[part 1 of 2: package /ComponentTypes]
AUTOSAR XML (schema 00046)
package /ComponentTypes
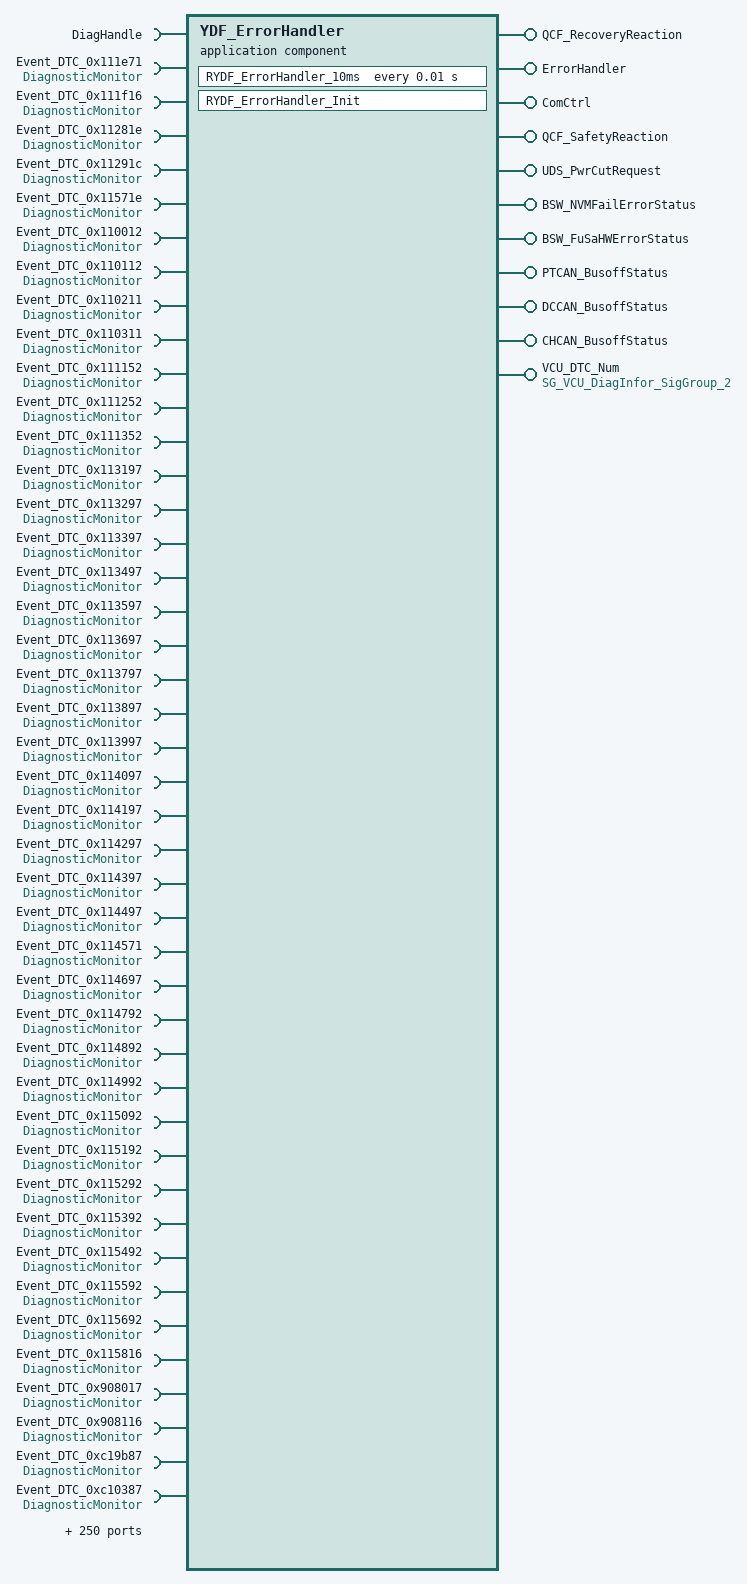
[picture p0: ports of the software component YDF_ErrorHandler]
  application sw component type YDF_ErrorHandler
    provide port QCF_RecoveryReaction: nonqueued-sender-com-spec{data-element=State, init-value=constant-reference=QCF_RECOVERY_REAC_DEFAULT}, provided-interface=QCF_RecoveryReaction
    provide port ErrorHandler: server-com-spec{operation=ReportError, queue-length=1}, provided-interface=ErrorHandler
    require port DiagHandle: required-com-specs=[SetEventSts, GetEventSts], required-interface=DiagHandle
    provide port ComCtrl: nonqueued-sender-com-spec=ComState, provided-interface=ComCtrl
    provide port QCF_SafetyReaction: nonqueued-sender-com-spec{data-element=State, init-value=constant-reference=QCF_SAFETY_REAC_DEFAULT}, provided-interface=QCF_SafetyReaction
    166 x require port:
      Event_DTC_0x111e71: required-interface=DiagnosticMonitor
        required-com-specs:
          GetEventExtendedDataRecordEx
          GetEventFreezeFrameDataEx
          GetFaultDetectionCounter
          GetDTCOfEvent
          GetEventTested
          GetEventFailed
          GetEventStatus
          GetEventUdsStatus
          ResetEventDebounceStatus
          ResetEventStatus
          SetEventStatus
      Event_DTC_0x111f16: required-interface=DiagnosticMonitor
        required-com-specs:
          GetEventExtendedDataRecordEx
          GetEventFreezeFrameDataEx
          GetFaultDetectionCounter
          GetDTCOfEvent
          GetEventTested
          GetEventFailed
          GetEventStatus
          GetEventUdsStatus
          ResetEventDebounceStatus
          ResetEventStatus
          SetEventStatus
      Event_DTC_0x11281e: required-interface=DiagnosticMonitor
        required-com-specs:
          GetEventExtendedDataRecordEx
          GetEventFreezeFrameDataEx
          GetFaultDetectionCounter
          GetDTCOfEvent
          GetEventTested
          GetEventFailed
          GetEventStatus
          GetEventUdsStatus
          ResetEventDebounceStatus
          ResetEventStatus
          SetEventStatus
      Event_DTC_0x11291c: required-interface=DiagnosticMonitor
        required-com-specs:
          GetEventExtendedDataRecordEx
          GetEventFreezeFrameDataEx
          GetFaultDetectionCounter
          GetDTCOfEvent
          GetEventTested
          GetEventFailed
          GetEventStatus
          GetEventUdsStatus
          ResetEventDebounceStatus
          ResetEventStatus
          SetEventStatus
      Event_DTC_0x11571e: required-interface=DiagnosticMonitor
        required-com-specs:
          GetEventExtendedDataRecordEx
          GetEventFreezeFrameDataEx
          GetFaultDetectionCounter
          GetDTCOfEvent
          GetEventTested
          GetEventFailed
          GetEventStatus
          GetEventUdsStatus
          ResetEventDebounceStatus
          ResetEventStatus
          SetEventStatus
      Event_DTC_0x110012: required-interface=DiagnosticMonitor
        required-com-specs:
          GetEventExtendedDataRecordEx
          GetEventFreezeFrameDataEx
          GetFaultDetectionCounter
          GetDTCOfEvent
          GetEventTested
          GetEventFailed
          GetEventStatus
          GetEventUdsStatus
          ResetEventDebounceStatus
          ResetEventStatus
          SetEventStatus
      Event_DTC_0x110112: required-interface=DiagnosticMonitor
        required-com-specs:
          GetEventExtendedDataRecordEx
          GetEventFreezeFrameDataEx
          GetFaultDetectionCounter
          GetDTCOfEvent
          GetEventTested
          GetEventFailed
          GetEventStatus
          GetEventUdsStatus
          ResetEventDebounceStatus
          ResetEventStatus
          SetEventStatus
      Event_DTC_0x110211: required-interface=DiagnosticMonitor
        required-com-specs:
          GetEventExtendedDataRecordEx
          GetEventFreezeFrameDataEx
          GetFaultDetectionCounter
          GetDTCOfEvent
          GetEventTested
          GetEventFailed
          GetEventStatus
          GetEventUdsStatus
          ResetEventDebounceStatus
          ResetEventStatus
          SetEventStatus
      Event_DTC_0x110311: required-interface=DiagnosticMonitor
        required-com-specs:
          GetEventExtendedDataRecordEx
          GetEventFreezeFrameDataEx
          GetFaultDetectionCounter
          GetDTCOfEvent
          GetEventTested
          GetEventFailed
          GetEventStatus
          GetEventUdsStatus
          ResetEventDebounceStatus
          ResetEventStatus
          SetEventStatus
      Event_DTC_0x111152: required-interface=DiagnosticMonitor
        required-com-specs:
          GetEventExtendedDataRecordEx
          GetEventFreezeFrameDataEx
          GetFaultDetectionCounter
          GetDTCOfEvent
          GetEventTested
          GetEventFailed
          GetEventStatus
          GetEventUdsStatus
          ResetEventDebounceStatus
          ResetEventStatus
          SetEventStatus
      Event_DTC_0x111252: required-interface=DiagnosticMonitor
        required-com-specs:
          GetEventExtendedDataRecordEx
          GetEventFreezeFrameDataEx
          GetFaultDetectionCounter
          GetDTCOfEvent
          GetEventTested
          GetEventFailed
          GetEventStatus
          GetEventUdsStatus
          ResetEventDebounceStatus
          ResetEventStatus
          SetEventStatus
      Event_DTC_0x111352: required-interface=DiagnosticMonitor
        required-com-specs:
          GetEventExtendedDataRecordEx
          GetEventFreezeFrameDataEx
          GetFaultDetectionCounter
          GetDTCOfEvent
          GetEventTested
          GetEventFailed
          GetEventStatus
          GetEventUdsStatus
          ResetEventDebounceStatus
          ResetEventStatus
          SetEventStatus
      Event_DTC_0x113197: required-interface=DiagnosticMonitor
        required-com-specs:
          GetEventExtendedDataRecordEx
          GetEventFreezeFrameDataEx
          GetFaultDetectionCounter
          GetDTCOfEvent
          GetEventTested
          GetEventFailed
          GetEventStatus
          GetEventUdsStatus
          ResetEventDebounceStatus
          ResetEventStatus
          SetEventStatus
      Event_DTC_0x113297: required-interface=DiagnosticMonitor
        required-com-specs:
          GetEventExtendedDataRecordEx
          GetEventFreezeFrameDataEx
          GetFaultDetectionCounter
          GetDTCOfEvent
          GetEventTested
          GetEventFailed
          GetEventStatus
          GetEventUdsStatus
          ResetEventDebounceStatus
          ResetEventStatus
          SetEventStatus
      Event_DTC_0x113397: required-interface=DiagnosticMonitor
        required-com-specs:
          GetEventExtendedDataRecordEx
          GetEventFreezeFrameDataEx
          GetFaultDetectionCounter
          GetDTCOfEvent
          GetEventTested
          GetEventFailed
          GetEventStatus
          GetEventUdsStatus
          ResetEventDebounceStatus
          ResetEventStatus
          SetEventStatus
      Event_DTC_0x113497: required-interface=DiagnosticMonitor
        required-com-specs:
          GetEventExtendedDataRecordEx
          GetEventFreezeFrameDataEx
          GetFaultDetectionCounter
          GetDTCOfEvent
          GetEventTested
          GetEventFailed
          GetEventStatus
          GetEventUdsStatus
          ResetEventDebounceStatus
          ResetEventStatus
          SetEventStatus
      Event_DTC_0x113597: required-interface=DiagnosticMonitor
        required-com-specs:
          GetEventExtendedDataRecordEx
          GetEventFreezeFrameDataEx
          GetFaultDetectionCounter
          GetDTCOfEvent
          GetEventTested
          GetEventFailed
          GetEventStatus
          GetEventUdsStatus
          ResetEventDebounceStatus
          ResetEventStatus
          SetEventStatus
      Event_DTC_0x113697: required-interface=DiagnosticMonitor
        required-com-specs:
          GetEventExtendedDataRecordEx
          GetEventFreezeFrameDataEx
          GetFaultDetectionCounter
          GetDTCOfEvent
          GetEventTested
          GetEventFailed
          GetEventStatus
          GetEventUdsStatus
          ResetEventDebounceStatus
          ResetEventStatus
          SetEventStatus
      Event_DTC_0x113797: required-interface=DiagnosticMonitor
        required-com-specs:
          GetEventExtendedDataRecordEx
          GetEventFreezeFrameDataEx
          GetFaultDetectionCounter
          GetDTCOfEvent
          GetEventTested
          GetEventFailed
          GetEventStatus
          GetEventUdsStatus
          ResetEventDebounceStatus
          ResetEventStatus
          SetEventStatus
      Event_DTC_0x113897: required-interface=DiagnosticMonitor
        required-com-specs:
          GetEventExtendedDataRecordEx
          GetEventFreezeFrameDataEx
          GetFaultDetectionCounter
          GetDTCOfEvent
          GetEventTested
          GetEventFailed
          GetEventStatus
          GetEventUdsStatus
          ResetEventDebounceStatus
          ResetEventStatus
          SetEventStatus
      Event_DTC_0x113997: required-interface=DiagnosticMonitor
        required-com-specs:
          GetEventExtendedDataRecordEx
          GetEventFreezeFrameDataEx
          GetFaultDetectionCounter
          GetDTCOfEvent
          GetEventTested
          GetEventFailed
          GetEventStatus
          GetEventUdsStatus
          ResetEventDebounceStatus
          ResetEventStatus
          SetEventStatus
      Event_DTC_0x114097: required-interface=DiagnosticMonitor
        required-com-specs:
          GetEventExtendedDataRecordEx
          GetEventFreezeFrameDataEx
          GetFaultDetectionCounter
          GetDTCOfEvent
          GetEventTested
          GetEventFailed
          GetEventStatus
          GetEventUdsStatus
          ResetEventDebounceStatus
          ResetEventStatus
          SetEventStatus
      Event_DTC_0x114197: required-interface=DiagnosticMonitor
        required-com-specs:
          GetEventExtendedDataRecordEx
          GetEventFreezeFrameDataEx
          GetFaultDetectionCounter
          GetDTCOfEvent
          GetEventTested
          GetEventFailed
          GetEventStatus
          GetEventUdsStatus
          ResetEventDebounceStatus
          ResetEventStatus
          SetEventStatus
      Event_DTC_0x114297: required-interface=DiagnosticMonitor
        required-com-specs:
          GetEventExtendedDataRecordEx
          GetEventFreezeFrameDataEx
          GetFaultDetectionCounter
          GetDTCOfEvent
          GetEventTested
          GetEventFailed
          GetEventStatus
          GetEventUdsStatus
          ResetEventDebounceStatus
          ResetEventStatus
          SetEventStatus
      Event_DTC_0x114397: required-interface=DiagnosticMonitor
        required-com-specs:
          GetEventExtendedDataRecordEx
          GetEventFreezeFrameDataEx
          GetFaultDetectionCounter
          GetDTCOfEvent
          GetEventTested
          GetEventFailed
          GetEventStatus
          GetEventUdsStatus
          ResetEventDebounceStatus
          ResetEventStatus
          SetEventStatus
      Event_DTC_0x114497: required-interface=DiagnosticMonitor
        required-com-specs:
          GetEventExtendedDataRecordEx
          GetEventFreezeFrameDataEx
          GetFaultDetectionCounter
          GetDTCOfEvent
          GetEventTested
          GetEventFailed
          GetEventStatus
          GetEventUdsStatus
          ResetEventDebounceStatus
          ResetEventStatus
          SetEventStatus
      Event_DTC_0x114571: required-interface=DiagnosticMonitor
        required-com-specs:
          GetEventExtendedDataRecordEx
          GetEventFreezeFrameDataEx
          GetFaultDetectionCounter
          GetDTCOfEvent
          GetEventTested
          GetEventFailed
          GetEventStatus
          GetEventUdsStatus
          ResetEventDebounceStatus
          ResetEventStatus
          SetEventStatus
      Event_DTC_0x114697: required-interface=DiagnosticMonitor
        required-com-specs:
          GetEventExtendedDataRecordEx
          GetEventFreezeFrameDataEx
          GetFaultDetectionCounter
          GetDTCOfEvent
          GetEventTested
          GetEventFailed
          GetEventStatus
          GetEventUdsStatus
          ResetEventDebounceStatus
          ResetEventStatus
          SetEventStatus
      Event_DTC_0x114792: required-interface=DiagnosticMonitor
        required-com-specs:
          GetEventExtendedDataRecordEx
          GetEventFreezeFrameDataEx
          GetFaultDetectionCounter
          GetDTCOfEvent
          GetEventTested
          GetEventFailed
          GetEventStatus
          GetEventUdsStatus
          ResetEventDebounceStatus
          ResetEventStatus
          SetEventStatus
      Event_DTC_0x114892: required-interface=DiagnosticMonitor
        required-com-specs:
          GetEventExtendedDataRecordEx
          GetEventFreezeFrameDataEx
          GetFaultDetectionCounter
          GetDTCOfEvent
          GetEventTested
          GetEventFailed
          GetEventStatus
          GetEventUdsStatus
          ResetEventDebounceStatus
          ResetEventStatus
          SetEventStatus
      Event_DTC_0x114992: required-interface=DiagnosticMonitor
        required-com-specs:
          GetEventExtendedDataRecordEx
          GetEventFreezeFrameDataEx
          GetFaultDetectionCounter
          GetDTCOfEvent
          GetEventTested
          GetEventFailed
          GetEventStatus
          GetEventUdsStatus
          ResetEventDebounceStatus
          ResetEventStatus
          SetEventStatus
      Event_DTC_0x115092: required-interface=DiagnosticMonitor
        required-com-specs:
          GetEventExtendedDataRecordEx
          GetEventFreezeFrameDataEx
          GetFaultDetectionCounter
          GetDTCOfEvent
          GetEventTested
          GetEventFailed
          GetEventStatus
          GetEventUdsStatus
          ResetEventDebounceStatus
          ResetEventStatus
          SetEventStatus
      Event_DTC_0x115192: required-interface=DiagnosticMonitor
        required-com-specs:
          GetEventExtendedDataRecordEx
          GetEventFreezeFrameDataEx
          GetFaultDetectionCounter
          GetDTCOfEvent
          GetEventTested
          GetEventFailed
          GetEventStatus
          GetEventUdsStatus
          ResetEventDebounceStatus
          ResetEventStatus
          SetEventStatus
      Event_DTC_0x115292: required-interface=DiagnosticMonitor
        required-com-specs:
          GetEventExtendedDataRecordEx
          GetEventFreezeFrameDataEx
          GetFaultDetectionCounter
          GetDTCOfEvent
          GetEventTested
          GetEventFailed
          GetEventStatus
          GetEventUdsStatus
          ResetEventDebounceStatus
          ResetEventStatus
          SetEventStatus
      Event_DTC_0x115392: required-interface=DiagnosticMonitor
        required-com-specs:
          GetEventExtendedDataRecordEx
          GetEventFreezeFrameDataEx
          GetFaultDetectionCounter
          GetDTCOfEvent
          GetEventTested
          GetEventFailed
          GetEventStatus
          GetEventUdsStatus
          ResetEventDebounceStatus
          ResetEventStatus
          SetEventStatus
      Event_DTC_0x115492: required-interface=DiagnosticMonitor
        required-com-specs:
          GetEventExtendedDataRecordEx
          GetEventFreezeFrameDataEx
          GetFaultDetectionCounter
          GetDTCOfEvent
          GetEventTested
          GetEventFailed
          GetEventStatus
          GetEventUdsStatus
          ResetEventDebounceStatus
          ResetEventStatus
          SetEventStatus
      Event_DTC_0x115592: required-interface=DiagnosticMonitor
        required-com-specs:
          GetEventExtendedDataRecordEx
          GetEventFreezeFrameDataEx
          GetFaultDetectionCounter
          GetDTCOfEvent
          GetEventTested
          GetEventFailed
          GetEventStatus
          GetEventUdsStatus
          ResetEventDebounceStatus
          ResetEventStatus
          SetEventStatus
      Event_DTC_0x115692: required-interface=DiagnosticMonitor
        required-com-specs:
          GetEventExtendedDataRecordEx
          GetEventFreezeFrameDataEx
          GetFaultDetectionCounter
          GetDTCOfEvent
          GetEventTested
          GetEventFailed
          GetEventStatus
          GetEventUdsStatus
          ResetEventDebounceStatus
          ResetEventStatus
          SetEventStatus
      Event_DTC_0x115816: required-interface=DiagnosticMonitor
        required-com-specs:
          GetEventExtendedDataRecordEx
          GetEventFreezeFrameDataEx
          GetFaultDetectionCounter
          GetDTCOfEvent
          GetEventTested
          GetEventFailed
          GetEventStatus
          GetEventUdsStatus
          ResetEventDebounceStatus
          ResetEventStatus
          SetEventStatus
      Event_DTC_0x908017: required-interface=DiagnosticMonitor
        required-com-specs:
          GetEventExtendedDataRecordEx
          GetEventFreezeFrameDataEx
          GetFaultDetectionCounter
          GetDTCOfEvent
          GetEventTested
          GetEventFailed
          GetEventStatus
          GetEventUdsStatus
          ResetEventDebounceStatus
          ResetEventStatus
          SetEventStatus
      Event_DTC_0x908116: required-interface=DiagnosticMonitor
        required-com-specs:
          GetEventExtendedDataRecordEx
          GetEventFreezeFrameDataEx
          GetFaultDetectionCounter
          GetDTCOfEvent
          GetEventTested
          GetEventFailed
          GetEventStatus
          GetEventUdsStatus
          ResetEventDebounceStatus
          ResetEventStatus
          SetEventStatus
      Event_DTC_0xc19b87: required-interface=DiagnosticMonitor
        required-com-specs:
          GetEventExtendedDataRecordEx
          GetEventFreezeFrameDataEx
          GetFaultDetectionCounter
          GetDTCOfEvent
          GetEventTested
          GetEventFailed
          GetEventStatus
          GetEventUdsStatus
          ResetEventDebounceStatus
          ResetEventStatus
          SetEventStatus
      Event_DTC_0xc10387: required-interface=DiagnosticMonitor
        required-com-specs:
          GetEventExtendedDataRecordEx
          GetEventFreezeFrameDataEx
          GetFaultDetectionCounter
          GetDTCOfEvent
          GetEventTested
          GetEventFailed
          GetEventStatus
          GetEventUdsStatus
          ResetEventDebounceStatus
          ResetEventStatus
          SetEventStatus
      Event_DTC_0xc11087: required-interface=DiagnosticMonitor
        required-com-specs:
          GetEventExtendedDataRecordEx
          GetEventFreezeFrameDataEx
          GetFaultDetectionCounter
          GetDTCOfEvent
          GetEventTested
          GetEventFailed
          GetEventStatus
          GetEventUdsStatus
          ResetEventDebounceStatus
          ResetEventStatus
          SetEventStatus
      Event_DTC_0xc11187: required-interface=DiagnosticMonitor
        required-com-specs:
          GetEventExtendedDataRecordEx
          GetEventFreezeFrameDataEx
          GetFaultDetectionCounter
          GetDTCOfEvent
          GetEventTested
          GetEventFailed
          GetEventStatus
          GetEventUdsStatus
          ResetEventDebounceStatus
          ResetEventStatus
          SetEventStatus
      Event_DTC_0xc12987: required-interface=DiagnosticMonitor
        required-com-specs:
          GetEventExtendedDataRecordEx
          GetEventFreezeFrameDataEx
          GetFaultDetectionCounter
          GetDTCOfEvent
          GetEventTested
          GetEventFailed
          GetEventStatus
          GetEventUdsStatus
          ResetEventDebounceStatus
          ResetEventStatus
          SetEventStatus
      Event_DTC_0xc14087: required-interface=DiagnosticMonitor
        required-com-specs:
          GetEventExtendedDataRecordEx
          GetEventFreezeFrameDataEx
          GetFaultDetectionCounter
          GetDTCOfEvent
          GetEventTested
          GetEventFailed
          GetEventStatus
          GetEventUdsStatus
          ResetEventDebounceStatus
          ResetEventStatus
          SetEventStatus
      Event_DTC_0xc14787: required-interface=DiagnosticMonitor
        required-com-specs:
          GetEventExtendedDataRecordEx
          GetEventFreezeFrameDataEx
          GetFaultDetectionCounter
          GetDTCOfEvent
          GetEventTested
          GetEventFailed
          GetEventStatus
          GetEventUdsStatus
          ResetEventDebounceStatus
          ResetEventStatus
          SetEventStatus
      Event_DTC_0xc16687: required-interface=DiagnosticMonitor
        required-com-specs:
          GetEventExtendedDataRecordEx
          GetEventFreezeFrameDataEx
          GetFaultDetectionCounter
          GetDTCOfEvent
          GetEventTested
          GetEventFailed
          GetEventStatus
          GetEventUdsStatus
          ResetEventDebounceStatus
          ResetEventStatus
          SetEventStatus
      Event_DTC_0xc19687: required-interface=DiagnosticMonitor
        required-com-specs:
          GetEventExtendedDataRecordEx
          GetEventFreezeFrameDataEx
          GetFaultDetectionCounter
          GetDTCOfEvent
          GetEventTested
          GetEventFailed
          GetEventStatus
          GetEventUdsStatus
          ResetEventDebounceStatus
          ResetEventStatus
          SetEventStatus
      Event_DTC_0xc19987: required-interface=DiagnosticMonitor
        required-com-specs:
          GetEventExtendedDataRecordEx
          GetEventFreezeFrameDataEx
          GetFaultDetectionCounter
          GetDTCOfEvent
          GetEventTested
          GetEventFailed
          GetEventStatus
          GetEventUdsStatus
          ResetEventDebounceStatus
          ResetEventStatus
          SetEventStatus
      Event_DTC_0xc29887: required-interface=DiagnosticMonitor
        required-com-specs:
          GetEventExtendedDataRecordEx
          GetEventFreezeFrameDataEx
          GetFaultDetectionCounter
          GetDTCOfEvent
          GetEventTested
          GetEventFailed
          GetEventStatus
          GetEventUdsStatus
          ResetEventDebounceStatus
          ResetEventStatus
          SetEventStatus
      Event_DTC_0xd10587: required-interface=DiagnosticMonitor
        required-com-specs:
          GetEventExtendedDataRecordEx
          GetEventFreezeFrameDataEx
          GetFaultDetectionCounter
          GetDTCOfEvent
          GetEventTested
          GetEventFailed
          GetEventStatus
          GetEventUdsStatus
          ResetEventDebounceStatus
          ResetEventStatus
          SetEventStatus
      Event_DTC_0xd13787: required-interface=DiagnosticMonitor
        required-com-specs:
          GetEventExtendedDataRecordEx
          GetEventFreezeFrameDataEx
          GetFaultDetectionCounter
          GetDTCOfEvent
          GetEventTested
          GetEventFailed
          GetEventStatus
          GetEventUdsStatus
          ResetEventDebounceStatus
          ResetEventStatus
          SetEventStatus
      EvtInfo_DTC_0xd13787: required-interface=DiagnosticInfo
        required-com-specs:
          GetMonitorStatus
          GetDebouncingOfEvent
          GetEventEnableCondition
          GetEventExtendedDataRecordEx
          GetEventFreezeFrameDataEx
          GetFaultDetectionCounter
          GetDTCOfEvent
          GetEventTested
          GetEventFailed
          GetEventStatus
          GetEventUdsStatus
      Event_DTC_0xd11b87: required-interface=DiagnosticMonitor
        required-com-specs:
          GetEventExtendedDataRecordEx
          GetEventFreezeFrameDataEx
          GetFaultDetectionCounter
          GetDTCOfEvent
          GetEventTested
          GetEventFailed
          GetEventStatus
          GetEventUdsStatus
          ResetEventDebounceStatus
          ResetEventStatus
          SetEventStatus
      EvtInfo_DTC_0xd11b87: required-interface=DiagnosticInfo
        required-com-specs:
          GetMonitorStatus
          GetDebouncingOfEvent
          GetEventEnableCondition
          GetEventExtendedDataRecordEx
          GetEventFreezeFrameDataEx
          GetFaultDetectionCounter
          GetDTCOfEvent
          GetEventTested
          GetEventFailed
          GetEventStatus
          GetEventUdsStatus
      EvtInfo_DTC_0xd30087: required-interface=DiagnosticInfo
        required-com-specs:
          GetMonitorStatus
          GetDebouncingOfEvent
          GetEventEnableCondition
          GetEventExtendedDataRecordEx
          GetEventFreezeFrameDataEx
          GetFaultDetectionCounter
          GetDTCOfEvent
          GetEventTested
          GetEventFailed
          GetEventStatus
          GetEventUdsStatus
      Event_DTC_0xd30087: required-interface=DiagnosticMonitor
        required-com-specs:
          GetEventExtendedDataRecordEx
          GetEventFreezeFrameDataEx
          GetFaultDetectionCounter
          GetDTCOfEvent
          GetEventTested
          GetEventFailed
          GetEventStatus
          GetEventUdsStatus
          ResetEventDebounceStatus
          ResetEventStatus
          SetEventStatus
      EvtInfo_DTC_0xc14687: required-interface=DiagnosticInfo
        required-com-specs:
          GetMonitorStatus
          GetDebouncingOfEvent
          GetEventEnableCondition
          GetEventExtendedDataRecordEx
          GetEventFreezeFrameDataEx
          GetFaultDetectionCounter
          GetDTCOfEvent
          GetEventTested
          GetEventFailed
          GetEventStatus
          GetEventUdsStatus
      Event_DTC_0xc14687: required-interface=DiagnosticMonitor
        required-com-specs:
          GetEventExtendedDataRecordEx
          GetEventFreezeFrameDataEx
          GetFaultDetectionCounter
          GetDTCOfEvent
          GetEventTested
          GetEventFailed
          GetEventStatus
          GetEventUdsStatus
          ResetEventDebounceStatus
          ResetEventStatus
          SetEventStatus
      EvtInfo_DTC_0xc10f87: required-interface=DiagnosticInfo
        required-com-specs:
          GetMonitorStatus
          GetDebouncingOfEvent
          GetEventEnableCondition
          GetEventExtendedDataRecordEx
          GetEventFreezeFrameDataEx
          GetFaultDetectionCounter
          GetDTCOfEvent
          GetEventTested
          GetEventFailed
          GetEventStatus
          GetEventUdsStatus
      Event_DTC_0xc10f87: required-interface=DiagnosticMonitor
        required-com-specs:
          GetEventExtendedDataRecordEx
          GetEventFreezeFrameDataEx
          GetFaultDetectionCounter
          GetDTCOfEvent
          GetEventTested
          GetEventFailed
          GetEventStatus
          GetEventUdsStatus
          ResetEventDebounceStatus
          ResetEventStatus
          SetEventStatus
      EvtInfo_DTC_0xc16b87: required-interface=DiagnosticInfo
        required-com-specs:
          GetMonitorStatus
          GetDebouncingOfEvent
          GetEventEnableCondition
          GetEventExtendedDataRecordEx
          GetEventFreezeFrameDataEx
          GetFaultDetectionCounter
          GetDTCOfEvent
          GetEventTested
          GetEventFailed
          GetEventStatus
          GetEventUdsStatus
      Event_DTC_0xc16b87: required-interface=DiagnosticMonitor
        required-com-specs:
          GetEventExtendedDataRecordEx
          GetEventFreezeFrameDataEx
          GetFaultDetectionCounter
          GetDTCOfEvent
          GetEventTested
          GetEventFailed
          GetEventStatus
          GetEventUdsStatus
          ResetEventDebounceStatus
          ResetEventStatus
          SetEventStatus
      EvtInfo_DTC_0x908255: required-interface=DiagnosticInfo
        required-com-specs:
          GetMonitorStatus
          GetDebouncingOfEvent
          GetEventEnableCondition
          GetEventExtendedDataRecordEx
          GetEventFreezeFrameDataEx
          GetFaultDetectionCounter
          GetDTCOfEvent
          GetEventTested
          GetEventFailed
          GetEventStatus
          GetEventUdsStatus
      Event_DTC_0x908255: required-interface=DiagnosticMonitor
        required-com-specs:
          GetEventExtendedDataRecordEx
          GetEventFreezeFrameDataEx
          GetFaultDetectionCounter
          GetDTCOfEvent
          GetEventTested
          GetEventFailed
          GetEventStatus
          GetEventUdsStatus
          ResetEventDebounceStatus
          ResetEventStatus
          SetEventStatus
      EvtInfo_DTC_0x908356: required-interface=DiagnosticInfo
        required-com-specs:
          GetMonitorStatus
          GetDebouncingOfEvent
          GetEventEnableCondition
          GetEventExtendedDataRecordEx
          GetEventFreezeFrameDataEx
          GetFaultDetectionCounter
          GetDTCOfEvent
          GetEventTested
          GetEventFailed
          GetEventStatus
          GetEventUdsStatus
      Event_DTC_0x908356: required-interface=DiagnosticMonitor
        required-com-specs:
          GetEventExtendedDataRecordEx
          GetEventFreezeFrameDataEx
          GetFaultDetectionCounter
          GetDTCOfEvent
          GetEventTested
          GetEventFailed
          GetEventStatus
          GetEventUdsStatus
          ResetEventDebounceStatus
          ResetEventStatus
          SetEventStatus
      EvtInfo_DTC_0x117097: required-interface=DiagnosticInfo
        required-com-specs:
          GetMonitorStatus
          GetDebouncingOfEvent
          GetEventEnableCondition
          GetEventExtendedDataRecordEx
          GetEventFreezeFrameDataEx
          GetFaultDetectionCounter
          GetDTCOfEvent
          GetEventTested
          GetEventFailed
          GetEventStatus
          GetEventUdsStatus
      Event_DTC_0x117097: required-interface=DiagnosticMonitor
        required-com-specs:
          GetEventExtendedDataRecordEx
          GetEventFreezeFrameDataEx
          GetFaultDetectionCounter
          GetDTCOfEvent
          GetEventTested
          GetEventFailed
          GetEventStatus
          GetEventUdsStatus
          ResetEventDebounceStatus
          ResetEventStatus
          SetEventStatus
      EvtInfo_DTC_0x116097: required-interface=DiagnosticInfo
        required-com-specs:
          GetMonitorStatus
          GetDebouncingOfEvent
          GetEventEnableCondition
          GetEventExtendedDataRecordEx
          GetEventFreezeFrameDataEx
          GetFaultDetectionCounter
          GetDTCOfEvent
          GetEventTested
          GetEventFailed
          GetEventStatus
          GetEventUdsStatus
      Event_DTC_0x116097: required-interface=DiagnosticMonitor
        required-com-specs:
          GetEventExtendedDataRecordEx
          GetEventFreezeFrameDataEx
          GetFaultDetectionCounter
          GetDTCOfEvent
          GetEventTested
          GetEventFailed
          GetEventStatus
          GetEventUdsStatus
          ResetEventDebounceStatus
          ResetEventStatus
          SetEventStatus
      EvtInfo_DTC_0x115c4b: required-interface=DiagnosticInfo
        required-com-specs:
          GetMonitorStatus
          GetDebouncingOfEvent
          GetEventEnableCondition
          GetEventExtendedDataRecordEx
          GetEventFreezeFrameDataEx
          GetFaultDetectionCounter
          GetDTCOfEvent
          GetEventTested
          GetEventFailed
          GetEventStatus
          GetEventUdsStatus
      Event_DTC_0x115c4b: required-interface=DiagnosticMonitor
        required-com-specs:
          GetEventExtendedDataRecordEx
          GetEventFreezeFrameDataEx
          GetFaultDetectionCounter
          GetDTCOfEvent
          GetEventTested
          GetEventFailed
          GetEventStatus
          GetEventUdsStatus
          ResetEventDebounceStatus
          ResetEventStatus
          SetEventStatus
      EvtInfo_DTC_0x115d4b: required-interface=DiagnosticInfo
        required-com-specs:
          GetMonitorStatus
          GetDebouncingOfEvent
          GetEventEnableCondition
          GetEventExtendedDataRecordEx
          GetEventFreezeFrameDataEx
          GetFaultDetectionCounter
          GetDTCOfEvent
          GetEventTested
          GetEventFailed
          GetEventStatus
          GetEventUdsStatus
      Event_DTC_0x115d4b: required-interface=DiagnosticMonitor
        required-com-specs:
          GetEventExtendedDataRecordEx
          GetEventFreezeFrameDataEx
          GetFaultDetectionCounter
          GetDTCOfEvent
          GetEventTested
          GetEventFailed
          GetEventStatus
          GetEventUdsStatus
          ResetEventDebounceStatus
          ResetEventStatus
          SetEventStatus
      EvtInfo_DTC_0x117197: required-interface=DiagnosticInfo
        required-com-specs:
          GetMonitorStatus
          GetDebouncingOfEvent
          GetEventEnableCondition
          GetEventExtendedDataRecordEx
          GetEventFreezeFrameDataEx
          GetFaultDetectionCounter
          GetDTCOfEvent
          GetEventTested
          GetEventFailed
          GetEventStatus
          GetEventUdsStatus
      Event_DTC_0x117197: required-interface=DiagnosticMonitor
        required-com-specs:
          GetEventExtendedDataRecordEx
          GetEventFreezeFrameDataEx
          GetFaultDetectionCounter
          GetDTCOfEvent
          GetEventTested
          GetEventFailed
          GetEventStatus
          GetEventUdsStatus
          ResetEventDebounceStatus
          ResetEventStatus
          SetEventStatus
      EvtInfo_DTC_0x115e1a: required-interface=DiagnosticInfo
        required-com-specs:
          GetMonitorStatus
          GetDebouncingOfEvent
          GetEventEnableCondition
          GetEventExtendedDataRecordEx
          GetEventFreezeFrameDataEx
          GetFaultDetectionCounter
          GetDTCOfEvent
          GetEventTested
          GetEventFailed
          GetEventStatus
          GetEventUdsStatus
      Event_DTC_0x115e1a: required-interface=DiagnosticMonitor
        required-com-specs:
          GetEventExtendedDataRecordEx
          GetEventFreezeFrameDataEx
          GetFaultDetectionCounter
          GetDTCOfEvent
          GetEventTested
          GetEventFailed
          GetEventStatus
          GetEventUdsStatus
          ResetEventDebounceStatus
          ResetEventStatus
          SetEventStatus
      EvtInfo_DTC_0x116197: required-interface=DiagnosticInfo
        required-com-specs:
          GetMonitorStatus
          GetDebouncingOfEvent
          GetEventEnableCondition
          GetEventExtendedDataRecordEx
          GetEventFreezeFrameDataEx
          GetFaultDetectionCounter
          GetDTCOfEvent
          GetEventTested
          GetEventFailed
          GetEventStatus
          GetEventUdsStatus
      Event_DTC_0x116197: required-interface=DiagnosticMonitor
        required-com-specs:
          GetEventExtendedDataRecordEx
          GetEventFreezeFrameDataEx
          GetFaultDetectionCounter
          GetDTCOfEvent
          GetEventTested
          GetEventFailed
          GetEventStatus
          GetEventUdsStatus
          ResetEventDebounceStatus
          ResetEventStatus
          SetEventStatus
      EvtInfo_DTC_0x115a92: required-interface=DiagnosticInfo
        required-com-specs:
          GetMonitorStatus
          GetDebouncingOfEvent
          GetEventEnableCondition
          GetEventExtendedDataRecordEx
          GetEventFreezeFrameDataEx
          GetFaultDetectionCounter
          GetDTCOfEvent
          GetEventTested
          GetEventFailed
          GetEventStatus
          GetEventUdsStatus
      Event_DTC_0x115a92: required-interface=DiagnosticMonitor
        required-com-specs:
          GetEventExtendedDataRecordEx
          GetEventFreezeFrameDataEx
          GetFaultDetectionCounter
          GetDTCOfEvent
          GetEventTested
          GetEventFailed
          GetEventStatus
          GetEventUdsStatus
          ResetEventDebounceStatus
          ResetEventStatus
          SetEventStatus
      EvtInfo_DTC_0x11611c: required-interface=DiagnosticInfo
        required-com-specs:
          GetMonitorStatus
          GetDebouncingOfEvent
          GetEventEnableCondition
          GetEventExtendedDataRecordEx
          GetEventFreezeFrameDataEx
          GetFaultDetectionCounter
          GetDTCOfEvent
          GetEventTested
          GetEventFailed
          GetEventStatus
          GetEventUdsStatus
      Event_DTC_0x11611c: required-interface=DiagnosticMonitor
        required-com-specs:
          GetEventExtendedDataRecordEx
          GetEventFreezeFrameDataEx
          GetFaultDetectionCounter
          GetDTCOfEvent
          GetEventTested
          GetEventFailed
          GetEventStatus
          GetEventUdsStatus
          ResetEventDebounceStatus
          ResetEventStatus
          SetEventStatus
      EvtInfo_DTC_0x11621c: required-interface=DiagnosticInfo
        required-com-specs:
          GetMonitorStatus
          GetDebouncingOfEvent
          GetEventEnableCondition
          GetEventExtendedDataRecordEx
          GetEventFreezeFrameDataEx
          GetFaultDetectionCounter
          GetDTCOfEvent
          GetEventTested
          GetEventFailed
          GetEventStatus
          GetEventUdsStatus
      Event_DTC_0x11621c: required-interface=DiagnosticMonitor
        required-com-specs:
          GetEventExtendedDataRecordEx
          GetEventFreezeFrameDataEx
          GetFaultDetectionCounter
          GetDTCOfEvent
          GetEventTested
          GetEventFailed
          GetEventStatus
          GetEventUdsStatus
          ResetEventDebounceStatus
          ResetEventStatus
          SetEventStatus
      EvtInfo_DTC_0x116494: required-interface=DiagnosticInfo
        required-com-specs:
          GetMonitorStatus
          GetDebouncingOfEvent
          GetEventEnableCondition
          GetEventExtendedDataRecordEx
          GetEventFreezeFrameDataEx
          GetFaultDetectionCounter
          GetDTCOfEvent
          GetEventTested
          GetEventFailed
          GetEventStatus
          GetEventUdsStatus
      Event_DTC_0x116494: required-interface=DiagnosticMonitor
        required-com-specs:
          GetEventExtendedDataRecordEx
          GetEventFreezeFrameDataEx
          GetFaultDetectionCounter
          GetDTCOfEvent
          GetEventTested
          GetEventFailed
          GetEventStatus
          GetEventUdsStatus
          ResetEventDebounceStatus
          ResetEventStatus
          SetEventStatus
      EvtInfo_DTC_0x116594: required-interface=DiagnosticInfo
        required-com-specs:
          GetMonitorStatus
          GetDebouncingOfEvent
          GetEventEnableCondition
          GetEventExtendedDataRecordEx
          GetEventFreezeFrameDataEx
          GetFaultDetectionCounter
          GetDTCOfEvent
          GetEventTested
          GetEventFailed
          GetEventStatus
          GetEventUdsStatus
      Event_DTC_0x116594: required-interface=DiagnosticMonitor
        required-com-specs:
          GetEventExtendedDataRecordEx
          GetEventFreezeFrameDataEx
          GetFaultDetectionCounter
          GetDTCOfEvent
          GetEventTested
          GetEventFailed
          GetEventStatus
          GetEventUdsStatus
          ResetEventDebounceStatus
          ResetEventStatus
          SetEventStatus
      EvtInfo_DTC_0x116397: required-interface=DiagnosticInfo
        required-com-specs:
          GetMonitorStatus
          GetDebouncingOfEvent
          GetEventEnableCondition
          GetEventExtendedDataRecordEx
          GetEventFreezeFrameDataEx
          GetFaultDetectionCounter
          GetDTCOfEvent
          GetEventTested
          GetEventFailed
          GetEventStatus
          GetEventUdsStatus
      Event_DTC_0x116397: required-interface=DiagnosticMonitor
        required-com-specs:
          GetEventExtendedDataRecordEx
          GetEventFreezeFrameDataEx
          GetFaultDetectionCounter
          GetDTCOfEvent
          GetEventTested
          GetEventFailed
          GetEventStatus
          GetEventUdsStatus
          ResetEventDebounceStatus
          ResetEventStatus
          SetEventStatus
      EvtInfo_DTC_0x116617: required-interface=DiagnosticInfo
        required-com-specs:
          GetMonitorStatus
          GetDebouncingOfEvent
          GetEventEnableCondition
          GetEventExtendedDataRecordEx
          GetEventFreezeFrameDataEx
          GetFaultDetectionCounter
          GetDTCOfEvent
          GetEventTested
          GetEventFailed
          GetEventStatus
          GetEventUdsStatus
      Event_DTC_0x116617: required-interface=DiagnosticMonitor
        required-com-specs:
          GetEventExtendedDataRecordEx
          GetEventFreezeFrameDataEx
          GetFaultDetectionCounter
          GetDTCOfEvent
          GetEventTested
          GetEventFailed
          GetEventStatus
          GetEventUdsStatus
          ResetEventDebounceStatus
          ResetEventStatus
          SetEventStatus
      EvtInfo_DTC_0x116716: required-interface=DiagnosticInfo
        required-com-specs:
          GetMonitorStatus
          GetDebouncingOfEvent
          GetEventEnableCondition
          GetEventExtendedDataRecordEx
          GetEventFreezeFrameDataEx
          GetFaultDetectionCounter
          GetDTCOfEvent
          GetEventTested
          GetEventFailed
          GetEventStatus
          GetEventUdsStatus
      Event_DTC_0x116716: required-interface=DiagnosticMonitor
        required-com-specs:
          GetEventExtendedDataRecordEx
          GetEventFreezeFrameDataEx
          GetFaultDetectionCounter
          GetDTCOfEvent
          GetEventTested
          GetEventFailed
          GetEventStatus
          GetEventUdsStatus
          ResetEventDebounceStatus
          ResetEventStatus
          SetEventStatus
      EvtInfo_DTC_0x116819: required-interface=DiagnosticInfo
        required-com-specs:
          GetMonitorStatus
          GetDebouncingOfEvent
          GetEventEnableCondition
          GetEventExtendedDataRecordEx
          GetEventFreezeFrameDataEx
          GetFaultDetectionCounter
          GetDTCOfEvent
          GetEventTested
          GetEventFailed
          GetEventStatus
          GetEventUdsStatus
      Event_DTC_0x116819: required-interface=DiagnosticMonitor
        required-com-specs:
          GetEventExtendedDataRecordEx
          GetEventFreezeFrameDataEx
          GetFaultDetectionCounter
          GetDTCOfEvent
          GetEventTested
          GetEventFailed
          GetEventStatus
          GetEventUdsStatus
          ResetEventDebounceStatus
          ResetEventStatus
          SetEventStatus
      EvtInfo_DTC_0x116996: required-interface=DiagnosticInfo
        required-com-specs:
          GetMonitorStatus
          GetDebouncingOfEvent
          GetEventEnableCondition
          GetEventExtendedDataRecordEx
          GetEventFreezeFrameDataEx
          GetFaultDetectionCounter
          GetDTCOfEvent
          GetEventTested
          GetEventFailed
          GetEventStatus
          GetEventUdsStatus
      Event_DTC_0x116996: required-interface=DiagnosticMonitor
        required-com-specs:
          GetEventExtendedDataRecordEx
          GetEventFreezeFrameDataEx
          GetFaultDetectionCounter
          GetDTCOfEvent
          GetEventTested
          GetEventFailed
          GetEventStatus
          GetEventUdsStatus
          ResetEventDebounceStatus
          ResetEventStatus
          SetEventStatus
      EvtInfo_DTC_0x116a96: required-interface=DiagnosticInfo
        required-com-specs:
          GetMonitorStatus
          GetDebouncingOfEvent
          GetEventEnableCondition
          GetEventExtendedDataRecordEx
          GetEventFreezeFrameDataEx
          GetFaultDetectionCounter
          GetDTCOfEvent
          GetEventTested
          GetEventFailed
          GetEventStatus
          GetEventUdsStatus
      Event_DTC_0x116a96: required-interface=DiagnosticMonitor
        required-com-specs:
          GetEventExtendedDataRecordEx
          GetEventFreezeFrameDataEx
          GetFaultDetectionCounter
          GetDTCOfEvent
          GetEventTested
          GetEventFailed
          GetEventStatus
          GetEventUdsStatus
          ResetEventDebounceStatus
          ResetEventStatus
          SetEventStatus
      EvtInfo_DTC_0x116c05: required-interface=DiagnosticInfo
        required-com-specs:
          GetMonitorStatus
          GetDebouncingOfEvent
          GetEventEnableCondition
          GetEventExtendedDataRecordEx
          GetEventFreezeFrameDataEx
          GetFaultDetectionCounter
          GetDTCOfEvent
          GetEventTested
          GetEventFailed
          GetEventStatus
          GetEventUdsStatus
      Event_DTC_0x116c05: required-interface=DiagnosticMonitor
        required-com-specs:
          GetEventExtendedDataRecordEx
          GetEventFreezeFrameDataEx
          GetFaultDetectionCounter
          GetDTCOfEvent
          GetEventTested
          GetEventFailed
          GetEventStatus
          GetEventUdsStatus
          ResetEventDebounceStatus
          ResetEventStatus
          SetEventStatus
      EvtInfo_DTC_0x116d05: required-interface=DiagnosticInfo
        required-com-specs:
          GetMonitorStatus
          GetDebouncingOfEvent
          GetEventEnableCondition
          GetEventExtendedDataRecordEx
          GetEventFreezeFrameDataEx
          GetFaultDetectionCounter
          GetDTCOfEvent
          GetEventTested
          GetEventFailed
          GetEventStatus
          GetEventUdsStatus
      Event_DTC_0x116d05: required-interface=DiagnosticMonitor
        required-com-specs:
          GetEventExtendedDataRecordEx
          GetEventFreezeFrameDataEx
          GetFaultDetectionCounter
          GetDTCOfEvent
          GetEventTested
          GetEventFailed
          GetEventStatus
          GetEventUdsStatus
          ResetEventDebounceStatus
          ResetEventStatus
          SetEventStatus
      EvtInfo_DTC_0x116e05: required-interface=DiagnosticInfo
        required-com-specs:
          GetMonitorStatus
          GetDebouncingOfEvent
          GetEventEnableCondition
          GetEventExtendedDataRecordEx
          GetEventFreezeFrameDataEx
          GetFaultDetectionCounter
          GetDTCOfEvent
          GetEventTested
          GetEventFailed
          GetEventStatus
          GetEventUdsStatus
      Event_DTC_0x116e05: required-interface=DiagnosticMonitor
        required-com-specs:
          GetEventExtendedDataRecordEx
          GetEventFreezeFrameDataEx
          GetFaultDetectionCounter
          GetDTCOfEvent
          GetEventTested
          GetEventFailed
          GetEventStatus
          GetEventUdsStatus
          ResetEventDebounceStatus
          ResetEventStatus
          SetEventStatus
      EvtInfo_DTC_0x116f05: required-interface=DiagnosticInfo
        required-com-specs:
          GetMonitorStatus
          GetDebouncingOfEvent
          GetEventEnableCondition
          GetEventExtendedDataRecordEx
          GetEventFreezeFrameDataEx
          GetFaultDetectionCounter
          GetDTCOfEvent
          GetEventTested
          GetEventFailed
          GetEventStatus
          GetEventUdsStatus
      Event_DTC_0x116f05: required-interface=DiagnosticMonitor
        required-com-specs:
          GetEventExtendedDataRecordEx
          GetEventFreezeFrameDataEx
          GetFaultDetectionCounter
          GetDTCOfEvent
          GetEventTested
          GetEventFailed
          GetEventStatus
          GetEventUdsStatus
          ResetEventDebounceStatus
          ResetEventStatus
          SetEventStatus
      EvtInfo_DTC_0xc12987: required-interface=DiagnosticInfo
        required-com-specs:
          GetMonitorStatus
          GetDebouncingOfEvent
          GetEventEnableCondition
          GetEventExtendedDataRecordEx
          GetEventFreezeFrameDataEx
          GetFaultDetectionCounter
          GetDTCOfEvent
          GetEventTested
          GetEventFailed
          GetEventStatus
          GetEventUdsStatus
      EvtInfo_DTC_0xd10587: required-interface=DiagnosticInfo
        required-com-specs:
          GetMonitorStatus
          GetDebouncingOfEvent
          GetEventEnableCondition
          GetEventExtendedDataRecordEx
          GetEventFreezeFrameDataEx
          GetFaultDetectionCounter
          GetDTCOfEvent
          GetEventTested
          GetEventFailed
          GetEventStatus
          GetEventUdsStatus
      EvtInfo_DTC_0xc16687: required-interface=DiagnosticInfo
        required-com-specs:
          GetMonitorStatus
          GetDebouncingOfEvent
          GetEventEnableCondition
          GetEventExtendedDataRecordEx
          GetEventFreezeFrameDataEx
          GetFaultDetectionCounter
          GetDTCOfEvent
          GetEventTested
          GetEventFailed
          GetEventStatus
          GetEventUdsStatus
      EvtInfo_DTC_0xc11087: required-interface=DiagnosticInfo
        required-com-specs:
          GetMonitorStatus
          GetDebouncingOfEvent
          GetEventEnableCondition
          GetEventExtendedDataRecordEx
          GetEventFreezeFrameDataEx
          GetFaultDetectionCounter
          GetDTCOfEvent
          GetEventTested
          GetEventFailed
          GetEventStatus
          GetEventUdsStatus
      EvtInfo_DTC_0xc11187: required-interface=DiagnosticInfo
        required-com-specs:
          GetMonitorStatus
          GetDebouncingOfEvent
          GetEventEnableCondition
          GetEventExtendedDataRecordEx
          GetEventFreezeFrameDataEx
          GetFaultDetectionCounter
          GetDTCOfEvent
          GetEventTested
          GetEventFailed
          GetEventStatus
          GetEventUdsStatus
      EvtInfo_DTC_0xc19b87: required-interface=DiagnosticInfo
        required-com-specs:
          GetMonitorStatus
          GetDebouncingOfEvent
          GetEventEnableCondition
          GetEventExtendedDataRecordEx
          GetEventFreezeFrameDataEx
          GetFaultDetectionCounter
          GetDTCOfEvent
          GetEventTested
          GetEventFailed
          GetEventStatus
          GetEventUdsStatus
      EvtInfo_DTC_0xc29887: required-interface=DiagnosticInfo
        required-com-specs:
          GetMonitorStatus
          GetDebouncingOfEvent
          GetEventEnableCondition
          GetEventExtendedDataRecordEx
          GetEventFreezeFrameDataEx
          GetFaultDetectionCounter
          GetDTCOfEvent
          GetEventTested
          GetEventFailed
          GetEventStatus
          GetEventUdsStatus
      EvtInfo_DTC_0xc19687: required-interface=DiagnosticInfo
        required-com-specs:
          GetMonitorStatus
          GetDebouncingOfEvent
          GetEventEnableCondition
          GetEventExtendedDataRecordEx
          GetEventFreezeFrameDataEx
          GetFaultDetectionCounter
          GetDTCOfEvent
          GetEventTested
          GetEventFailed
          GetEventStatus
          GetEventUdsStatus
      EvtInfo_DTC_0xc10387: required-interface=DiagnosticInfo
        required-com-specs:
          GetMonitorStatus
          GetDebouncingOfEvent
          GetEventEnableCondition
          GetEventExtendedDataRecordEx
          GetEventFreezeFrameDataEx
          GetFaultDetectionCounter
          GetDTCOfEvent
          GetEventTested
          GetEventFailed
          GetEventStatus
          GetEventUdsStatus
      EvtInfo_DTC_0xc19987: required-interface=DiagnosticInfo
        required-com-specs:
          GetMonitorStatus
          GetDebouncingOfEvent
          GetEventEnableCondition
          GetEventExtendedDataRecordEx
          GetEventFreezeFrameDataEx
          GetFaultDetectionCounter
          GetDTCOfEvent
          GetEventTested
          GetEventFailed
          GetEventStatus
          GetEventUdsStatus
      EvtInfo_DTC_0xc14087: required-interface=DiagnosticInfo
        required-com-specs:
          GetMonitorStatus
          GetDebouncingOfEvent
          GetEventEnableCondition
          GetEventExtendedDataRecordEx
          GetEventFreezeFrameDataEx
          GetFaultDetectionCounter
          GetDTCOfEvent
          GetEventTested
          GetEventFailed
          GetEventStatus
          GetEventUdsStatus
      EvtInfo_DTC_0xc14787: required-interface=DiagnosticInfo
        required-com-specs:
          GetMonitorStatus
          GetDebouncingOfEvent
          GetEventEnableCondition
          GetEventExtendedDataRecordEx
          GetEventFreezeFrameDataEx
          GetFaultDetectionCounter
          GetDTCOfEvent
          GetEventTested
          GetEventFailed
          GetEventStatus
          GetEventUdsStatus
      EvtInfo_DTC_0x110012: required-interface=DiagnosticInfo
        required-com-specs:
          GetMonitorStatus
          GetDebouncingOfEvent
          GetEventEnableCondition
          GetEventExtendedDataRecordEx
          GetEventFreezeFrameDataEx
          GetFaultDetectionCounter
          GetDTCOfEvent
          GetEventTested
          GetEventFailed
          GetEventStatus
          GetEventUdsStatus
      EvtInfo_DTC_0x110112: required-interface=DiagnosticInfo
        required-com-specs:
          GetMonitorStatus
          GetDebouncingOfEvent
          GetEventEnableCondition
          GetEventExtendedDataRecordEx
          GetEventFreezeFrameDataEx
          GetFaultDetectionCounter
          GetDTCOfEvent
          GetEventTested
          GetEventFailed
          GetEventStatus
          GetEventUdsStatus
      EvtInfo_DTC_0x110211: required-interface=DiagnosticInfo
        required-com-specs:
          GetMonitorStatus
          GetDebouncingOfEvent
          GetEventEnableCondition
          GetEventExtendedDataRecordEx
          GetEventFreezeFrameDataEx
          GetFaultDetectionCounter
          GetDTCOfEvent
          GetEventTested
          GetEventFailed
          GetEventStatus
          GetEventUdsStatus
      EvtInfo_DTC_0x110311: required-interface=DiagnosticInfo
        required-com-specs:
          GetMonitorStatus
          GetDebouncingOfEvent
          GetEventEnableCondition
          GetEventExtendedDataRecordEx
          GetEventFreezeFrameDataEx
          GetFaultDetectionCounter
          GetDTCOfEvent
          GetEventTested
          GetEventFailed
          GetEventStatus
          GetEventUdsStatus
      EvtInfo_DTC_0x908116: required-interface=DiagnosticInfo
        required-com-specs:
          GetMonitorStatus
          GetDebouncingOfEvent
          GetEventEnableCondition
          GetEventExtendedDataRecordEx
          GetEventFreezeFrameDataEx
          GetFaultDetectionCounter
          GetDTCOfEvent
          GetEventTested
          GetEventFailed
          GetEventStatus
          GetEventUdsStatus
      EvtInfo_DTC_0x908017: required-interface=DiagnosticInfo
        required-com-specs:
          GetMonitorStatus
          GetDebouncingOfEvent
          GetEventEnableCondition
          GetEventExtendedDataRecordEx
          GetEventFreezeFrameDataEx
          GetFaultDetectionCounter
          GetDTCOfEvent
          GetEventTested
          GetEventFailed
          GetEventStatus
          GetEventUdsStatus
      EvtInfo_DTC_0x111152: required-interface=DiagnosticInfo
        required-com-specs:
          GetMonitorStatus
          GetDebouncingOfEvent
          GetEventEnableCondition
          GetEventExtendedDataRecordEx
          GetEventFreezeFrameDataEx
          GetFaultDetectionCounter
          GetDTCOfEvent
          GetEventTested
          GetEventFailed
          GetEventStatus
          GetEventUdsStatus
      EvtInfo_DTC_0x111252: required-interface=DiagnosticInfo
        required-com-specs:
          GetMonitorStatus
          GetDebouncingOfEvent
          GetEventEnableCondition
          GetEventExtendedDataRecordEx
          GetEventFreezeFrameDataEx
          GetFaultDetectionCounter
          GetDTCOfEvent
          GetEventTested
          GetEventFailed
          GetEventStatus
          GetEventUdsStatus
      EvtInfo_DTC_0x111e71: required-interface=DiagnosticInfo
        required-com-specs:
          GetMonitorStatus
          GetDebouncingOfEvent
          GetEventEnableCondition
          GetEventExtendedDataRecordEx
          GetEventFreezeFrameDataEx
          GetFaultDetectionCounter
          GetDTCOfEvent
          GetEventTested
          GetEventFailed
          GetEventStatus
          GetEventUdsStatus
      EvtInfo_DTC_0x114571: required-interface=DiagnosticInfo
        required-com-specs:
          GetMonitorStatus
          GetDebouncingOfEvent
          GetEventEnableCondition
          GetEventExtendedDataRecordEx
          GetEventFreezeFrameDataEx
          GetFaultDetectionCounter
          GetDTCOfEvent
          GetEventTested
          GetEventFailed
          GetEventStatus
          GetEventUdsStatus
      EvtInfo_DTC_0x111f16: required-interface=DiagnosticInfo
        required-com-specs:
          GetMonitorStatus
          GetDebouncingOfEvent
          GetEventEnableCondition
          GetEventExtendedDataRecordEx
          GetEventFreezeFrameDataEx
          GetFaultDetectionCounter
          GetDTCOfEvent
          GetEventTested
          GetEventFailed
          GetEventStatus
          GetEventUdsStatus
      EvtInfo_DTC_0x115816: required-interface=DiagnosticInfo
        required-com-specs:
          GetMonitorStatus
          GetDebouncingOfEvent
          GetEventEnableCondition
          GetEventExtendedDataRecordEx
          GetEventFreezeFrameDataEx
          GetFaultDetectionCounter
          GetDTCOfEvent
          GetEventTested
          GetEventFailed
          GetEventStatus
          GetEventUdsStatus
      EvtInfo_DTC_0x113197: required-interface=DiagnosticInfo
        required-com-specs:
          GetMonitorStatus
          GetDebouncingOfEvent
          GetEventEnableCondition
          GetEventExtendedDataRecordEx
          GetEventFreezeFrameDataEx
          GetFaultDetectionCounter
          GetDTCOfEvent
          GetEventTested
          GetEventFailed
          GetEventStatus
          GetEventUdsStatus
      EvtInfo_DTC_0x113297: required-interface=DiagnosticInfo
        required-com-specs:
          GetMonitorStatus
          GetDebouncingOfEvent
          GetEventEnableCondition
          GetEventExtendedDataRecordEx
          GetEventFreezeFrameDataEx
          GetFaultDetectionCounter
          GetDTCOfEvent
          GetEventTested
          GetEventFailed
          GetEventStatus
          GetEventUdsStatus
      EvtInfo_DTC_0x113397: required-interface=DiagnosticInfo
        required-com-specs:
          GetMonitorStatus
          GetDebouncingOfEvent
          GetEventEnableCondition
          GetEventExtendedDataRecordEx
          GetEventFreezeFrameDataEx
          GetFaultDetectionCounter
          GetDTCOfEvent
          GetEventTested
          GetEventFailed
          GetEventStatus
          GetEventUdsStatus
      EvtInfo_DTC_0x113497: required-interface=DiagnosticInfo
        required-com-specs:
          GetMonitorStatus
          GetDebouncingOfEvent
          GetEventEnableCondition
          GetEventExtendedDataRecordEx
          GetEventFreezeFrameDataEx
          GetFaultDetectionCounter
          GetDTCOfEvent
          GetEventTested
          GetEventFailed
          GetEventStatus
          GetEventUdsStatus
      EvtInfo_DTC_0x113697: required-interface=DiagnosticInfo
        required-com-specs:
          GetMonitorStatus
          GetDebouncingOfEvent
          GetEventEnableCondition
          GetEventExtendedDataRecordEx
          GetEventFreezeFrameDataEx
          GetFaultDetectionCounter
          GetDTCOfEvent
          GetEventTested
          GetEventFailed
          GetEventStatus
          GetEventUdsStatus
      EvtInfo_DTC_0x113897: required-interface=DiagnosticInfo
        required-com-specs:
          GetMonitorStatus
          GetDebouncingOfEvent
          GetEventEnableCondition
          GetEventExtendedDataRecordEx
          GetEventFreezeFrameDataEx
          GetFaultDetectionCounter
          GetDTCOfEvent
          GetEventTested
          GetEventFailed
          GetEventStatus
          GetEventUdsStatus
      EvtInfo_DTC_0x113997: required-interface=DiagnosticInfo
        required-com-specs:
          GetMonitorStatus
          GetDebouncingOfEvent
          GetEventEnableCondition
          GetEventExtendedDataRecordEx
          GetEventFreezeFrameDataEx
          GetFaultDetectionCounter
          GetDTCOfEvent
          GetEventTested
          GetEventFailed
          GetEventStatus
          GetEventUdsStatus
      EvtInfo_DTC_0x114097: required-interface=DiagnosticInfo
        required-com-specs:
          GetMonitorStatus
          GetDebouncingOfEvent
          GetEventEnableCondition
          GetEventExtendedDataRecordEx
          GetEventFreezeFrameDataEx
          GetFaultDetectionCounter
          GetDTCOfEvent
          GetEventTested
          GetEventFailed
          GetEventStatus
          GetEventUdsStatus
      EvtInfo_DTC_0x114197: required-interface=DiagnosticInfo
        required-com-specs:
          GetMonitorStatus
          GetDebouncingOfEvent
          GetEventEnableCondition
          GetEventExtendedDataRecordEx
          GetEventFreezeFrameDataEx
          GetFaultDetectionCounter
          GetDTCOfEvent
          GetEventTested
          GetEventFailed
          GetEventStatus
          GetEventUdsStatus
      EvtInfo_DTC_0x114297: required-interface=DiagnosticInfo
        required-com-specs:
          GetMonitorStatus
          GetDebouncingOfEvent
          GetEventEnableCondition
          GetEventExtendedDataRecordEx
          GetEventFreezeFrameDataEx
          GetFaultDetectionCounter
          GetDTCOfEvent
          GetEventTested
          GetEventFailed
          GetEventStatus
          GetEventUdsStatus
      EvtInfo_DTC_0x114397: required-interface=DiagnosticInfo
        required-com-specs:
          GetMonitorStatus
          GetDebouncingOfEvent
          GetEventEnableCondition
          GetEventExtendedDataRecordEx
          GetEventFreezeFrameDataEx
          GetFaultDetectionCounter
          GetDTCOfEvent
          GetEventTested
          GetEventFailed
          GetEventStatus
          GetEventUdsStatus
      EvtInfo_DTC_0x114497: required-interface=DiagnosticInfo
        required-com-specs:
          GetMonitorStatus
          GetDebouncingOfEvent
          GetEventEnableCondition
          GetEventExtendedDataRecordEx
          GetEventFreezeFrameDataEx
          GetFaultDetectionCounter
          GetDTCOfEvent
          GetEventTested
          GetEventFailed
          GetEventStatus
          GetEventUdsStatus
      EvtInfo_DTC_0x11281e: required-interface=DiagnosticInfo
        required-com-specs:
          GetMonitorStatus
          GetDebouncingOfEvent
          GetEventEnableCondition
          GetEventExtendedDataRecordEx
          GetEventFreezeFrameDataEx
          GetFaultDetectionCounter
          GetDTCOfEvent
          GetEventTested
          GetEventFailed
          GetEventStatus
          GetEventUdsStatus
      EvtInfo_DTC_0x113797: required-interface=DiagnosticInfo
        required-com-specs:
          GetMonitorStatus
          GetDebouncingOfEvent
          GetEventEnableCondition
          GetEventExtendedDataRecordEx
          GetEventFreezeFrameDataEx
          GetFaultDetectionCounter
          GetDTCOfEvent
          GetEventTested
          GetEventFailed
          GetEventStatus
          GetEventUdsStatus
      EvtInfo_DTC_0x11291c: required-interface=DiagnosticInfo
        required-com-specs:
          GetMonitorStatus
          GetDebouncingOfEvent
          GetEventEnableCondition
          GetEventExtendedDataRecordEx
          GetEventFreezeFrameDataEx
          GetFaultDetectionCounter
          GetDTCOfEvent
          GetEventTested
          GetEventFailed
          GetEventStatus
          GetEventUdsStatus
      EvtInfo_DTC_0x114697: required-interface=DiagnosticInfo
        required-com-specs:
          GetMonitorStatus
          GetDebouncingOfEvent
          GetEventEnableCondition
          GetEventExtendedDataRecordEx
          GetEventFreezeFrameDataEx
          GetFaultDetectionCounter
          GetDTCOfEvent
          GetEventTested
          GetEventFailed
          GetEventStatus
          GetEventUdsStatus
      EvtInfo_DTC_0x114792: required-interface=DiagnosticInfo
        required-com-specs:
          GetMonitorStatus
          GetDebouncingOfEvent
          GetEventEnableCondition
          GetEventExtendedDataRecordEx
          GetEventFreezeFrameDataEx
          GetFaultDetectionCounter
          GetDTCOfEvent
          GetEventTested
          GetEventFailed
          GetEventStatus
          GetEventUdsStatus
      EvtInfo_DTC_0x114892: required-interface=DiagnosticInfo
        required-com-specs:
          GetMonitorStatus
          GetDebouncingOfEvent
          GetEventEnableCondition
          GetEventExtendedDataRecordEx
          GetEventFreezeFrameDataEx
          GetFaultDetectionCounter
          GetDTCOfEvent
          GetEventTested
          GetEventFailed
          GetEventStatus
          GetEventUdsStatus
      EvtInfo_DTC_0x114992: required-interface=DiagnosticInfo
        required-com-specs:
          GetMonitorStatus
          GetDebouncingOfEvent
          GetEventEnableCondition
          GetEventExtendedDataRecordEx
          GetEventFreezeFrameDataEx
          GetFaultDetectionCounter
          GetDTCOfEvent
          GetEventTested
          GetEventFailed
          GetEventStatus
          GetEventUdsStatus
      EvtInfo_DTC_0x115092: required-interface=DiagnosticInfo
        required-com-specs:
          GetMonitorStatus
          GetDebouncingOfEvent
          GetEventEnableCondition
          GetEventExtendedDataRecordEx
          GetEventFreezeFrameDataEx
          GetFaultDetectionCounter
          GetDTCOfEvent
          GetEventTested
          GetEventFailed
          GetEventStatus
          GetEventUdsStatus
      EvtInfo_DTC_0x115192: required-interface=DiagnosticInfo
        required-com-specs:
          GetMonitorStatus
          GetDebouncingOfEvent
          GetEventEnableCondition
          GetEventExtendedDataRecordEx
          GetEventFreezeFrameDataEx
          GetFaultDetectionCounter
          GetDTCOfEvent
          GetEventTested
          GetEventFailed
          GetEventStatus
          GetEventUdsStatus
      EvtInfo_DTC_0x115292: required-interface=DiagnosticInfo
        required-com-specs:
          GetMonitorStatus
          GetDebouncingOfEvent
          GetEventEnableCondition
          GetEventExtendedDataRecordEx
          GetEventFreezeFrameDataEx
          GetFaultDetectionCounter
          GetDTCOfEvent
          GetEventTested
          GetEventFailed
          GetEventStatus
          GetEventUdsStatus
      EvtInfo_DTC_0x115392: required-interface=DiagnosticInfo
        required-com-specs:
          GetMonitorStatus
          GetDebouncingOfEvent
          GetEventEnableCondition
          GetEventExtendedDataRecordEx
          GetEventFreezeFrameDataEx
          GetFaultDetectionCounter
          GetDTCOfEvent
          GetEventTested
          GetEventFailed
          GetEventStatus
          GetEventUdsStatus
      EvtInfo_DTC_0x115492: required-interface=DiagnosticInfo
        required-com-specs:
          GetMonitorStatus
          GetDebouncingOfEvent
          GetEventEnableCondition
          GetEventExtendedDataRecordEx
          GetEventFreezeFrameDataEx
          GetFaultDetectionCounter
          GetDTCOfEvent
          GetEventTested
          GetEventFailed
          GetEventStatus
          GetEventUdsStatus
      EvtInfo_DTC_0x115592: required-interface=DiagnosticInfo
        required-com-specs:
          GetMonitorStatus
          GetDebouncingOfEvent
          GetEventEnableCondition
          GetEventExtendedDataRecordEx
          GetEventFreezeFrameDataEx
          GetFaultDetectionCounter
          GetDTCOfEvent
          GetEventTested
          GetEventFailed
          GetEventStatus
          GetEventUdsStatus
      EvtInfo_DTC_0x115692: required-interface=DiagnosticInfo
        required-com-specs:
          GetMonitorStatus
          GetDebouncingOfEvent
          GetEventEnableCondition
          GetEventExtendedDataRecordEx
          GetEventFreezeFrameDataEx
          GetFaultDetectionCounter
          GetDTCOfEvent
          GetEventTested
          GetEventFailed
          GetEventStatus
          GetEventUdsStatus
      EvtInfo_DTC_0x113597: required-interface=DiagnosticInfo
        required-com-specs:
          GetMonitorStatus
          GetDebouncingOfEvent
          GetEventEnableCondition
          GetEventExtendedDataRecordEx
          GetEventFreezeFrameDataEx
          GetFaultDetectionCounter
          GetDTCOfEvent
          GetEventTested
          GetEventFailed
          GetEventStatus
          GetEventUdsStatus
      EvtInfo_DTC_0x111352: required-interface=DiagnosticInfo
        required-com-specs:
          GetMonitorStatus
          GetDebouncingOfEvent
          GetEventEnableCondition
          GetEventExtendedDataRecordEx
          GetEventFreezeFrameDataEx
          GetFaultDetectionCounter
          GetDTCOfEvent
          GetEventTested
          GetEventFailed
          GetEventStatus
          GetEventUdsStatus
      EvtInfo_DTC_0x11571e: required-interface=DiagnosticInfo
        required-com-specs:
          GetMonitorStatus
          GetDebouncingOfEvent
          GetEventEnableCondition
          GetEventExtendedDataRecordEx
          GetEventFreezeFrameDataEx
          GetFaultDetectionCounter
          GetDTCOfEvent
          GetEventTested
          GetEventFailed
          GetEventStatus
          GetEventUdsStatus
    6 x provide port:
      UDS_PwrCutRequest: nonqueued-sender-com-spec{data-element=PwrCutRequest, init-value=0}, provided-interface=UDS_PwrCutRequest
      BSW_NVMFailErrorStatus: nonqueued-sender-com-spec{data-element=NVMFailErrorStatus, init-value=0}, provided-interface=BSW_NVMFailErrorStatus
      BSW_FuSaHWErrorStatus: nonqueued-sender-com-spec{data-element=HWErrorStatus, init-value=0}, provided-interface=BSW_FuSaHWErrorStatus
      PTCAN_BusoffStatus: nonqueued-sender-com-spec{data-element=BusoffStatus, init-value=0}, provided-interface=PTCAN_BusoffStatus
      DCCAN_BusoffStatus: nonqueued-sender-com-spec{data-element=BusoffStatus, init-value=0}, provided-interface=DCCAN_BusoffStatus
      CHCAN_BusoffStatus: nonqueued-sender-com-spec{data-element=BusoffStatus, init-value=0}, provided-interface=CHCAN_BusoffStatus
    74 x require port:
      Event_DTC_0x117511: required-interface=DiagnosticMonitor
        required-com-specs:
          GetEventExtendedDataRecordEx
          GetEventFreezeFrameDataEx
          GetFaultDetectionCounter
          GetDTCOfEvent
          GetEventTested
          GetEventFailed
          GetEventStatus
          GetEventUdsStatus
          ResetEventDebounceStatus
          ResetEventStatus
          SetEventStatus
      Event_DTC_0xc29a87: required-interface=DiagnosticMonitor
        required-com-specs:
          GetEventExtendedDataRecordEx
          GetEventFreezeFrameDataEx
          GetFaultDetectionCounter
          GetDTCOfEvent
          GetEventTested
          GetEventFailed
          GetEventStatus
          GetEventUdsStatus
          ResetEventDebounceStatus
          ResetEventStatus
          SetEventStatus
      EvtInfo_DTC_0x117511: required-interface=DiagnosticInfo
        required-com-specs:
          GetMonitorStatus
          GetDebouncingOfEvent
          GetEventEnableCondition
          GetEventExtendedDataRecordEx
          GetEventFreezeFrameDataEx
          GetFaultDetectionCounter
          GetDTCOfEvent
          GetEventTested
          GetEventFailed
          GetEventStatus
          GetEventUdsStatus
      EvtInfo_DTC_0xc29a87: required-interface=DiagnosticInfo
        required-com-specs:
          GetMonitorStatus
          GetDebouncingOfEvent
          GetEventEnableCondition
          GetEventExtendedDataRecordEx
          GetEventFreezeFrameDataEx
          GetFaultDetectionCounter
          GetDTCOfEvent
          GetEventTested
          GetEventFailed
          GetEventStatus
          GetEventUdsStatus
      EvtInfo_DTC_0xc07388: required-interface=DiagnosticInfo
        required-com-specs:
          GetMonitorStatus
          GetDebouncingOfEvent
          GetEventEnableCondition
          GetEventExtendedDataRecordEx
          GetEventFreezeFrameDataEx
          GetFaultDetectionCounter
          GetDTCOfEvent
          GetEventTested
          GetEventFailed
          GetEventStatus
          GetEventUdsStatus
      EvtInfo_DTC_0xc07488: required-interface=DiagnosticInfo
        required-com-specs:
          GetMonitorStatus
          GetDebouncingOfEvent
          GetEventEnableCondition
          GetEventExtendedDataRecordEx
          GetEventFreezeFrameDataEx
          GetFaultDetectionCounter
          GetDTCOfEvent
          GetEventTested
          GetEventFailed
          GetEventStatus
          GetEventUdsStatus
      RTE_R_ChassisMgmt_AccrPedlURaw1HiDTC_Bus: nonqueued-receiver-com-spec{data-element=tec_ChassisMgmt_AccrPedlURaw1HiDTC_Bus, filter=data-filter-type=ALWAYS, init-value=fields=[ChassisMgmt_MonStatAccrPedlURaw1Hi:0, ChassisMgmt_MonResAccrPedlURaw1Hi:0, ChassisMgmt_ErrStatAccrPedlURaw1Hi:0, ChassisMgmt_ErrResAccrPedlURaw1Hi:0]}, required-interface=IF_ChassisMgmt_AccrPedlURaw1HiDTC_Bus
      RTE_R_ChassisMgmt_AccrPedlURaw2HiDTC_Bus: nonqueued-receiver-com-spec{data-element=tec_ChassisMgmt_AccrPedlURaw2HiDTC_Bus, filter=data-filter-type=ALWAYS, init-value=fields=[ChassisMgmt_MonStatAccrPedlURaw2Hi:0, ChassisMgmt_MonResAccrPedlURaw2Hi:0, ChassisMgmt_ErrStatAccrPedlURaw2Hi:0, ChassisMgmt_ErrResAccrPedlURaw2Hi:0]}, required-interface=IF_ChassisMgmt_AccrPedlURaw2HiDTC_Bus
      RTE_R_ChassisMgmt_AccrPedlURaw1LoDTC_Bus: nonqueued-receiver-com-spec{data-element=tec_ChassisMgmt_AccrPedlURaw1LoDTC_Bus, filter=data-filter-type=ALWAYS, init-value=fields=[ChassisMgmt_MonStatAccrPedlURaw1Lo:0, ChassisMgmt_MonResAccrPedlURaw1Lo:0, ChassisMgmt_ErrStatAccrPedlURaw1Lo:0, ChassisMgmt_ErrResAccrPedlURaw1Lo:0]}, required-interface=IF_ChassisMgmt_AccrPedlURaw1LoDTC_Bus
      RTE_R_ChassisMgmt_AccrPedlURawDifDTC_Bus: nonqueued-receiver-com-spec{data-element=tec_ChassisMgmt_AccrPedlURawDifDTC_Bus, filter=data-filter-type=ALWAYS, init-value=fields=[ChassisMgmt_MonStatAccrPedlURawDif:0, ChassisMgmt_MonResAccrPedlURawDif:0, ChassisMgmt_ErrStatAccrPedlURawDif:0, ChassisMgmt_ErrResAccrPedlURawDif:0]}, required-interface=IF_ChassisMgmt_AccrPedlURawDifDTC_Bus
      RTE_R_ChassisMgmt_AccrPedlURaw2LoDTC_Bus: nonqueued-receiver-com-spec{data-element=tec_ChassisMgmt_AccrPedlURaw2LoDTC_Bus, filter=data-filter-type=ALWAYS, init-value=fields=[ChassisMgmt_MonStatAccrPedlURaw2Lo:0, ChassisMgmt_MonResAccrPedlURaw2Lo:0, ChassisMgmt_ErrStatAccrPedlURaw2Lo:0, ChassisMgmt_ErrResAccrPedlURaw2Lo:0]}, required-interface=IF_ChassisMgmt_AccrPedlURaw2LoDTC_Bus
      RTE_R_ChassisMgmt_IBSRbsDesTqOverFltDTCInfo_Bus: nonqueued-receiver-com-spec{data-element=tec_ChassisMgmt_IBSRbsDesTqOverFltDTCInfo_Bus, filter=data-filter-type=ALWAYS, init-value=fields=[ChassisMgmt_MonStatIBSRbsDesTqOverFltDTCInfo:0, ChassisMgmt_MonResIBSRbsDesTqOverFltDTCInfo:0, ChassisMgmt_ErrStatIBSRbsDesTqOverFltDTCInfo:0, ChassisMgmt_ErrResIBSRbsDesTqOverFltDTCInfo:0]}, required-interface=IF_ChassisMgmt_IBSRbsDesTqOverFltDTCInfo_Bus
      RTE_R_ChassisMgmt_IBSApsCtrlDesTqOverFltDTCInfo_Bus: nonqueued-receiver-com-spec{data-element=tec_ChassisMgmt_IBSApsCtrlDesTqOverFltDTCInfo_Bus, filter=data-filter-type=ALWAYS, init-value=fields=[ChassisMgmt_MonStatIBSApsCtrlDesTqOverFltDTCInfo:0, ChassisMgmt_MonResIBSApsCtrlDesTqOverFltDTCInfo:0, ChassisMgmt_ErrStatIBSApsCtrlDesTqOverFltDTCInfo:0, ChassisMgmt_ErrResIBSApsCtrlDesTqOverFltDTCInfo:0]}, required-interface=IF_ChassisMgmt_IBSApsCtrlDesTqOverFltDTCInfo_Bus
      RTE_R_ChrMgmt_AcPreheatUDcCtrlErrDTC_Bus: nonqueued-receiver-com-spec{data-element=tec_ChrMgmt_AcPreheatUDcCtrlErrDTC_Bus, filter=data-filter-type=ALWAYS, init-value=fields=[ChrMgmt_MonStatAcPreheatUDcCtrlErrDTC:0, ChrMgmt_MonResAcPreheatUDcCtrlErrDTC:0, ChrMgmt_ErrStatAcPreheatUDcCtrlErrDTC:0, ChrMgmt_ErrResAcPreheatUDcCtrlErrDTC:0]}, required-interface=IF_ChrMgmt_AcPreheatUDcCtrlErrDTC_Bus
      RTE_R_ChassisMgmt_IBSVlcCtrlDesTqOverFltDTCInfo_Bus: nonqueued-receiver-com-spec{data-element=tec_ChassisMgmt_IBSVlcCtrlDesTqOverFltDTCInfo_Bus, filter=data-filter-type=ALWAYS, init-value=fields=[ChassisMgmt_MonStatIBSVlcCtrlDesTqOverFltDTCInfo:0, ChassisMgmt_MonResIBSVlcCtrlDesTqOverFltDTCInfo:0, ChassisMgmt_ErrStatIBSVlcCtrlDesTqOverFltDTCInfo:0, ChassisMgmt_ErrResIBSVlcCtrlDesTqOverFltDTCInfo:0]}, required-interface=IF_ChassisMgmt_IBSVlcCtrlDesTqOverFltDTCInfo_Bus
      RTE_R_ChrMgmt_DcPreheatUDcCtrlErrDTC_Bus: nonqueued-receiver-com-spec{data-element=tec_ChrMgmt_DcPreheatUDcCtrlErrDTC_Bus, filter=data-filter-type=ALWAYS, init-value=fields=[ChrMgmt_MonStatDcPreheatUDcCtrlErrDTC:0, ChrMgmt_MonResDcPreheatUDcCtrlErrDTC:0, ChrMgmt_ErrStatDcPreheatUDcCtrlErrDTC:0, ChrMgmt_ErrResDcPreheatUDcCtrlErrDTC:0]}, required-interface=IF_ChrMgmt_DcPreheatUDcCtrlErrDTC_Bus
      RTE_R_ChrMgmt_CC2UDcDTC_Bus: nonqueued-receiver-com-spec{data-element=tec_ChrMgmt_CC2UDcErrDTC_Bus, filter=data-filter-type=ALWAYS, init-value=fields=[ChrMgmt_MonStatCC2UDcErrDTC:0, ChrMgmt_MonResCC2UDcErrDTC:0, ChrMgmt_ErrStatCC2UDcErrDTC:0, ChrMgmt_ErrResCC2UDcErrDTC:0]}, required-interface=IF_ChrMgmt_CC2UDcDTC_Bus
      RTE_R_ChrMgmt_PreheatIRChkErrDTC_Bus: nonqueued-receiver-com-spec{data-element=tec_ChrMgmt_PreheatIRChkErrDTC_Bus, filter=data-filter-type=ALWAYS, init-value=fields=[ChrMgmt_MonStatPreheatIRChkErrDTC:0, ChrMgmt_MonResPreheatIRChkErrDTC:0, ChrMgmt_ErrStatPreheatIRChkErrDTC:0, ChrMgmt_ErrResPreheatIRChkErrDTC:0]}, required-interface=IF_ChrMgmt_PreheatIRChkErrDTC_Bus
      RTE_R_ChrMgmt_ChrgStsJmpDTC_Bus: nonqueued-receiver-com-spec{data-element=tec_ChrMgmt_ChrgStsJmpErrDTC_Bus, filter=data-filter-type=ALWAYS, init-value=fields=[ChrMgmt_MonStatChrgStsJmpErrDTC:0, ChrMgmt_MonResChrgStsJmpErrDTC:0, ChrMgmt_ErrStatChrgStsJmpErrDTC:0, ChrMgmt_ErrResChrgStsJmpErrDTC:0]}, required-interface=IF_ChrMgmt_ChrgStsJmpDTC_Bus
      RTE_R_DCChrMgmt_BEMRxCRMPrepdTmtDTC_Bus: nonqueued-receiver-com-spec{data-element=tec_DCChrMgmt_BEMRxCRMPrepdTmtDTC_Bus, filter=data-filter-type=ALWAYS, init-value=fields=[DCChrMgmt_MonStatBEMRxCRMPrepdTmtDTC:0, DCChrMgmt_MonResBEMRxCRMPrepdTmtDTC:0, DCChrMgmt_ErrStatBEMRxCRMPrepdTmtDTC:0, DCChrMgmt_ErrResBEMRxCRMPrepdTmtDTC:0]}, required-interface=IF_DCChrMgmt_BEMRxCRMPrepdTmtDTC_Bus
      RTE_R_DCChrMgmt_BEMRxCMLTmtDTC_Bus: nonqueued-receiver-com-spec{data-element=tec_DCChrMgmt_BEMRxCMLTmtDTC_Bus, filter=data-filter-type=ALWAYS, init-value=fields=[DCChrMgmt_MonStatBEMRxCMLTmtDTC:0, DCChrMgmt_MonResBEMRxCMLTmtDTC:0, DCChrMgmt_ErrStatBEMRxCMLTmtDTC:0, DCChrMgmt_ErrResBEMRxCMLTmtDTC:0]}, required-interface=IF_DCChrMgmt_BEMRxCMLTmtDTC_Bus
      RTE_R_DCChrMgmt_BEMRxCCSTmtDTC_Bus: nonqueued-receiver-com-spec{data-element=tec_DCChrMgmt_BEMRxCCSTmtDTC_Bus, filter=data-filter-type=ALWAYS, init-value=fields=[DCChrMgmt_MonStatBEMRxCCSTmtDTC:0, DCChrMgmt_MonResBEMRxCCSTmtDTC:0, DCChrMgmt_ErrStatBEMRxCCSTmtDTC:0, DCChrMgmt_ErrResBEMRxCCSTmtDTC:0]}, required-interface=IF_DCChrMgmt_BEMRxCCSTmtDTC_Bus
      RTE_R_DCChrMgmt_BEMRxCROTmtDTC_Bus: nonqueued-receiver-com-spec{data-element=tec_DCChrMgmt_BEMRxCROTmtDTC_Bus, filter=data-filter-type=ALWAYS, init-value=fields=[DCChrMgmt_MonStatBEMRxCROTmtDTC:0, DCChrMgmt_MonResBEMRxCROTmtDTC:0, DCChrMgmt_ErrStatBEMRxCROTmtDTC:0, DCChrMgmt_ErrResBEMRxCROTmtDTC:0]}, required-interface=IF_DCChrMgmt_BEMRxCROTmtDTC_Bus
      RTE_R_DCChrMgmt_BEMRxCRMTmtDTC_Bus: nonqueued-receiver-com-spec{data-element=tec_DCChrMgmt_BEMRxCRMTmtDTC_Bus, filter=data-filter-type=ALWAYS, init-value=fields=[DCChrMgmt_MonStatBEMRxCRMTmtDTC:0, DCChrMgmt_MonResBEMRxCRMTmtDTC:0, DCChrMgmt_ErrStatBEMRxCRMTmtDTC:0, DCChrMgmt_ErrResBEMRxCRMTmtDTC:0]}, required-interface=IF_DCChrMgmt_BEMRxCRMTmtDTC_Bus
      RTE_R_DCChrMgmt_DcPortTempErrLvl1DTC_Bus: nonqueued-receiver-com-spec{data-element=tec_DCChrMgmt_DcPortTempErrLvl1DTC_Bus, filter=data-filter-type=ALWAYS, init-value=fields=[DCChrMgmt_MonStatDcPortTempErrLvl1DTC:0, DCChrMgmt_MonResDcPortTempErrLvl1DTC:0, DCChrMgmt_ErrStatDcPortTempErrLvl1DTC:0, DCChrMgmt_ErrResDcPortTempErrLvl1DTC:0]}, required-interface=IF_DCChrMgmt_DcPortTempErrLvl1DTC_Bus
      RTE_R_DCChrMgmt_BEMRxCROPrepdTmtDTC_Bus: nonqueued-receiver-com-spec{data-element=tec_DCChrMgmt_BEMRxCROPrepdTmtDTC_Bus, filter=data-filter-type=ALWAYS, init-value=fields=[DCChrMgmt_MonStatBEMRxCROPrepdTmtDTC:0, DCChrMgmt_MonResBEMRxCROPrepdTmtDTC:0, DCChrMgmt_ErrStatBEMRxCROPrepdTmtDTC:0, DCChrMgmt_ErrResBEMRxCROPrepdTmtDTC:0]}, required-interface=IF_DCChrMgmt_BEMRxCROPrepdTmtDTC_Bus
      RTE_R_DCChrMgmt_DcPortTempErrLvl2DTC_Bus: nonqueued-receiver-com-spec{data-element=tec_DCChrMgmt_DcPortTempErrLvl2DTC_Bus, filter=data-filter-type=ALWAYS, init-value=fields=[DCChrMgmt_MonStatDcPortTempErrLvl2DTC:0, DCChrMgmt_MonResDcPortTempErrLvl2DTC:0, DCChrMgmt_ErrStatDcPortTempErrLvl2DTC:0, DCChrMgmt_ErrResDcPortTempErrLvl2DTC:0]}, required-interface=IF_DCChrMgmt_DcPortTempErrLvl2DTC_Bus
      RTE_R_DCChrMgmt_IRMeasDiErrDTC_Bus: nonqueued-receiver-com-spec{data-element=tec_DCChrMgmt_IRMeasDiErrDTC_Bus, filter=data-filter-type=ALWAYS, init-value=fields=[DCChrMgmt_MonStatIRMeasDiErrDTC:0, DCChrMgmt_MonResIRMeasDiErrDTC:0, DCChrMgmt_ErrStatIRMeasDiErrDTC:0, DCChrMgmt_ErrResIRMeasDiErrDTC:0]}, required-interface=IF_DCChrMgmt_IRMeasDiErrDTC_Bus
      RTE_R_DCChrMgmt_DcPortTempSnsrErrDTC_Bus: nonqueued-receiver-com-spec{data-element=tec_DCChrMgmt_DcPortTempSnsrErrDTC_Bus, filter=data-filter-type=ALWAYS, init-value=fields=[DCChrMgmt_MonStatDcPortTempSnsrErrDTC:0, DCChrMgmt_MonResDcPortTempSnsrErrDTC:0, DCChrMgmt_ErrStatDcPortTempSnsrErrDTC:0, DCChrMgmt_ErrResDcPortTempSnsrErrDTC:0]}, required-interface=IF_DCChrMgmt_DcPortTempSnsrErrDTC_Bus
      RTE_R_FctSftyMon_CrpCtrlTqOverFltDTCInfo_Bus: nonqueued-receiver-com-spec{data-element=tec_FctSftyMon_CrpCtrlTqOverFltDTCInfo_Bus, filter=data-filter-type=ALWAYS, init-value=fields=[FctSftyMon_MonStatCrpCtrlTqOverFltInfo:0, FctSftyMon_MonResCrpCtrlTqOverFltInfo:0, FctSftyMon_ErrStatCrpCtrlTqOverFltInfo:0, FctSftyMon_ErrResCrpCtrlTqOverFltInfo:0]}, required-interface=IF_FctSftyMon_CrpCtrlTqOverFltDTCInfo_Bus
      RTE_R_DCChrMgmt_IRMeasEnaErrDTC_Bus: nonqueued-receiver-com-spec{data-element=tec_DCChrMgmt_IRMeasEnaErrDTC_Bus, filter=data-filter-type=ALWAYS, init-value=fields=[DCChrMgmt_MonStatIRMeasEnaErrDTC:0, DCChrMgmt_MonResIRMeasEnaErrDTC:0, DCChrMgmt_ErrStatIRMeasEnaErrDTC:0, DCChrMgmt_ErrResIRMeasEnaErrDTC:0]}, required-interface=IF_DCChrMgmt_IRMeasEnaErrDTC_Bus
      RTE_R_FctSftyMon_DesVehDecelSpdOverFltDTCInfo_Bus: nonqueued-receiver-com-spec{data-element=tec_FctSftyMon_DesVehDecelSpdOverFltDTCInfo_Bus, filter=data-filter-type=ALWAYS, init-value=fields=[FctSftyMon_MonStatDesVehDecelSpdOverFltInfo:0, FctSftyMon_MonResDesVehDecelSpdOverFltInfo:0, FctSftyMon_ErrStatDesVehDecelSpdOverFltInfo:0, FctSftyMon_ErrResDesVehDecelSpdOverFltInfo:0]}, required-interface=IF_FctSftyMon_DesVehDecelSpdOverFltDTCInfo_Bus
      RTE_R_ErrMgmt_VCUHVILDTC_Bus: nonqueued-receiver-com-spec{data-element=tec_ErrMgmt_VCUHVILDTC_Bus, filter=data-filter-type=ALWAYS, init-value=fields=[ErrMgmt_MonStatVCUHVIL:0, ErrMgmt_MonResVCUHVIL:0, ErrMgmt_ErrStatVCUHVIL:0, ErrMgmt_ErrResVCUHVIL:0]}, required-interface=IF_ErrMgmt_VCUHVILDTC_Bus
      RTE_R_FctSftyMon_AccrPedlTqOverFltDTCInfo_Bus: nonqueued-receiver-com-spec{data-element=tec_FctSftyMon_AccrPedlTqOverFltDTCInfo_Bus, filter=data-filter-type=ALWAYS, init-value=fields=[FctSftyMon_MonStatAccrPedlTqOverFltInfo:0, FctSftyMon_MonResAccrPedlTqOverFltInfo:0, FctSftyMon_ErrStatAccrPedlTqOverFltInfo:0, FctSftyMon_ErrResAccrPedlTqOverFltInfo:0]}, required-interface=IF_FctSftyMon_AccrPedlTqOverFltDTCInfo_Bus
      RTE_R_DCChrMgmt_BEMRxCSTTmtDTC_Bus: nonqueued-receiver-com-spec{data-element=tec_DCChrMgmt_BEMRxCSTTmtDTC_Bus, filter=data-filter-type=ALWAYS, init-value=fields=[DCChrMgmt_MonStatBEMRxCSTTmtDTC:0, DCChrMgmt_MonResBEMRxCSTTmtDTC:0, DCChrMgmt_ErrStatBEMRxCSTTmtDTC:0, DCChrMgmt_ErrResBEMRxCSTTmtDTC:0]}, required-interface=IF_DCChrMgmt_BEMRxCSTTmtDTC_Bus
      RTE_R_HvMgmt_BMSRlyOpenDTC_Bus: nonqueued-receiver-com-spec{data-element=tec_HvMgmt_BMSRlyOpenDTC_Bus, filter=data-filter-type=ALWAYS, init-value=fields=[HvMgmt_MonStatBMSRlyOpenDTC:0, HvMgmt_MonResBMSRlyOpenDTC:0, HvMgmt_ErrStatBMSRlyOpenDTC:0, HvMgmt_ErrResBMSRlyOpenDTC:0]}, required-interface=IF_HvMgmt_BMSRlyOpenDTC_Bus
      RTE_R_HvMgmt_BMSRlyClsDTC_Bus: nonqueued-receiver-com-spec{data-element=tec_HvMgmt_BMSRlyClsDTC_Bus, filter=data-filter-type=ALWAYS, init-value=fields=[HvMgmt_MonStatBMSRlyClsDTC:0, HvMgmt_MonResBMSRlyClsDTC:0, HvMgmt_ErrStatBMSRlyClsDTC:0, HvMgmt_ErrResBMSRlyClsDTC:0]}, required-interface=IF_HvMgmt_BMSRlyClsDTC_Bus
      RTE_R_DCChrMgmt_BEMRxCSDTmtDTC_Bus: nonqueued-receiver-com-spec{data-element=tec_DCChrMgmt_BEMRxCSDTmtDTC_Bus, filter=data-filter-type=ALWAYS, init-value=fields=[DCChrMgmt_MonStatBEMRxCSDTmtDTC:0, DCChrMgmt_MonResBEMRxCSDTmtDTC:0, DCChrMgmt_ErrStatBEMRxCSDTmtDTC:0, DCChrMgmt_ErrResBEMRxCSDTmtDTC:0]}, required-interface=IF_DCChrMgmt_BEMRxCSDTmtDTC_Bus
      RTE_R_ComM_ComDTCFailr: required-interface=IF_ComM_ComDTCFailr
        required-com-specs:
          data-element=tec_ComM_OBCComDTCFailr_Flg, filter=data-filter-type=ALWAYS, init-value=0
          data-element=tec_ComM_EPTIBSComDTCFailr_Flg, filter=data-filter-type=ALWAYS, init-value=0
          data-element=tec_ComM_EVCOMComDTCFailr_Flg, filter=data-filter-type=ALWAYS, init-value=0
          data-element=tec_ComM_APTCComDTCFailr_Flg, filter=data-filter-type=ALWAYS, init-value=0
          data-element=tec_ComM_CGWComDTCFailr_Flg, filter=data-filter-type=ALWAYS, init-value=0
          data-element=tec_ComM_SGWComDTCFailr_Flg, filter=data-filter-type=ALWAYS, init-value=0
          data-element=tec_ComM_BCMComDTCFailr_Flg, filter=data-filter-type=ALWAYS, init-value=0
          data-element=tec_ComM_PRNDComDTCFailr_Flg, filter=data-filter-type=ALWAYS, init-value=0
          data-element=tec_ComM_DCDCComDTCFailr_Flg, filter=data-filter-type=ALWAYS, init-value=0
          data-element=tec_ComM_IVIComDTCFailr_Flg, filter=data-filter-type=ALWAYS, init-value=0
          data-element=tec_ComM_BMSComDTCFailr_Flg, filter=data-filter-type=ALWAYS, init-value=0
          data-element=tec_ComM_MCUComDTCFailr_Flg, filter=data-filter-type=ALWAYS, init-value=0
          data-element=tec_ComM_TCUComDTCFailr_Flg, filter=data-filter-type=ALWAYS, init-value=0
          data-element=tec_ComM_ADCUComDTCFailr_Flg, filter=data-filter-type=ALWAYS, init-value=0
          data-element=tec_ComM_ACUComDTCFailr_Flg, filter=data-filter-type=ALWAYS, init-value=0
          data-element=tec_ComM_CHIBSComDTCFailr_Flg, filter=data-filter-type=ALWAYS, init-value=0
          data-element=tec_ComM_SGWCHComDTCFailr_Flg, init-value=0
          data-element=tec_ComM_DCMRRComDTCFailr_Flg, init-value=0
          data-element=tec_ComM_DCMRLComDTCFailr_Flg, init-value=0
          data-element=tec_ComM_DCMFRComDTCFailr_Flg, init-value=0
          data-element=tec_ComM_DCMFLComDTCFailr_Flg, init-value=0
      RTE_R_HvMgmt_PreheatPosRlyOpenDTC_Bus: nonqueued-receiver-com-spec{data-element=tec_HvMgmt_PreheatPosRlyOpenDTC_Bus, filter=data-filter-type=ALWAYS, init-value=fields=[HvMgmt_MonStatPreheatPosRlyOpenDTC:0, HvMgmt_MonResPreheatPosRlyOpenDTC:0, HvMgmt_ErrStatPreheatPosRlyOpenDTC:0, HvMgmt_ErrResPreheatPosRlyOpenDTC:0]}, required-interface=IF_HvMgmt_PreheatPosRlyOpenDTC_Bus
      RTE_R_HvMgmt_PreheatPosRlyClsDTC_Bus: nonqueued-receiver-com-spec{data-element=tec_HvMgmt_PreheatPosRlyClsDTC_Bus, filter=data-filter-type=ALWAYS, init-value=fields=[HvMgmt_MonStatPreheatPosRlyClsDTC:0, HvMgmt_MonResPreheatPosRlyClsDTC:0, HvMgmt_ErrStatPreheatPosRlyClsDTC:0, HvMgmt_ErrResPreheatPosRlyClsDTC:0]}, required-interface=IF_HvMgmt_PreheatPosRlyClsDTC_Bus
      RTE_R_LvMgmt_BSBattIDcHiDTC_Bus: nonqueued-receiver-com-spec{data-element=tec_LvMgmt_BSBattIDcHiDTC_Bus, filter=data-filter-type=ALWAYS, init-value=fields=[LvMgmt_MonStatBSBattIDcHiDTC:0, LvMgmt_MonResBSBattIDcHiDTC:0, LvMgmt_ErrStatBSBattIDcHiDTC:0, LvMgmt_ErrResBSBattIDcHiDTC:0]}, required-interface=IF_LvMgmt_BSBattIDcHiDTC_Bus
      RTE_R_HvMgmt_TCUEnaFltDTC_Bus: nonqueued-receiver-com-spec{data-element=tec_HvMgmt_TCUEnaFltDTC_Bus, filter=data-filter-type=ALWAYS, init-value=fields=[HvMgmt_MonStatTCUEnaFltDTC:0, HvMgmt_MonResTCUEnaFltDTC:0, HvMgmt_ErrStatTCUEnaFltDTC:0, HvMgmt_ErrResTCUEnaFltDTC:0]}, required-interface=IF_HvMgmt_TCUEnaFltDTC_Bus
      RTE_R_LvMgmt_ECUsDiagDTC_Bus: nonqueued-receiver-com-spec{data-element=tec_LvMgmt_ECUsDiagDTC_Bus, filter=data-filter-type=ALWAYS, init-value=fields=[LvMgmt_MonStatECUsDiagDTC:0, LvMgmt_MonResECUsDiagDTC:0, LvMgmt_ErrStatECUsDiagDTC:0, LvMgmt_ErrResECUsDiagDTC:0]}, required-interface=IF_LvMgmt_ECUsDiagDTC_Bus
      RTE_R_LvMgmt_BSBattUDcLoDTC_Bus: nonqueued-receiver-com-spec{data-element=tec_LvMgmt_BSBattUDcLoDTC_Bus, filter=data-filter-type=ALWAYS, init-value=fields=[LvMgmt_MonStatBSBattUDcLoDTC:0, LvMgmt_MonResBSBattUDcLoDTC:0, LvMgmt_ErrStatBSBattUDcLoDTC:0, LvMgmt_ErrResBSBattUDcLoDTC:0]}, required-interface=IF_LvMgmt_BSBattUDcLoDTC_Bus
      RTE_R_HvMgmt_TCUStopFltDTC_Bus: nonqueued-receiver-com-spec{data-element=tec_HvMgmt_TCUStopFltDTC_Bus, filter=data-filter-type=ALWAYS, init-value=fields=[HvMgmt_MonStatTCUStopFltDTC:0, HvMgmt_MonResTCUStopFltDTC:0, HvMgmt_ErrStatTCUStopFltDTC:0, HvMgmt_ErrResTCUStopFltDTC:0]}, required-interface=IF_HvMgmt_TCUStopFltDTC_Bus
      RTE_R_LvMgmt_BSBattUDcHiDTC_Bus: nonqueued-receiver-com-spec{data-element=tec_LvMgmt_BSBattUDcHiDTC_Bus, filter=data-filter-type=ALWAYS, init-value=fields=[LvMgmt_MonStatBSBattUDcHiDTC:0, LvMgmt_MonResBSBattUDcHiDTC:0, LvMgmt_ErrStatBSBattUDcHiDTC:0, LvMgmt_ErrResBSBattUDcHiDTC:0]}, required-interface=IF_LvMgmt_BSBattUDcHiDTC_Bus
      RTE_R_LvMgmt_LvSysOvrUdcDTC_Bus: nonqueued-receiver-com-spec{data-element=tec_LvMgmt_LvSysOvrUdcDTC_Bus, filter=data-filter-type=ALWAYS, init-value=fields=[LvMgmt_MonStatLvSysOvrUDcDTC:0, LvMgmt_MonResLvSysOvrUDcDTC:0, LvMgmt_ErrStatLvSysOvrUDcDTC:0, LvMgmt_ErrResLvSysOvrUDcDTC:0]}, required-interface=IF_LvMgmt_LvSysOvrUdcDTC_Bus
      RTE_R_LvMgmt_KL15eOnDTC_Bus: nonqueued-receiver-com-spec{data-element=tec_LvMgmt_KL15eOnDTC_Bus, filter=data-filter-type=ALWAYS, init-value=fields=[LvMgmt_MonStatKL15eOnDTC:0, LvMgmt_MonResKL15eOnDTC:0, LvMgmt_ErrStatKL15eOnDTC:0, LvMgmt_ErrResKL15eOnDTC:0]}, required-interface=IF_LvMgmt_KL15eOnDTC_Bus
      RTE_R_LvMgmt_KL15eOffDTC_Bus: nonqueued-receiver-com-spec{data-element=tec_LvMgmt_KL15eOffDTC_Bus, filter=data-filter-type=ALWAYS, init-value=fields=[LvMgmt_MonStatKL15eOffDTC:0, LvMgmt_MonResKL15eOffDTC:0, LvMgmt_ErrStatKL15eOffDTC:0, LvMgmt_ErrResKL15eOffDTC:0]}, required-interface=IF_LvMgmt_KL15eOffDTC_Bus
      RTE_R_OBCMgmt_ElectcLockClsErrDTC_Bus: nonqueued-receiver-com-spec{data-element=tec_OBCMgmt_ElectcLockClsErrDTC_Bus, filter=data-filter-type=ALWAYS, init-value=fields=[OBCMgmt_MonStatElectcLockClsErrDTC:0, OBCMgmt_MonResElectcLockClsErrDTC:0, OBCMgmt_ErrStatElectcLockClsErrDTC:0, OBCMgmt_ErrResElectcLockClsErrDTC:0]}, required-interface=IF_OBCMgmt_ElectcLockClsErrDTC_Bus
      RTE_R_OBCMgmt_CPStsJmpErrDTC_Bus: nonqueued-receiver-com-spec{data-element=tec_OBCMgmt_CPStsJmpErrDTC_Bus, filter=data-filter-type=ALWAYS, init-value=fields=[OBCMgmt_MonStatCPStsJmpErrDTC:0, OBCMgmt_MonResCPStsJmpErrDTC:0, OBCMgmt_ErrStatCPStsJmpErrDTC:0, OBCMgmt_ErrResCPStsJmpErrDTC:0]}, required-interface=IF_OBCMgmt_CPStsJmpErrDTC_Bus
      RTE_R_LvMgmt_LvSysLoUdcDTC_Bus: nonqueued-receiver-com-spec{data-element=tec_LvMgmt_LvSysLoUdcDTC_Bus, filter=data-filter-type=ALWAYS, init-value=fields=[LvMgmt_MonStatLvSysLoUDcDTC:0, LvMgmt_MonResLvSysLoUDcDTC:0, LvMgmt_ErrStatLvSysLoUDcDTC:0, LvMgmt_ErrResLvSysLoUDcDTC:0]}, required-interface=IF_LvMgmt_LvSysLoUdcDTC_Bus
      RTE_R_OBCMgmt_OBCDiErrDTC_Bus: nonqueued-receiver-com-spec{data-element=tec_OBCMgmt_OBCDiErrDTC_Bus, filter=data-filter-type=ALWAYS, init-value=fields=[OBCMgmt_MonStatOBCDiErrDTC:0, OBCMgmt_MonResOBCDiErrDTC:0, OBCMgmt_ErrStatOBCDiErrDTC:0, OBCMgmt_ErrResOBCDiErrDTC:0]}, required-interface=IF_OBCMgmt_OBCDiErrDTC_Bus
      RTE_R_OBCMgmt_OBCChrgStsErrDTC_Bus: nonqueued-receiver-com-spec{data-element=tec_OBCMgmt_OBCChrgStsErrDTC_Bus, filter=data-filter-type=ALWAYS, init-value=fields=[OBCMgmt_MonStatOBCChrgStsErrDTC:0, OBCMgmt_MonResOBCChrgStsErrDTC:0, OBCMgmt_ErrStatOBCChrgStsErrDTC:0, OBCMgmt_ErrResOBCChrgStsErrDTC:0]}, required-interface=IF_OBCMgmt_OBCChrgStsErrDTC_Bus
      RTE_R_OBCMgmt_ElectcLockOpenErrDTC_Bus: nonqueued-receiver-com-spec{data-element=tec_OBCMgmt_ElectcLockOpenErrDTC_Bus, filter=data-filter-type=ALWAYS, init-value=fields=[OBCMgmt_MonStatElectcLockOpenErrDTC:0, OBCMgmt_MonResElectcLockOpenErrDTC:0, OBCMgmt_ErrStatElectcLockOpenErrDTC:0, OBCMgmt_ErrResElectcLockOpenErrDTC:0]}, required-interface=IF_OBCMgmt_ElectcLockOpenErrDTC_Bus
      RTE_R_OBCMgmt_OBCInpUDcLoErrDTC_Bus: nonqueued-receiver-com-spec{data-element=tec_OBCMgmt_OBCInpUDcLoErrDTC_Bus, filter=data-filter-type=ALWAYS, init-value=fields=[OBCMgmt_MonStatOBCInpUDcLoErrDTC:0, OBCMgmt_MonResOBCInpUDcLoErrDTC:0, OBCMgmt_ErrStatOBCInpUDcLoErrDTC:0, OBCMgmt_ErrResOBCInpUDcLoErrDTC:0]}, required-interface=IF_OBCMgmt_OBCInpUDcLoErrDTC_Bus
      RTE_R_OBCMgmt_OBCDchaStsErrDTC_Bus: nonqueued-receiver-com-spec{data-element=tec_OBCMgmt_OBCDchaStsErrDTC_Bus, filter=data-filter-type=ALWAYS, init-value=fields=[OBCMgmt_MonStatOBCDchaStsErrDTC:0, OBCMgmt_MonResOBCDchaStsErrDTC:0, OBCMgmt_ErrStatOBCDchaStsErrDTC:0, OBCMgmt_ErrResOBCDchaStsErrDTC:0]}, required-interface=IF_OBCMgmt_OBCDchaStsErrDTC_Bus
      RTE_R_OBCMgmt_S2SwtOpenErrDTC_Bus: nonqueued-receiver-com-spec{data-element=tec_OBCMgmt_S2SwtOpenErrDTC_Bus, filter=data-filter-type=ALWAYS, init-value=fields=[OBCMgmt_MonStatS2SwtOpenErrDTC:0, OBCMgmt_MonResS2SwtOpenErrDTC:0, OBCMgmt_ErrStatS2SwtOpenErrDTC:0, OBCMgmt_ErrResS2SwtOpenErrDTC:0]}, required-interface=IF_OBCMgmt_S2SwtOpenErrDTC_Bus
      RTE_R_OBCMgmt_S2SwtClsErrDTC_Bus: nonqueued-receiver-com-spec{data-element=tec_OBCMgmt_S2SwtClsErrDTC_Bus, filter=data-filter-type=ALWAYS, init-value=fields=[OBCMgmt_MonStatS2SwtClsErrDTC:0, OBCMgmt_MonResS2SwtClsErrDTC:0, OBCMgmt_ErrStatS2SwtClsErrDTC:0, OBCMgmt_ErrResS2SwtClsErrDTC:0]}, required-interface=IF_OBCMgmt_S2SwtClsErrDTC_Bus
      RTE_R_OBCMgmt_OBCPreheatStsErrDTC_Bus: nonqueued-receiver-com-spec{data-element=tec_OBCMgmt_OBCPreheatStsErrDTC_Bus, filter=data-filter-type=ALWAYS, init-value=fields=[OBCMgmt_MonStatOBCPreheatStsErrDTC:0, OBCMgmt_MonResOBCPreheatStsErrDTC:0, OBCMgmt_ErrStatOBCPreheatStsErrDTC:0, OBCMgmt_ErrResOBCPreheatStsErrDTC:0]}, required-interface=IF_OBCMgmt_OBCPreheatStsErrDTC_Bus
      RTE_R_HvMgmt_DCDCEnaFltDTC_Bus: nonqueued-receiver-com-spec{data-element=tec_HvMgmt_DCDCEnaFltDTC_Bus, filter=data-filter-type=ALWAYS, init-value=fields=[HvMgmt_MonStatDCDCEnaFltDTC:0, HvMgmt_MonResDCDCEnaFltDTC:0, HvMgmt_ErrStatDCDCEnaFltDTC:0, HvMgmt_ErrResDCDCEnaFltDTC:0]}, required-interface=IF_HvMgmt_DCDCEnaFltDTC_Bus
      RTE_R_HvMgmt_DCFCRlyClsDTC_Bus: nonqueued-receiver-com-spec{data-element=tec_HvMgmt_DCFCRlyClsDTC_Bus, filter=data-filter-type=ALWAYS, init-value=fields=[HvMgmt_MonStatDCFCRlyClsDTC:0, HvMgmt_MonResDCFCRlyClsDTC:0, HvMgmt_ErrStatDCFCRlyClsDTC:0, HvMgmt_ErrResDCFCRlyClsDTC:0]}, required-interface=IF_HvMgmt_DCFCRlyClsDTC_Bus
      RTE_R_HvMgmt_MCUEnaFltDTC_Bus: nonqueued-receiver-com-spec{data-element=tec_HvMgmt_MCUEnaFltDTC_Bus, filter=data-filter-type=ALWAYS, init-value=fields=[HvMgmt_MonStatMCUEnaFltDTC:0, HvMgmt_MonResMCUEnaFltDTC:0, HvMgmt_ErrStatMCUEnaFltDTC:0, HvMgmt_ErrResMCUEnaFltDTC:0]}, required-interface=IF_HvMgmt_MCUEnaFltDTC_Bus
      RTE_R_HvMgmt_DCDCStopFltDTC_Bus: nonqueued-receiver-com-spec{data-element=tec_HvMgmt_DCDCStopFltDTC_Bus, filter=data-filter-type=ALWAYS, init-value=fields=[HvMgmt_MonStatDCDCStopFltDTC:0, HvMgmt_MonResDCDCStopFltDTC:0, HvMgmt_ErrStatDCDCStopFltDTC:0, HvMgmt_ErrResDCDCStopFltDTC:0]}, required-interface=IF_HvMgmt_DCDCStopFltDTC_Bus
      RTE_R_HvMgmt_MCURdyFltDTC_Bus: nonqueued-receiver-com-spec{data-element=tec_HvMgmt_MCURdyFltDTC_Bus, filter=data-filter-type=ALWAYS, init-value=fields=[HvMgmt_MonStatMCURdyFltDTC:0, HvMgmt_MonResMCURdyFltDTC:0, HvMgmt_ErrStatMCURdyFltDTC:0, HvMgmt_ErrResMCURdyFltDTC:0]}, required-interface=IF_HvMgmt_MCURdyFltDTC_Bus
      RTE_R_HvMgmt_MCUClsFltDTC_Bus: nonqueued-receiver-com-spec{data-element=tec_HvMgmt_MCUClsFltDTC_Bus, filter=data-filter-type=ALWAYS, init-value=fields=[HvMgmt_MonStatMCUClsFltDTC:0, HvMgmt_MonResMCUClsFltDTC:0, HvMgmt_ErrStatMCUClsFltDTC:0, HvMgmt_ErrResMCUClsFltDTC:0]}, required-interface=IF_HvMgmt_MCUClsFltDTC_Bus
      RTE_R_FctSftyMon_ActGearCfmFail_Bus: nonqueued-receiver-com-spec{data-element=tec_FctSftyMon_ActGearCfmFail_Bus, filter=data-filter-type=ALWAYS, init-value=fields=[FctSftyMon_MonStatActGearCfmFail:0, FctSftyMon_MonResActGearCfmFail:0, FctSftyMon_ErrStatActGearCfmFail:0, FctSftyMon_ErrResActGearCfmFail:0]}, required-interface=IF_FctSftyMon_ActGearCfmFail_Bus
      RTE_R_ComM_LinMsgErrInfo_Bus: nonqueued-receiver-com-spec{data-element=tec_ComM_LinMsgErrInfo_Bus, filter=data-filter-type=ALWAYS, init-value=fields=[ComM_MonStatLinMsgTimeoutDTCInfo:0, ComM_MonResLinMsgTimeoutDTCInfo:0, ComM_ErrStatLinMsgTimeoutDTCInfo:0, ComM_ErrRestatLinMsgTimeoutDTCInfo:0]}, required-interface=IF_ComM_LinMsgErrInfo_Bus
      RTE_R_ComM_CANBusOffInfo_Bus: required-interface=IF_ComM_CANBusOffInfo_Bus
        required-com-specs:
          data-element=tec_ComM_EPTCANBusOffInfo_Bus, filter=data-filter-type=ALWAYS, init-value=fields=[ComM_MonStatEPTCANBusOffInfo:0, ComM_MonResEPTCANBusOffInfo:0, ComM_ErrStatEPTCANBusOffInfo:0, ComM_ErrResEPTCANBusOffInfo:0]
          data-element=tec_ComM_CHCANBusOffInfo_Bus, filter=data-filter-type=ALWAYS, init-value=fields=[ComM_MonStatCHCANBusOffInfo:0, ComM_MonResCHCANBusOffInfo:0, ComM_ErrStatCHCANBusOffInfo:0, ComM_ErrResCHCANBusOffInfo:0]
          data-element=tec_ComM_EPTCANBusOffDTCInfo_Bus, filter=data-filter-type=ALWAYS, init-value=fields=[ComM_MonStatEPTCANBusOffDTCInfo:0, ComM_MonResEPTCANBusOffDTCInfo:0, ComM_ErrStatEPTCANBusOffDTCInfo:0, ComM_ErrResEPTCANBusOffDTCInfo:0]
          data-element=tec_ComM_CHCANBusOffDTCInfo_Bus, filter=data-filter-type=ALWAYS, init-value=fields=[ComM_MonStatCHCANBusOffDTCInfo:0, ComM_MonResCHCANBusOffDTCInfo:0, ComM_ErrStatCHCANBusOffDTCInfo:0, ComM_ErrResCHCANBusOffDTCInfo:0]
          data-element=tec_ComM_DCCANBusOffDTCInfo_Bus, init-value=fields=[ComM_MonStatDCCANDTCBusOffInfo:0, ComM_MonResDCCANDTCBusOffInfo:0, ComM_ErrStatDCCANDTCBusOffInfo:0, ComM_ErrResDCCANDTCBusOffInfo:0]
          data-element=tec_ComM_DCCANBusOffInfo_Bus, init-value=fields=[ComM_MonStatDCCANBusOffInfo:0, ComM_MonResDCCANBusOffInfo:0, ComM_ErrStatDCCANBusOffInfo:0, ComM_ErrResDCCANBusOffInfo:0]
      RTE_R_ChassisMgmt_AccrPedlSplyVolt2LoDTCInfo: nonqueued-receiver-com-spec{data-element=tec_ChassisMgmt_AccrPedlSplyVolt2LoDTCInfo, filter=data-filter-type=ALWAYS, init-value=fields=[ChassisMgmt_MonStatAccrPedlSplyVolt2LoInfo:0, ChassisMgmt_MonResAccrPedlSplyVolt2LoInfo:0, ChassisMgmt_ErrStatAccrPedlSplyVolt2LoInfo:0, ChassisMgmt_ErrResAccrPedlSplyVolt2LoInfo:0]}, required-interface=IF_ChassisMgmt_AccrPedlSplyVolt2LoDTCInfo
      RTE_R_ChassisMgmt_AccrPedlSplyVolt2HiDTCInfo: nonqueued-receiver-com-spec{data-element=tec_ChassisMgmt_AccrPedlSplyVolt2HiDTCInfo, filter=data-filter-type=ALWAYS, init-value=fields=[ChassisMgmt_MonStatAccrPedlSplyVolt2HiInfo:0, ChassisMgmt_MonResAccrPedlSplyVolt2HiInfo:0, ChassisMgmt_ErrStatAccrPedlSplyVolt2HiInfo:0, ChassisMgmt_ErrResAccrPedlSplyVolt2HiInfo:0]}, required-interface=IF_ChassisMgmt_AccrPedlSplyVolt2HiDTCInfo
      RTE_R_ChassisMgmt_AccrPedlSplyVolt1LoDTCInfo: nonqueued-receiver-com-spec{data-element=tec_ChassisMgmt_AccrPedlSplyVolt1LoDTCInfo, filter=data-filter-type=ALWAYS, init-value=fields=[ChassisMgmt_MonStatAccrPedlSplyVolt1LoInfo:0, ChassisMgmt_MonResAccrPedlSplyVolt1LoInfo:0, ChassisMgmt_ErrStatAccrPedlSplyVolt1LoInfo:0, ChassisMgmt_ErrResAccrPedlSplyVolt1LoInfo:0]}, required-interface=IF_ChassisMgmt_AccrPedlSplyVolt1LoDTCInfo
      RTE_R_ChassisMgmt_AccrPedlSplyVolt1HiDTCInfo: nonqueued-receiver-com-spec{data-element=tec_ChassisMgmt_AccrPedlSplyVolt1HiDTCInfo, filter=data-filter-type=ALWAYS, init-value=fields=[ChassisMgmt_MonStatAccrPedlSplyVolt1HiInfo:0, ChassisMgmt_MonResAccrPedlSplyVolt1HiInfo:0, ChassisMgmt_ErrStatAccrPedlSplyVolt1HiInfo:0, ChassisMgmt_ErrResAccrPedlSplyVolt1HiInfo:0]}, required-interface=IF_ChassisMgmt_AccrPedlSplyVolt1HiDTCInfo
    provide port VCU_DTC_Num: nonqueued-sender-com-spec{data-element=SG_VCU_DiagInfor_SigGroup, init-value=fields=VCU_DTC_Number:0}, provided-interface=SG_VCU_DiagInfor_SigGroup_2
    53 x require port:
      Event_DTC_0x117205: required-interface=DiagnosticMonitor
        required-com-specs:
          GetEventExtendedDataRecordEx
          GetEventFreezeFrameDataEx
          GetFaultDetectionCounter
          GetDTCOfEvent
          GetEventTested
          GetEventFailed
          GetEventStatus
          GetEventUdsStatus
          ResetEventDebounceStatus
          ResetEventStatus
          SetEventStatus
      Event_DTC_0x117305: required-interface=DiagnosticMonitor
        required-com-specs:
          GetEventExtendedDataRecordEx
          GetEventFreezeFrameDataEx
          GetFaultDetectionCounter
          GetDTCOfEvent
          GetEventTested
          GetEventFailed
          GetEventStatus
          GetEventUdsStatus
          ResetEventDebounceStatus
          ResetEventStatus
          SetEventStatus
      Event_DTC_0x117405: required-interface=DiagnosticMonitor
        required-com-specs:
          GetEventExtendedDataRecordEx
          GetEventFreezeFrameDataEx
          GetFaultDetectionCounter
          GetDTCOfEvent
          GetEventTested
          GetEventFailed
          GetEventStatus
          GetEventUdsStatus
          ResetEventDebounceStatus
          ResetEventStatus
          SetEventStatus
      Event_DTC_0xc20087: required-interface=DiagnosticMonitor
        required-com-specs:
          GetEventExtendedDataRecordEx
          GetEventFreezeFrameDataEx
          GetFaultDetectionCounter
          GetDTCOfEvent
          GetEventTested
          GetEventFailed
          GetEventStatus
          GetEventUdsStatus
          ResetEventDebounceStatus
          ResetEventStatus
          SetEventStatus
      Event_DTC_0xc20187: required-interface=DiagnosticMonitor
        required-com-specs:
          GetEventExtendedDataRecordEx
          GetEventFreezeFrameDataEx
          GetFaultDetectionCounter
          GetDTCOfEvent
          GetEventTested
          GetEventFailed
          GetEventStatus
          GetEventUdsStatus
          ResetEventDebounceStatus
          ResetEventStatus
          SetEventStatus
      Event_DTC_0xc20287: required-interface=DiagnosticMonitor
        required-com-specs:
          GetEventExtendedDataRecordEx
          GetEventFreezeFrameDataEx
          GetFaultDetectionCounter
          GetDTCOfEvent
          GetEventTested
          GetEventFailed
          GetEventStatus
          GetEventUdsStatus
          ResetEventDebounceStatus
          ResetEventStatus
          SetEventStatus
      Event_DTC_0xd12688: required-interface=DiagnosticMonitor
        required-com-specs:
          GetEventExtendedDataRecordEx
          GetEventFreezeFrameDataEx
          GetFaultDetectionCounter
          GetDTCOfEvent
          GetEventTested
          GetEventFailed
          GetEventStatus
          GetEventUdsStatus
          ResetEventDebounceStatus
          ResetEventStatus
          SetEventStatus
      Event_DTC_0xc14887: required-interface=DiagnosticMonitor
        required-com-specs:
          GetEventExtendedDataRecordEx
          GetEventFreezeFrameDataEx
          GetFaultDetectionCounter
          GetDTCOfEvent
          GetEventTested
          GetEventFailed
          GetEventStatus
          GetEventUdsStatus
          ResetEventDebounceStatus
          ResetEventStatus
          SetEventStatus
      Event_DTC_0xc29a00: required-interface=DiagnosticMonitor
        required-com-specs:
          GetEventExtendedDataRecordEx
          GetEventFreezeFrameDataEx
          GetFaultDetectionCounter
          GetDTCOfEvent
          GetEventTested
          GetEventFailed
          GetEventStatus
          GetEventUdsStatus
          ResetEventDebounceStatus
          ResetEventStatus
          SetEventStatus
      Event_DTC_0xc20787: required-interface=DiagnosticMonitor
        required-com-specs:
          GetEventExtendedDataRecordEx
          GetEventFreezeFrameDataEx
          GetFaultDetectionCounter
          GetDTCOfEvent
          GetEventTested
          GetEventFailed
          GetEventStatus
          GetEventUdsStatus
          ResetEventDebounceStatus
          ResetEventStatus
          SetEventStatus
      Event_DTC_0xc20700: required-interface=DiagnosticMonitor
        required-com-specs:
          GetEventExtendedDataRecordEx
          GetEventFreezeFrameDataEx
          GetFaultDetectionCounter
          GetDTCOfEvent
          GetEventTested
          GetEventFailed
          GetEventStatus
          GetEventUdsStatus
          ResetEventDebounceStatus
          ResetEventStatus
          SetEventStatus
      Event_DTC_0x117617: required-interface=DiagnosticMonitor
        required-com-specs:
          GetEventExtendedDataRecordEx
          GetEventFreezeFrameDataEx
          GetFaultDetectionCounter
          GetDTCOfEvent
          GetEventTested
          GetEventFailed
          GetEventStatus
          GetEventUdsStatus
          ResetEventDebounceStatus
          ResetEventStatus
          SetEventStatus
      Event_DTC_0x117716: required-interface=DiagnosticMonitor
        required-com-specs:
          GetEventExtendedDataRecordEx
          GetEventFreezeFrameDataEx
          GetFaultDetectionCounter
          GetDTCOfEvent
          GetEventTested
          GetEventFailed
          GetEventStatus
          GetEventUdsStatus
          ResetEventDebounceStatus
          ResetEventStatus
          SetEventStatus
      Event_DTC_0x117819: required-interface=DiagnosticMonitor
        required-com-specs:
          GetEventExtendedDataRecordEx
          GetEventFreezeFrameDataEx
          GetFaultDetectionCounter
          GetDTCOfEvent
          GetEventTested
          GetEventFailed
          GetEventStatus
          GetEventUdsStatus
          ResetEventDebounceStatus
          ResetEventStatus
          SetEventStatus
      Event_DTC_0x11794b: required-interface=DiagnosticMonitor
        required-com-specs:
          GetEventExtendedDataRecordEx
          GetEventFreezeFrameDataEx
          GetFaultDetectionCounter
          GetDTCOfEvent
          GetEventTested
          GetEventFailed
          GetEventStatus
          GetEventUdsStatus
          ResetEventDebounceStatus
          ResetEventStatus
          SetEventStatus
      Event_DTC_0x117a4c: required-interface=DiagnosticMonitor
        required-com-specs:
          GetEventExtendedDataRecordEx
          GetEventFreezeFrameDataEx
          GetFaultDetectionCounter
          GetDTCOfEvent
          GetEventTested
          GetEventFailed
          GetEventStatus
          GetEventUdsStatus
          ResetEventDebounceStatus
          ResetEventStatus
          SetEventStatus
      Event_DTC_0x117b94: required-interface=DiagnosticMonitor
        required-com-specs:
          GetEventExtendedDataRecordEx
          GetEventFreezeFrameDataEx
          GetFaultDetectionCounter
          GetDTCOfEvent
          GetEventTested
          GetEventFailed
          GetEventStatus
          GetEventUdsStatus
          ResetEventDebounceStatus
          ResetEventStatus
          SetEventStatus
      Event_DTC_0x117c08: required-interface=DiagnosticMonitor
        required-com-specs:
          GetEventExtendedDataRecordEx
          GetEventFreezeFrameDataEx
          GetFaultDetectionCounter
          GetDTCOfEvent
          GetEventTested
          GetEventFailed
          GetEventStatus
          GetEventUdsStatus
          ResetEventDebounceStatus
          ResetEventStatus
          SetEventStatus
      Event_DTC_0x117d08: required-interface=DiagnosticMonitor
        required-com-specs:
          GetEventExtendedDataRecordEx
          GetEventFreezeFrameDataEx
          GetFaultDetectionCounter
          GetDTCOfEvent
          GetEventTested
          GetEventFailed
          GetEventStatus
          GetEventUdsStatus
          ResetEventDebounceStatus
          ResetEventStatus
          SetEventStatus
      Event_DTC_0x117e52: required-interface=DiagnosticMonitor
        required-com-specs:
          GetEventExtendedDataRecordEx
          GetEventFreezeFrameDataEx
          GetFaultDetectionCounter
          GetDTCOfEvent
          GetEventTested
          GetEventFailed
          GetEventStatus
          GetEventUdsStatus
          ResetEventDebounceStatus
          ResetEventStatus
          SetEventStatus
      Event_DTC_0x117f08: required-interface=DiagnosticMonitor
        required-com-specs:
          GetEventExtendedDataRecordEx
          GetEventFreezeFrameDataEx
          GetFaultDetectionCounter
          GetDTCOfEvent
          GetEventTested
          GetEventFailed
          GetEventStatus
          GetEventUdsStatus
          ResetEventDebounceStatus
          ResetEventStatus
          SetEventStatus
      EvtInfo_DTC_0x117205: required-interface=DiagnosticInfo
        required-com-specs:
          GetMonitorStatus
          GetDebouncingOfEvent
          GetEventEnableCondition
          GetEventExtendedDataRecordEx
          GetEventFreezeFrameDataEx
          GetFaultDetectionCounter
          GetDTCOfEvent
          GetEventTested
          GetEventFailed
          GetEventStatus
          GetEventUdsStatus
      EvtInfo_DTC_0x117305: required-interface=DiagnosticInfo
        required-com-specs:
          GetMonitorStatus
          GetDebouncingOfEvent
          GetEventEnableCondition
          GetEventExtendedDataRecordEx
          GetEventFreezeFrameDataEx
          GetFaultDetectionCounter
          GetDTCOfEvent
          GetEventTested
          GetEventFailed
          GetEventStatus
          GetEventUdsStatus
      EvtInfo_DTC_0x117405: required-interface=DiagnosticInfo
        required-com-specs:
          GetMonitorStatus
          GetDebouncingOfEvent
          GetEventEnableCondition
          GetEventExtendedDataRecordEx
          GetEventFreezeFrameDataEx
          GetFaultDetectionCounter
          GetDTCOfEvent
          GetEventTested
          GetEventFailed
          GetEventStatus
          GetEventUdsStatus
      EvtInfo_DTC_0xc20087: required-interface=DiagnosticInfo
        required-com-specs:
          GetMonitorStatus
          GetDebouncingOfEvent
          GetEventEnableCondition
          GetEventExtendedDataRecordEx
          GetEventFreezeFrameDataEx
          GetFaultDetectionCounter
          GetDTCOfEvent
          GetEventTested
          GetEventFailed
          GetEventStatus
          GetEventUdsStatus
      EvtInfo_DTC_0xc20187: required-interface=DiagnosticInfo
        required-com-specs:
          GetMonitorStatus
          GetDebouncingOfEvent
          GetEventEnableCondition
          GetEventExtendedDataRecordEx
          GetEventFreezeFrameDataEx
          GetFaultDetectionCounter
          GetDTCOfEvent
          GetEventTested
          GetEventFailed
          GetEventStatus
          GetEventUdsStatus
      EvtInfo_DTC_0xc20287: required-interface=DiagnosticInfo
        required-com-specs:
          GetMonitorStatus
          GetDebouncingOfEvent
          GetEventEnableCondition
          GetEventExtendedDataRecordEx
          GetEventFreezeFrameDataEx
          GetFaultDetectionCounter
          GetDTCOfEvent
          GetEventTested
          GetEventFailed
          GetEventStatus
          GetEventUdsStatus
      EvtInfo_DTC_0xd12688: required-interface=DiagnosticInfo
        required-com-specs:
          GetMonitorStatus
          GetDebouncingOfEvent
          GetEventEnableCondition
          GetEventExtendedDataRecordEx
          GetEventFreezeFrameDataEx
          GetFaultDetectionCounter
          GetDTCOfEvent
          GetEventTested
          GetEventFailed
          GetEventStatus
          GetEventUdsStatus
      EvtInfo_DTC_0xc14887: required-interface=DiagnosticInfo
        required-com-specs:
          GetMonitorStatus
          GetDebouncingOfEvent
          GetEventEnableCondition
          GetEventExtendedDataRecordEx
          GetEventFreezeFrameDataEx
          GetFaultDetectionCounter
          GetDTCOfEvent
          GetEventTested
          GetEventFailed
          GetEventStatus
          GetEventUdsStatus
      EvtInfo_DTC_0xc29a00: required-interface=DiagnosticInfo
        required-com-specs:
          GetMonitorStatus
          GetDebouncingOfEvent
          GetEventEnableCondition
          GetEventExtendedDataRecordEx
          GetEventFreezeFrameDataEx
          GetFaultDetectionCounter
          GetDTCOfEvent
          GetEventTested
          GetEventFailed
          GetEventStatus
          GetEventUdsStatus
      EvtInfo_DTC_0xc20787: required-interface=DiagnosticInfo
        required-com-specs:
          GetMonitorStatus
          GetDebouncingOfEvent
          GetEventEnableCondition
          GetEventExtendedDataRecordEx
          GetEventFreezeFrameDataEx
          GetFaultDetectionCounter
          GetDTCOfEvent
          GetEventTested
          GetEventFailed
          GetEventStatus
          GetEventUdsStatus
      EvtInfo_DTC_0xc20700: required-interface=DiagnosticInfo
        required-com-specs:
          GetMonitorStatus
          GetDebouncingOfEvent
          GetEventEnableCondition
          GetEventExtendedDataRecordEx
          GetEventFreezeFrameDataEx
          GetFaultDetectionCounter
          GetDTCOfEvent
          GetEventTested
          GetEventFailed
          GetEventStatus
          GetEventUdsStatus
      EvtInfo_DTC_0x117617: required-interface=DiagnosticInfo
        required-com-specs:
          GetMonitorStatus
          GetDebouncingOfEvent
          GetEventEnableCondition
          GetEventExtendedDataRecordEx
          GetEventFreezeFrameDataEx
          GetFaultDetectionCounter
          GetDTCOfEvent
          GetEventTested
          GetEventFailed
          GetEventStatus
          GetEventUdsStatus
      EvtInfo_DTC_0x117716: required-interface=DiagnosticInfo
        required-com-specs:
          GetMonitorStatus
          GetDebouncingOfEvent
          GetEventEnableCondition
          GetEventExtendedDataRecordEx
          GetEventFreezeFrameDataEx
          GetFaultDetectionCounter
          GetDTCOfEvent
          GetEventTested
          GetEventFailed
          GetEventStatus
          GetEventUdsStatus
      EvtInfo_DTC_0x117819: required-interface=DiagnosticInfo
        required-com-specs:
          GetMonitorStatus
          GetDebouncingOfEvent
          GetEventEnableCondition
          GetEventExtendedDataRecordEx
          GetEventFreezeFrameDataEx
          GetFaultDetectionCounter
          GetDTCOfEvent
          GetEventTested
          GetEventFailed
          GetEventStatus
          GetEventUdsStatus
      EvtInfo_DTC_0x11794b: required-interface=DiagnosticInfo
        required-com-specs:
          GetMonitorStatus
          GetDebouncingOfEvent
          GetEventEnableCondition
          GetEventExtendedDataRecordEx
          GetEventFreezeFrameDataEx
          GetFaultDetectionCounter
          GetDTCOfEvent
          GetEventTested
          GetEventFailed
          GetEventStatus
          GetEventUdsStatus
      EvtInfo_DTC_0x117a4c: required-interface=DiagnosticInfo
        required-com-specs:
          GetMonitorStatus
          GetDebouncingOfEvent
          GetEventEnableCondition
          GetEventExtendedDataRecordEx
          GetEventFreezeFrameDataEx
          GetFaultDetectionCounter
          GetDTCOfEvent
          GetEventTested
          GetEventFailed
          GetEventStatus
          GetEventUdsStatus
      EvtInfo_DTC_0x117b94: required-interface=DiagnosticInfo
        required-com-specs:
          GetMonitorStatus
          GetDebouncingOfEvent
          GetEventEnableCondition
          GetEventExtendedDataRecordEx
          GetEventFreezeFrameDataEx
          GetFaultDetectionCounter
          GetDTCOfEvent
          GetEventTested
          GetEventFailed
          GetEventStatus
          GetEventUdsStatus
      EvtInfo_DTC_0x117c08: required-interface=DiagnosticInfo
        required-com-specs:
          GetMonitorStatus
          GetDebouncingOfEvent
          GetEventEnableCondition
          GetEventExtendedDataRecordEx
          GetEventFreezeFrameDataEx
          GetFaultDetectionCounter
          GetDTCOfEvent
          GetEventTested
          GetEventFailed
          GetEventStatus
          GetEventUdsStatus
      EvtInfo_DTC_0x117d08: required-interface=DiagnosticInfo
        required-com-specs:
          GetMonitorStatus
          GetDebouncingOfEvent
          GetEventEnableCondition
          GetEventExtendedDataRecordEx
          GetEventFreezeFrameDataEx
          GetFaultDetectionCounter
          GetDTCOfEvent
          GetEventTested
          GetEventFailed
          GetEventStatus
          GetEventUdsStatus
      EvtInfo_DTC_0x117e52: required-interface=DiagnosticInfo
        required-com-specs:
          GetMonitorStatus
          GetDebouncingOfEvent
          GetEventEnableCondition
          GetEventExtendedDataRecordEx
          GetEventFreezeFrameDataEx
          GetFaultDetectionCounter
          GetDTCOfEvent
          GetEventTested
          GetEventFailed
          GetEventStatus
          GetEventUdsStatus
      EvtInfo_DTC_0x117f08: required-interface=DiagnosticInfo
        required-com-specs:
          GetMonitorStatus
          GetDebouncingOfEvent
          GetEventEnableCondition
          GetEventExtendedDataRecordEx
          GetEventFreezeFrameDataEx
          GetFaultDetectionCounter
          GetDTCOfEvent
          GetEventTested
          GetEventFailed
          GetEventStatus
          GetEventUdsStatus
      RTE_R_LvMgmt_BSRespErrDTC_Bus: nonqueued-receiver-com-spec{data-element=tec_LvMgmt_BSRespErrDTC_Bus, filter=data-filter-type=ALWAYS, init-value=fields=[LvMgmt_MonStatBSRespErrDTC:0, LvMgmt_MonResBSRespErrDTC:0, LvMgmt_ErrStatBSRespErrDTC:0, LvMgmt_ErrResBSRespErrDTC:0]}, required-interface=IF_LvMgmt_BSRespErrDTC_Bus
      RTE_R_ComM_FRCMsgErrDTC_Bus: nonqueued-receiver-com-spec{data-element=tec_ComM_FRCMsgErrDTC_Bus, filter=data-filter-type=ALWAYS, init-value=fields=[ComM_MonStatFRCMsgErrDTC:0, ComM_MonResFRCMsgErrDTC:0, ComM_ErrStatFRCMsgErrDTC:0, ComM_ErrResFRCMsgErrDTC:0]}, required-interface=IF_ComM_FRCMsgErrDTC_Bus
      RTE_R_ComM_FRCRespErrDTC_Bus: nonqueued-receiver-com-spec{data-element=tec_ComM_FRCRespErrDTC_Bus, filter=data-filter-type=ALWAYS, init-value=fields=[ComM_MonStatLinFRCRespErrDTC:0, ComM_MonResLinFRCRespErrDTC:0, ComM_ErrStatFRCRespErrDTC:0, ComM_ErrResFRCRespErrDTC:0]}, required-interface=IF_ComM_FRCRespErrDTC_Bus
      RTE_R_ComM_FRCSplyUDcHiDTC_Bus: nonqueued-receiver-com-spec{data-element=tec_ComM_FRCSplyUDcHiDTC_Bus, filter=data-filter-type=ALWAYS, init-value=fields=[ComM_MonStatFRCSplyUDcHiDTC:0, ComM_MonResFRCSplyUDcHiDTC:0, ComM_ErrStatFRCSplyUDcHiDTC:0, ComM_ErrResFRCSplyUDcHiDTC:0]}, required-interface=IF_ComM_FRCSplyUDcHiDTC_Bus
      RTE_R_ComM_FRCSplyUDcLoDTC_Bus: nonqueued-receiver-com-spec{data-element=tec_ComM_FRCSplyUDcLoDTC_Bus, filter=data-filter-type=ALWAYS, init-value=fields=[ComM_MonStatFRCSplyUDcLoDTC:0, ComM_MonResFRCSplyUDcLoDTC:0, ComM_ErrStatFRCSplyUDcLoDTC:0, ComM_ErrResFRCSplyUDcLoDTC:0]}, required-interface=IF_ComM_FRCSplyUDcLoDTC_Bus
      RTE_R_LvMgmt_BSBattChrgIDcHiDTC_Bus: nonqueued-receiver-com-spec{data-element=tec_LvMgmt_BSBattChrgIDcHiDTC_Bus, filter=data-filter-type=ALWAYS, init-value=fields=[LvMgmt_MonStatBSBattChrgIDcHiDTC:0, LvMgmt_MonResBSBattChrgIDcHiDTC:0, LvMgmt_ErrStatBSBattChrgIDcHiDTC:0, LvMgmt_ErrResBSBattChrgIDcHiDTC:0]}, required-interface=IF_LvMgmt_BSBattChrgIDcHiDTC_Bus
      RTE_R_LvMgmt_BSBattTempHiDTC_Bus: nonqueued-receiver-com-spec{data-element=tec_LvMgmt_BSBattTempHiDTC_Bus, filter=data-filter-type=ALWAYS, init-value=fields=[LvMgmt_MonStatBSBattTempHiDTC:0, LvMgmt_MonResBSBattTempHiDTC:0, LvMgmt_ErrStatBSBattTempHiDTC:0, LvMgmt_ErrResBSBattTempHiDTC:0]}, required-interface=IF_LvMgmt_BSBattTempHiDTC_Bus
      RTE_R_LvMgmt_BSBattTempLoDTC_Bus: nonqueued-receiver-com-spec{data-element=tec_LvMgmt_BSBattTempLoDTC_Bus, filter=data-filter-type=ALWAYS, init-value=fields=[LvMgmt_MonStatBSBattTempLoDTC:0, LvMgmt_MonResBSBattTempLoDTC:0, LvMgmt_ErrStatBSBattTempLoDTC:0, LvMgmt_ErrResBSBattTempLoDTC:0]}, required-interface=IF_LvMgmt_BSBattTempLoDTC_Bus
      RTE_R_LvMgmt_BSBattSOCLoDTC_Bus: nonqueued-receiver-com-spec{data-element=tec_LvMgmt_BSBattSOCLoDTC_Bus, filter=data-filter-type=ALWAYS, init-value=fields=[LvMgmt_MonStatBSBattSOCLoDTC:0, LvMgmt_MonResBSBattSOCLoDTC:0, LvMgmt_ErrStatBSBattSOCLoDTC:0, LvMgmt_ErrResBSBattSOCLoDTC:0]}, required-interface=IF_LvMgmt_BSBattSOCLoDTC_Bus
      Event_DTC_0xC07388: required-interface=DiagnosticMonitor
        required-com-specs:
          GetEventExtendedDataRecordEx
          GetEventFreezeFrameDataEx
          GetFaultDetectionCounter
          GetDTCOfEvent
          GetEventTested
          GetEventFailed
          GetEventStatus
          GetEventUdsStatus
          ResetEventDebounceStatus
          ResetEventStatus
          SetEventStatus
      Event_DTC_0xC07488: required-interface=DiagnosticMonitor
        required-com-specs:
          GetEventExtendedDataRecordEx
          GetEventFreezeFrameDataEx
          GetFaultDetectionCounter
          GetDTCOfEvent
          GetEventTested
          GetEventFailed
          GetEventStatus
          GetEventUdsStatus
          ResetEventDebounceStatus
          ResetEventStatus
          SetEventStatus
    behavior YDF_ErrorHandler_InternalBehavior
      init event RYDF_ErrorHandler_InitEvent: start-on-event=RYDF_ErrorHandler_Init
      timing event TMT_RYDF_ErrorHandler_10ms: start-on-event=RYDF_ErrorHandler_10ms, period=0.01
      operation invoked event OIT_ErrorHandler_ReportError_ErrorHandler_ReportError: start-on-event=ErrorHandler_ReportError, operation=ErrorHandler.ReportError
      runnable RYDF_ErrorHandler_Init
      runnable RYDF_ErrorHandler_10ms
        data-receive-point-by-arguments:
          99 x access:
            REC_RTE_R_ChassisMgmt_AccrPedlURaw1HiDTC_Bus_tec_ChassisMgmt_AccrPedlURaw1HiDTC_Bus: accessed-variable=RTE_R_ChassisMgmt_AccrPedlURaw1HiDTC_Bus.tec_ChassisMgmt_AccrPedlURaw1HiDTC_Bus
            REC_RTE_R_ChassisMgmt_AccrPedlURaw1LoDTC_Bus_tec_ChassisMgmt_AccrPedlURaw1LoDTC_Bus: accessed-variable=RTE_R_ChassisMgmt_AccrPedlURaw1LoDTC_Bus.tec_ChassisMgmt_AccrPedlURaw1LoDTC_Bus
            REC_RTE_R_ChassisMgmt_AccrPedlURaw2HiDTC_Bus_tec_ChassisMgmt_AccrPedlURaw2HiDTC_Bus: accessed-variable=RTE_R_ChassisMgmt_AccrPedlURaw2HiDTC_Bus.tec_ChassisMgmt_AccrPedlURaw2HiDTC_Bus
            REC_RTE_R_ChassisMgmt_AccrPedlURaw2LoDTC_Bus_tec_ChassisMgmt_AccrPedlURaw2LoDTC_Bus: accessed-variable=RTE_R_ChassisMgmt_AccrPedlURaw2LoDTC_Bus.tec_ChassisMgmt_AccrPedlURaw2LoDTC_Bus
            REC_RTE_R_ChassisMgmt_AccrPedlURawDifDTC_Bus_tec_ChassisMgmt_AccrPedlURawDifDTC_Bus: accessed-variable=RTE_R_ChassisMgmt_AccrPedlURawDifDTC_Bus.tec_ChassisMgmt_AccrPedlURawDifDTC_Bus
            REC_RTE_R_ChassisMgmt_IBSApsCtrlDesTqOverFltDTCInfo_Bus_tec_ChassisMgmt_IBSApsCtrlDesTqOverFltDTCInfo_Bus: accessed-variable=RTE_R_ChassisMgmt_IBSApsCtrlDesTqOverFltDTCInfo_Bus.tec_ChassisMgmt_IBSApsCtrlDesTqOverFltDTCInfo_Bus
            REC_RTE_R_ChassisMgmt_IBSRbsDesTqOverFltDTCInfo_Bus_tec_ChassisMgmt_IBSRbsDesTqOverFltDTCInfo_Bus: accessed-variable=RTE_R_ChassisMgmt_IBSRbsDesTqOverFltDTCInfo_Bus.tec_ChassisMgmt_IBSRbsDesTqOverFltDTCInfo_Bus
            REC_RTE_R_ChassisMgmt_IBSVlcCtrlDesTqOverFltDTCInfo_Bus_tec_ChassisMgmt_IBSVlcCtrlDesTqOverFltDTCInfo_Bus: accessed-variable=RTE_R_ChassisMgmt_IBSVlcCtrlDesTqOverFltDTCInfo_Bus.tec_ChassisMgmt_IBSVlcCtrlDesTqOverFltDTCInfo_Bus
            REC_RTE_R_ChrMgmt_AcPreheatUDcCtrlErrDTC_Bus_tec_ChrMgmt_AcPreheatUDcCtrlErrDTC_Bus: accessed-variable=RTE_R_ChrMgmt_AcPreheatUDcCtrlErrDTC_Bus.tec_ChrMgmt_AcPreheatUDcCtrlErrDTC_Bus
            REC_RTE_R_ChrMgmt_CC2UDcDTC_Bus_tec_ChrMgmt_CC2UDcErrDTC_Bus: accessed-variable=RTE_R_ChrMgmt_CC2UDcDTC_Bus.tec_ChrMgmt_CC2UDcErrDTC_Bus
            REC_RTE_R_ChrMgmt_ChrgStsJmpDTC_Bus_tec_ChrMgmt_ChrgStsJmpErrDTC_Bus: accessed-variable=RTE_R_ChrMgmt_ChrgStsJmpDTC_Bus.tec_ChrMgmt_ChrgStsJmpErrDTC_Bus
            REC_RTE_R_ChrMgmt_DcPreheatUDcCtrlErrDTC_Bus_tec_ChrMgmt_DcPreheatUDcCtrlErrDTC_Bus: accessed-variable=RTE_R_ChrMgmt_DcPreheatUDcCtrlErrDTC_Bus.tec_ChrMgmt_DcPreheatUDcCtrlErrDTC_Bus
            REC_RTE_R_ChrMgmt_PreheatIRChkErrDTC_Bus_tec_ChrMgmt_PreheatIRChkErrDTC_Bus: accessed-variable=RTE_R_ChrMgmt_PreheatIRChkErrDTC_Bus.tec_ChrMgmt_PreheatIRChkErrDTC_Bus
            REC_RTE_R_ComM_CANBusOffInfo_Bus_tec_ComM_CHCANBusOffDTCInfo_Bus: accessed-variable=RTE_R_ComM_CANBusOffInfo_Bus.tec_ComM_CHCANBusOffDTCInfo_Bus
            REC_RTE_R_ComM_CANBusOffInfo_Bus_tec_ComM_EPTCANBusOffDTCInfo_Bus: accessed-variable=RTE_R_ComM_CANBusOffInfo_Bus.tec_ComM_EPTCANBusOffDTCInfo_Bus
            REC_RTE_R_ComM_ComDTCFailr_tec_ComM_ACUComDTCFailr_Flg: accessed-variable=RTE_R_ComM_ComDTCFailr.tec_ComM_ACUComDTCFailr_Flg
            REC_RTE_R_ComM_ComDTCFailr_tec_ComM_ADCUComDTCFailr_Flg: accessed-variable=RTE_R_ComM_ComDTCFailr.tec_ComM_ADCUComDTCFailr_Flg
            REC_RTE_R_ComM_ComDTCFailr_tec_ComM_APTCComDTCFailr_Flg: accessed-variable=RTE_R_ComM_ComDTCFailr.tec_ComM_APTCComDTCFailr_Flg
            REC_RTE_R_ComM_ComDTCFailr_tec_ComM_BCMComDTCFailr_Flg: accessed-variable=RTE_R_ComM_ComDTCFailr.tec_ComM_BCMComDTCFailr_Flg
            REC_RTE_R_ComM_ComDTCFailr_tec_ComM_BMSComDTCFailr_Flg: accessed-variable=RTE_R_ComM_ComDTCFailr.tec_ComM_BMSComDTCFailr_Flg
            REC_RTE_R_ComM_ComDTCFailr_tec_ComM_CGWComDTCFailr_Flg: accessed-variable=RTE_R_ComM_ComDTCFailr.tec_ComM_CGWComDTCFailr_Flg
            REC_RTE_R_ComM_ComDTCFailr_tec_ComM_CHIBSComDTCFailr_Flg: accessed-variable=RTE_R_ComM_ComDTCFailr.tec_ComM_CHIBSComDTCFailr_Flg
            REC_RTE_R_ComM_ComDTCFailr_tec_ComM_DCDCComDTCFailr_Flg: accessed-variable=RTE_R_ComM_ComDTCFailr.tec_ComM_DCDCComDTCFailr_Flg
            REC_RTE_R_ComM_ComDTCFailr_tec_ComM_EPTIBSComDTCFailr_Flg: accessed-variable=RTE_R_ComM_ComDTCFailr.tec_ComM_EPTIBSComDTCFailr_Flg
            REC_RTE_R_ComM_ComDTCFailr_tec_ComM_EVCOMComDTCFailr_Flg: accessed-variable=RTE_R_ComM_ComDTCFailr.tec_ComM_EVCOMComDTCFailr_Flg
            REC_RTE_R_ComM_ComDTCFailr_tec_ComM_IVIComDTCFailr_Flg: accessed-variable=RTE_R_ComM_ComDTCFailr.tec_ComM_IVIComDTCFailr_Flg
            REC_RTE_R_ComM_ComDTCFailr_tec_ComM_MCUComDTCFailr_Flg: accessed-variable=RTE_R_ComM_ComDTCFailr.tec_ComM_MCUComDTCFailr_Flg
            REC_RTE_R_ComM_ComDTCFailr_tec_ComM_OBCComDTCFailr_Flg: accessed-variable=RTE_R_ComM_ComDTCFailr.tec_ComM_OBCComDTCFailr_Flg
            REC_RTE_R_ComM_ComDTCFailr_tec_ComM_PRNDComDTCFailr_Flg: accessed-variable=RTE_R_ComM_ComDTCFailr.tec_ComM_PRNDComDTCFailr_Flg
            REC_RTE_R_ComM_ComDTCFailr_tec_ComM_SGWComDTCFailr_Flg: accessed-variable=RTE_R_ComM_ComDTCFailr.tec_ComM_SGWComDTCFailr_Flg
            REC_RTE_R_ComM_ComDTCFailr_tec_ComM_TCUComDTCFailr_Flg: accessed-variable=RTE_R_ComM_ComDTCFailr.tec_ComM_TCUComDTCFailr_Flg
            REC_RTE_R_ComM_LinMsgErrInfo_Bus_tec_ComM_LinMsgErrInfo_Bus: accessed-variable=RTE_R_ComM_LinMsgErrInfo_Bus.tec_ComM_LinMsgErrInfo_Bus
            REC_RTE_R_DCChrMgmt_BEMRxCCSTmtDTC_Bus_tec_DCChrMgmt_BEMRxCCSTmtDTC_Bus: accessed-variable=RTE_R_DCChrMgmt_BEMRxCCSTmtDTC_Bus.tec_DCChrMgmt_BEMRxCCSTmtDTC_Bus
            REC_RTE_R_DCChrMgmt_BEMRxCMLTmtDTC_Bus_tec_DCChrMgmt_BEMRxCMLTmtDTC_Bus: accessed-variable=RTE_R_DCChrMgmt_BEMRxCMLTmtDTC_Bus.tec_DCChrMgmt_BEMRxCMLTmtDTC_Bus
            REC_RTE_R_DCChrMgmt_BEMRxCRMPrepdTmtDTC_Bus_tec_DCChrMgmt_BEMRxCRMPrepdTmtDTC_Bus: accessed-variable=RTE_R_DCChrMgmt_BEMRxCRMPrepdTmtDTC_Bus.tec_DCChrMgmt_BEMRxCRMPrepdTmtDTC_Bus
            REC_RTE_R_DCChrMgmt_BEMRxCRMTmtDTC_Bus_tec_DCChrMgmt_BEMRxCRMTmtDTC_Bus: accessed-variable=RTE_R_DCChrMgmt_BEMRxCRMTmtDTC_Bus.tec_DCChrMgmt_BEMRxCRMTmtDTC_Bus
            REC_RTE_R_DCChrMgmt_BEMRxCROPrepdTmtDTC_Bus_tec_DCChrMgmt_BEMRxCROPrepdTmtDTC_Bus: accessed-variable=RTE_R_DCChrMgmt_BEMRxCROPrepdTmtDTC_Bus.tec_DCChrMgmt_BEMRxCROPrepdTmtDTC_Bus
            REC_RTE_R_DCChrMgmt_BEMRxCROTmtDTC_Bus_tec_DCChrMgmt_BEMRxCROTmtDTC_Bus: accessed-variable=RTE_R_DCChrMgmt_BEMRxCROTmtDTC_Bus.tec_DCChrMgmt_BEMRxCROTmtDTC_Bus
            REC_RTE_R_DCChrMgmt_BEMRxCSDTmtDTC_Bus_tec_DCChrMgmt_BEMRxCSDTmtDTC_Bus: accessed-variable=RTE_R_DCChrMgmt_BEMRxCSDTmtDTC_Bus.tec_DCChrMgmt_BEMRxCSDTmtDTC_Bus
            REC_RTE_R_DCChrMgmt_BEMRxCSTTmtDTC_Bus_tec_DCChrMgmt_BEMRxCSTTmtDTC_Bus: accessed-variable=RTE_R_DCChrMgmt_BEMRxCSTTmtDTC_Bus.tec_DCChrMgmt_BEMRxCSTTmtDTC_Bus
            REC_RTE_R_DCChrMgmt_DcPortTempErrLvl1DTC_Bus_tec_DCChrMgmt_DcPortTempErrLvl1DTC_Bus: accessed-variable=RTE_R_DCChrMgmt_DcPortTempErrLvl1DTC_Bus.tec_DCChrMgmt_DcPortTempErrLvl1DTC_Bus
            REC_RTE_R_DCChrMgmt_DcPortTempErrLvl2DTC_Bus_tec_DCChrMgmt_DcPortTempErrLvl2DTC_Bus: accessed-variable=RTE_R_DCChrMgmt_DcPortTempErrLvl2DTC_Bus.tec_DCChrMgmt_DcPortTempErrLvl2DTC_Bus
            REC_RTE_R_DCChrMgmt_DcPortTempSnsrErrDTC_Bus_tec_DCChrMgmt_DcPortTempSnsrErrDTC_Bus: accessed-variable=RTE_R_DCChrMgmt_DcPortTempSnsrErrDTC_Bus.tec_DCChrMgmt_DcPortTempSnsrErrDTC_Bus
            REC_RTE_R_DCChrMgmt_IRMeasDiErrDTC_Bus_tec_DCChrMgmt_IRMeasDiErrDTC_Bus: accessed-variable=RTE_R_DCChrMgmt_IRMeasDiErrDTC_Bus.tec_DCChrMgmt_IRMeasDiErrDTC_Bus
            REC_RTE_R_DCChrMgmt_IRMeasEnaErrDTC_Bus_tec_DCChrMgmt_IRMeasEnaErrDTC_Bus: accessed-variable=RTE_R_DCChrMgmt_IRMeasEnaErrDTC_Bus.tec_DCChrMgmt_IRMeasEnaErrDTC_Bus
            REC_RTE_R_ErrMgmt_VCUHVILDTC_Bus_tec_ErrMgmt_VCUHVILDTC_Bus: accessed-variable=RTE_R_ErrMgmt_VCUHVILDTC_Bus.tec_ErrMgmt_VCUHVILDTC_Bus
            REC_RTE_R_FctSftyMon_AccrPedlTqOverFltDTCInfo_Bus_tec_FctSftyMon_AccrPedlTqOverFltDTCInfo_Bus: accessed-variable=RTE_R_FctSftyMon_AccrPedlTqOverFltDTCInfo_Bus.tec_FctSftyMon_AccrPedlTqOverFltDTCInfo_Bus
            REC_RTE_R_FctSftyMon_ActGearCfmFail_Bus_tec_FctSftyMon_ActGearCfmFail_Bus: accessed-variable=RTE_R_FctSftyMon_ActGearCfmFail_Bus.tec_FctSftyMon_ActGearCfmFail_Bus
            REC_RTE_R_FctSftyMon_CrpCtrlTqOverFltDTCInfo_Bus_tec_FctSftyMon_CrpCtrlTqOverFltDTCInfo_Bus: accessed-variable=RTE_R_FctSftyMon_CrpCtrlTqOverFltDTCInfo_Bus.tec_FctSftyMon_CrpCtrlTqOverFltDTCInfo_Bus
            REC_RTE_R_FctSftyMon_DesVehDecelSpdOverFltDTCInfo_Bus_tec_FctSftyMon_DesVehDecelSpdOverFltDTCInfo_Bus: accessed-variable=RTE_R_FctSftyMon_DesVehDecelSpdOverFltDTCInfo_Bus.tec_FctSftyMon_DesVehDecelSpdOverFltDTCInfo_Bus
            REC_RTE_R_HvMgmt_BMSRlyClsDTC_Bus_tec_HvMgmt_BMSRlyClsDTC_Bus: accessed-variable=RTE_R_HvMgmt_BMSRlyClsDTC_Bus.tec_HvMgmt_BMSRlyClsDTC_Bus
            REC_RTE_R_HvMgmt_BMSRlyOpenDTC_Bus_tec_HvMgmt_BMSRlyOpenDTC_Bus: accessed-variable=RTE_R_HvMgmt_BMSRlyOpenDTC_Bus.tec_HvMgmt_BMSRlyOpenDTC_Bus
            REC_RTE_R_HvMgmt_DCDCEnaFltDTC_Bus_tec_HvMgmt_DCDCEnaFltDTC_Bus: accessed-variable=RTE_R_HvMgmt_DCDCEnaFltDTC_Bus.tec_HvMgmt_DCDCEnaFltDTC_Bus
            REC_RTE_R_HvMgmt_DCDCStopFltDTC_Bus_tec_HvMgmt_DCDCStopFltDTC_Bus: accessed-variable=RTE_R_HvMgmt_DCDCStopFltDTC_Bus.tec_HvMgmt_DCDCStopFltDTC_Bus
            REC_RTE_R_HvMgmt_DCFCRlyClsDTC_Bus_tec_HvMgmt_DCFCRlyClsDTC_Bus: accessed-variable=RTE_R_HvMgmt_DCFCRlyClsDTC_Bus.tec_HvMgmt_DCFCRlyClsDTC_Bus
            REC_RTE_R_HvMgmt_MCUClsFltDTC_Bus_tec_HvMgmt_MCUClsFltDTC_Bus: accessed-variable=RTE_R_HvMgmt_MCUClsFltDTC_Bus.tec_HvMgmt_MCUClsFltDTC_Bus
            REC_RTE_R_HvMgmt_MCUEnaFltDTC_Bus_tec_HvMgmt_MCUEnaFltDTC_Bus: accessed-variable=RTE_R_HvMgmt_MCUEnaFltDTC_Bus.tec_HvMgmt_MCUEnaFltDTC_Bus
            REC_RTE_R_HvMgmt_MCURdyFltDTC_Bus_tec_HvMgmt_MCURdyFltDTC_Bus: accessed-variable=RTE_R_HvMgmt_MCURdyFltDTC_Bus.tec_HvMgmt_MCURdyFltDTC_Bus
            REC_RTE_R_HvMgmt_PreheatPosRlyClsDTC_Bus_tec_HvMgmt_PreheatPosRlyClsDTC_Bus: accessed-variable=RTE_R_HvMgmt_PreheatPosRlyClsDTC_Bus.tec_HvMgmt_PreheatPosRlyClsDTC_Bus
            REC_RTE_R_HvMgmt_PreheatPosRlyOpenDTC_Bus_tec_HvMgmt_PreheatPosRlyOpenDTC_Bus: accessed-variable=RTE_R_HvMgmt_PreheatPosRlyOpenDTC_Bus.tec_HvMgmt_PreheatPosRlyOpenDTC_Bus
            REC_RTE_R_HvMgmt_TCUEnaFltDTC_Bus_tec_HvMgmt_TCUEnaFltDTC_Bus: accessed-variable=RTE_R_HvMgmt_TCUEnaFltDTC_Bus.tec_HvMgmt_TCUEnaFltDTC_Bus
            REC_RTE_R_HvMgmt_TCUStopFltDTC_Bus_tec_HvMgmt_TCUStopFltDTC_Bus: accessed-variable=RTE_R_HvMgmt_TCUStopFltDTC_Bus.tec_HvMgmt_TCUStopFltDTC_Bus
            REC_RTE_R_LvMgmt_BSBattIDcHiDTC_Bus_tec_LvMgmt_BSBattIDcHiDTC_Bus: accessed-variable=RTE_R_LvMgmt_BSBattIDcHiDTC_Bus.tec_LvMgmt_BSBattIDcHiDTC_Bus
            REC_RTE_R_LvMgmt_BSBattUDcHiDTC_Bus_tec_LvMgmt_BSBattUDcHiDTC_Bus: accessed-variable=RTE_R_LvMgmt_BSBattUDcHiDTC_Bus.tec_LvMgmt_BSBattUDcHiDTC_Bus
            REC_RTE_R_LvMgmt_BSBattUDcLoDTC_Bus_tec_LvMgmt_BSBattUDcLoDTC_Bus: accessed-variable=RTE_R_LvMgmt_BSBattUDcLoDTC_Bus.tec_LvMgmt_BSBattUDcLoDTC_Bus
            REC_RTE_R_LvMgmt_ECUsDiagDTC_Bus_tec_LvMgmt_ECUsDiagDTC_Bus: accessed-variable=RTE_R_LvMgmt_ECUsDiagDTC_Bus.tec_LvMgmt_ECUsDiagDTC_Bus
            REC_RTE_R_LvMgmt_KL15eOffDTC_Bus_tec_LvMgmt_KL15eOffDTC_Bus: accessed-variable=RTE_R_LvMgmt_KL15eOffDTC_Bus.tec_LvMgmt_KL15eOffDTC_Bus
            REC_RTE_R_LvMgmt_KL15eOnDTC_Bus_tec_LvMgmt_KL15eOnDTC_Bus: accessed-variable=RTE_R_LvMgmt_KL15eOnDTC_Bus.tec_LvMgmt_KL15eOnDTC_Bus
            REC_RTE_R_LvMgmt_LvSysLoUdcDTC_Bus_tec_LvMgmt_LvSysLoUdcDTC_Bus: accessed-variable=RTE_R_LvMgmt_LvSysLoUdcDTC_Bus.tec_LvMgmt_LvSysLoUdcDTC_Bus
            REC_RTE_R_LvMgmt_LvSysOvrUdcDTC_Bus_tec_LvMgmt_LvSysOvrUdcDTC_Bus: accessed-variable=RTE_R_LvMgmt_LvSysOvrUdcDTC_Bus.tec_LvMgmt_LvSysOvrUdcDTC_Bus
            REC_RTE_R_OBCMgmt_CPStsJmpErrDTC_Bus_tec_OBCMgmt_CPStsJmpErrDTC_Bus: accessed-variable=RTE_R_OBCMgmt_CPStsJmpErrDTC_Bus.tec_OBCMgmt_CPStsJmpErrDTC_Bus
            REC_RTE_R_OBCMgmt_ElectcLockClsErrDTC_Bus_tec_OBCMgmt_ElectcLockClsErrDTC_Bus: accessed-variable=RTE_R_OBCMgmt_ElectcLockClsErrDTC_Bus.tec_OBCMgmt_ElectcLockClsErrDTC_Bus
            REC_RTE_R_OBCMgmt_ElectcLockOpenErrDTC_Bus_tec_OBCMgmt_ElectcLockOpenErrDTC_Bus: accessed-variable=RTE_R_OBCMgmt_ElectcLockOpenErrDTC_Bus.tec_OBCMgmt_ElectcLockOpenErrDTC_Bus
            REC_RTE_R_OBCMgmt_OBCChrgStsErrDTC_Bus_tec_OBCMgmt_OBCChrgStsErrDTC_Bus: accessed-variable=RTE_R_OBCMgmt_OBCChrgStsErrDTC_Bus.tec_OBCMgmt_OBCChrgStsErrDTC_Bus
            REC_RTE_R_OBCMgmt_OBCDchaStsErrDTC_Bus_tec_OBCMgmt_OBCDchaStsErrDTC_Bus: accessed-variable=RTE_R_OBCMgmt_OBCDchaStsErrDTC_Bus.tec_OBCMgmt_OBCDchaStsErrDTC_Bus
            REC_RTE_R_OBCMgmt_OBCDiErrDTC_Bus_tec_OBCMgmt_OBCDiErrDTC_Bus: accessed-variable=RTE_R_OBCMgmt_OBCDiErrDTC_Bus.tec_OBCMgmt_OBCDiErrDTC_Bus
            REC_RTE_R_OBCMgmt_OBCInpUDcLoErrDTC_Bus_tec_OBCMgmt_OBCInpUDcLoErrDTC_Bus: accessed-variable=RTE_R_OBCMgmt_OBCInpUDcLoErrDTC_Bus.tec_OBCMgmt_OBCInpUDcLoErrDTC_Bus
            REC_RTE_R_OBCMgmt_OBCPreheatStsErrDTC_Bus_tec_OBCMgmt_OBCPreheatStsErrDTC_Bus: accessed-variable=RTE_R_OBCMgmt_OBCPreheatStsErrDTC_Bus.tec_OBCMgmt_OBCPreheatStsErrDTC_Bus
            REC_RTE_R_OBCMgmt_S2SwtClsErrDTC_Bus_tec_OBCMgmt_S2SwtClsErrDTC_Bus: accessed-variable=RTE_R_OBCMgmt_S2SwtClsErrDTC_Bus.tec_OBCMgmt_S2SwtClsErrDTC_Bus
            REC_RTE_R_OBCMgmt_S2SwtOpenErrDTC_Bus_tec_OBCMgmt_S2SwtOpenErrDTC_Bus: accessed-variable=RTE_R_OBCMgmt_S2SwtOpenErrDTC_Bus.tec_OBCMgmt_S2SwtOpenErrDTC_Bus
            REC_RTE_R_ComM_CANBusOffInfo_Bus_tec_ComM_DCCANBusOffDTCInfo_Bus: accessed-variable=RTE_R_ComM_CANBusOffInfo_Bus.tec_ComM_DCCANBusOffDTCInfo_Bus
            REC_RTE_R_ComM_ComDTCFailr_tec_ComM_DCMFLComDTCFailr_Flg: accessed-variable=RTE_R_ComM_ComDTCFailr.tec_ComM_DCMFLComDTCFailr_Flg
            REC_RTE_R_ComM_ComDTCFailr_tec_ComM_DCMFRComDTCFailr_Flg: accessed-variable=RTE_R_ComM_ComDTCFailr.tec_ComM_DCMFRComDTCFailr_Flg
            REC_RTE_R_ComM_ComDTCFailr_tec_ComM_DCMRLComDTCFailr_Flg: accessed-variable=RTE_R_ComM_ComDTCFailr.tec_ComM_DCMRLComDTCFailr_Flg
            REC_RTE_R_ComM_ComDTCFailr_tec_ComM_DCMRRComDTCFailr_Flg: accessed-variable=RTE_R_ComM_ComDTCFailr.tec_ComM_DCMRRComDTCFailr_Flg
            REC_RTE_R_ComM_ComDTCFailr_tec_ComM_SGWCHComDTCFailr_Flg: accessed-variable=RTE_R_ComM_ComDTCFailr.tec_ComM_SGWCHComDTCFailr_Flg
            REC_RTE_R_ChassisMgmt_AccrPedlSplyVolt1HiDTCInfo_tec_ChassisMgmt_AccrPedlSplyVolt1HiDTCInfo: accessed-variable=RTE_R_ChassisMgmt_AccrPedlSplyVolt1HiDTCInfo.tec_ChassisMgmt_AccrPedlSplyVolt1HiDTCInfo
            REC_RTE_R_ChassisMgmt_AccrPedlSplyVolt1LoDTCInfo_tec_ChassisMgmt_AccrPedlSplyVolt1LoDTCInfo: accessed-variable=RTE_R_ChassisMgmt_AccrPedlSplyVolt1LoDTCInfo.tec_ChassisMgmt_AccrPedlSplyVolt1LoDTCInfo
            REC_RTE_R_ChassisMgmt_AccrPedlSplyVolt2HiDTCInfo_tec_ChassisMgmt_AccrPedlSplyVolt2HiDTCInfo: accessed-variable=RTE_R_ChassisMgmt_AccrPedlSplyVolt2HiDTCInfo.tec_ChassisMgmt_AccrPedlSplyVolt2HiDTCInfo
            REC_RTE_R_ChassisMgmt_AccrPedlSplyVolt2LoDTCInfo_tec_ChassisMgmt_AccrPedlSplyVolt2LoDTCInfo: accessed-variable=RTE_R_ChassisMgmt_AccrPedlSplyVolt2LoDTCInfo.tec_ChassisMgmt_AccrPedlSplyVolt2LoDTCInfo
            REC_RTE_R_ComM_FRCMsgErrDTC_Bus_tec_ComM_FRCMsgErrDTC_Bus: accessed-variable=RTE_R_ComM_FRCMsgErrDTC_Bus.tec_ComM_FRCMsgErrDTC_Bus
            REC_RTE_R_ComM_FRCRespErrDTC_Bus_tec_ComM_FRCRespErrDTC_Bus: accessed-variable=RTE_R_ComM_FRCRespErrDTC_Bus.tec_ComM_FRCRespErrDTC_Bus
            REC_RTE_R_ComM_FRCSplyUDcHiDTC_Bus_tec_ComM_FRCSplyUDcHiDTC_Bus: accessed-variable=RTE_R_ComM_FRCSplyUDcHiDTC_Bus.tec_ComM_FRCSplyUDcHiDTC_Bus
            REC_RTE_R_ComM_FRCSplyUDcLoDTC_Bus_tec_ComM_FRCSplyUDcLoDTC_Bus: accessed-variable=RTE_R_ComM_FRCSplyUDcLoDTC_Bus.tec_ComM_FRCSplyUDcLoDTC_Bus
            REC_RTE_R_LvMgmt_BSBattChrgIDcHiDTC_Bus_tec_LvMgmt_BSBattChrgIDcHiDTC_Bus: accessed-variable=RTE_R_LvMgmt_BSBattChrgIDcHiDTC_Bus.tec_LvMgmt_BSBattChrgIDcHiDTC_Bus
            REC_RTE_R_LvMgmt_BSBattSOCLoDTC_Bus_tec_LvMgmt_BSBattSOCLoDTC_Bus: accessed-variable=RTE_R_LvMgmt_BSBattSOCLoDTC_Bus.tec_LvMgmt_BSBattSOCLoDTC_Bus
            REC_RTE_R_LvMgmt_BSBattTempHiDTC_Bus_tec_LvMgmt_BSBattTempHiDTC_Bus: accessed-variable=RTE_R_LvMgmt_BSBattTempHiDTC_Bus.tec_LvMgmt_BSBattTempHiDTC_Bus
            REC_RTE_R_LvMgmt_BSBattTempLoDTC_Bus_tec_LvMgmt_BSBattTempLoDTC_Bus: accessed-variable=RTE_R_LvMgmt_BSBattTempLoDTC_Bus.tec_LvMgmt_BSBattTempLoDTC_Bus
            REC_RTE_R_LvMgmt_BSRespErrDTC_Bus_tec_LvMgmt_BSRespErrDTC_Bus: accessed-variable=RTE_R_LvMgmt_BSRespErrDTC_Bus.tec_LvMgmt_BSRespErrDTC_Bus
        data-send-points:
          10 x access:
            SEND_QCF_RecoveryReaction_State: accessed-variable=QCF_RecoveryReaction.State
            SEND_ComCtrl_ComState: accessed-variable=ComCtrl.ComState
            SEND_QCF_SafetyReaction_State: accessed-variable=QCF_SafetyReaction.State
            SEND_BSW_FuSaHWErrorStatus_HWErrorStatus: accessed-variable=BSW_FuSaHWErrorStatus.HWErrorStatus
            SEND_BSW_NVMFailErrorStatus_NVMFailErrorStatus: accessed-variable=BSW_NVMFailErrorStatus.NVMFailErrorStatus
            SEND_CHCAN_BusoffStatus_BusoffStatus: accessed-variable=CHCAN_BusoffStatus.BusoffStatus
            SEND_DCCAN_BusoffStatus_BusoffStatus: accessed-variable=DCCAN_BusoffStatus.BusoffStatus
            SEND_PTCAN_BusoffStatus_BusoffStatus: accessed-variable=PTCAN_BusoffStatus.BusoffStatus
            SEND_UDS_PwrCutRequest_PwrCutRequest: accessed-variable=UDS_PwrCutRequest.PwrCutRequest
            SEND_VCU_DTC_Num_SG_VCU_DiagInfor_SigGroup: accessed-variable=VCU_DTC_Num.SG_VCU_DiagInfor_SigGroup
        2378 x sync call:
          SC_DiagHandle_SetEventSts: operation=DiagHandle.SetEventSts
          SC_Event_DTC_0x110012_GetDTCOfEvent: operation=Event_DTC_0x110012.GetDTCOfEvent
          SC_Event_DTC_0x110012_GetEventExtendedDataRecordEx: operation=Event_DTC_0x110012.GetEventExtendedDataRecordEx
          SC_Event_DTC_0x110012_GetEventFailed: operation=Event_DTC_0x110012.GetEventFailed
          SC_Event_DTC_0x110012_GetEventFreezeFrameDataEx: operation=Event_DTC_0x110012.GetEventFreezeFrameDataEx
          SC_Event_DTC_0x110012_GetEventStatus: operation=Event_DTC_0x110012.GetEventStatus
          SC_Event_DTC_0x110012_GetEventTested: operation=Event_DTC_0x110012.GetEventTested
          SC_Event_DTC_0x110012_GetEventUdsStatus: operation=Event_DTC_0x110012.GetEventUdsStatus
          SC_Event_DTC_0x110012_GetFaultDetectionCounter: operation=Event_DTC_0x110012.GetFaultDetectionCounter
          SC_Event_DTC_0x110012_ResetEventDebounceStatus: operation=Event_DTC_0x110012.ResetEventDebounceStatus
          SC_Event_DTC_0x110012_ResetEventStatus: operation=Event_DTC_0x110012.ResetEventStatus
          SC_Event_DTC_0x110012_SetEventStatus: operation=Event_DTC_0x110012.SetEventStatus
          SC_Event_DTC_0x110112_GetDTCOfEvent: operation=Event_DTC_0x110112.GetDTCOfEvent
          SC_Event_DTC_0x110112_GetEventExtendedDataRecordEx: operation=Event_DTC_0x110112.GetEventExtendedDataRecordEx
          SC_Event_DTC_0x110112_GetEventFailed: operation=Event_DTC_0x110112.GetEventFailed
          SC_Event_DTC_0x110112_GetEventFreezeFrameDataEx: operation=Event_DTC_0x110112.GetEventFreezeFrameDataEx
          SC_Event_DTC_0x110112_GetEventStatus: operation=Event_DTC_0x110112.GetEventStatus
          SC_Event_DTC_0x110112_GetEventTested: operation=Event_DTC_0x110112.GetEventTested
          SC_Event_DTC_0x110112_GetEventUdsStatus: operation=Event_DTC_0x110112.GetEventUdsStatus
          SC_Event_DTC_0x110112_GetFaultDetectionCounter: operation=Event_DTC_0x110112.GetFaultDetectionCounter
          SC_Event_DTC_0x110112_ResetEventDebounceStatus: operation=Event_DTC_0x110112.ResetEventDebounceStatus
          SC_Event_DTC_0x110112_ResetEventStatus: operation=Event_DTC_0x110112.ResetEventStatus
          SC_Event_DTC_0x110112_SetEventStatus: operation=Event_DTC_0x110112.SetEventStatus
          SC_Event_DTC_0x110211_GetDTCOfEvent: operation=Event_DTC_0x110211.GetDTCOfEvent
          SC_Event_DTC_0x110211_GetEventExtendedDataRecordEx: operation=Event_DTC_0x110211.GetEventExtendedDataRecordEx
          SC_Event_DTC_0x110211_GetEventFailed: operation=Event_DTC_0x110211.GetEventFailed
          SC_Event_DTC_0x110211_GetEventFreezeFrameDataEx: operation=Event_DTC_0x110211.GetEventFreezeFrameDataEx
          SC_Event_DTC_0x110211_GetEventStatus: operation=Event_DTC_0x110211.GetEventStatus
          SC_Event_DTC_0x110211_GetEventTested: operation=Event_DTC_0x110211.GetEventTested
          SC_Event_DTC_0x110211_GetEventUdsStatus: operation=Event_DTC_0x110211.GetEventUdsStatus
          SC_Event_DTC_0x110211_GetFaultDetectionCounter: operation=Event_DTC_0x110211.GetFaultDetectionCounter
          SC_Event_DTC_0x110211_ResetEventDebounceStatus: operation=Event_DTC_0x110211.ResetEventDebounceStatus
          SC_Event_DTC_0x110211_ResetEventStatus: operation=Event_DTC_0x110211.ResetEventStatus
          SC_Event_DTC_0x110211_SetEventStatus: operation=Event_DTC_0x110211.SetEventStatus
          SC_Event_DTC_0x110311_GetDTCOfEvent: operation=Event_DTC_0x110311.GetDTCOfEvent
          SC_Event_DTC_0x110311_GetEventExtendedDataRecordEx: operation=Event_DTC_0x110311.GetEventExtendedDataRecordEx
          SC_Event_DTC_0x110311_GetEventFailed: operation=Event_DTC_0x110311.GetEventFailed
          SC_Event_DTC_0x110311_GetEventFreezeFrameDataEx: operation=Event_DTC_0x110311.GetEventFreezeFrameDataEx
          SC_Event_DTC_0x110311_GetEventStatus: operation=Event_DTC_0x110311.GetEventStatus
          SC_Event_DTC_0x110311_GetEventTested: operation=Event_DTC_0x110311.GetEventTested
          SC_Event_DTC_0x110311_GetEventUdsStatus: operation=Event_DTC_0x110311.GetEventUdsStatus
          SC_Event_DTC_0x110311_GetFaultDetectionCounter: operation=Event_DTC_0x110311.GetFaultDetectionCounter
          SC_Event_DTC_0x110311_ResetEventDebounceStatus: operation=Event_DTC_0x110311.ResetEventDebounceStatus
          SC_Event_DTC_0x110311_ResetEventStatus: operation=Event_DTC_0x110311.ResetEventStatus
          SC_Event_DTC_0x110311_SetEventStatus: operation=Event_DTC_0x110311.SetEventStatus
          SC_Event_DTC_0x111152_GetDTCOfEvent: operation=Event_DTC_0x111152.GetDTCOfEvent
          SC_Event_DTC_0x111152_GetEventExtendedDataRecordEx: operation=Event_DTC_0x111152.GetEventExtendedDataRecordEx
          SC_Event_DTC_0x111152_GetEventFailed: operation=Event_DTC_0x111152.GetEventFailed
          SC_Event_DTC_0x111152_GetEventFreezeFrameDataEx: operation=Event_DTC_0x111152.GetEventFreezeFrameDataEx
          SC_Event_DTC_0x111152_GetEventStatus: operation=Event_DTC_0x111152.GetEventStatus
          SC_Event_DTC_0x111152_GetEventTested: operation=Event_DTC_0x111152.GetEventTested
          SC_Event_DTC_0x111152_GetEventUdsStatus: operation=Event_DTC_0x111152.GetEventUdsStatus
          SC_Event_DTC_0x111152_GetFaultDetectionCounter: operation=Event_DTC_0x111152.GetFaultDetectionCounter
          SC_Event_DTC_0x111152_ResetEventDebounceStatus: operation=Event_DTC_0x111152.ResetEventDebounceStatus
          SC_Event_DTC_0x111152_ResetEventStatus: operation=Event_DTC_0x111152.ResetEventStatus
          SC_Event_DTC_0x111152_SetEventStatus: operation=Event_DTC_0x111152.SetEventStatus
          SC_Event_DTC_0x111252_GetDTCOfEvent: operation=Event_DTC_0x111252.GetDTCOfEvent
          SC_Event_DTC_0x111252_GetEventExtendedDataRecordEx: operation=Event_DTC_0x111252.GetEventExtendedDataRecordEx
          SC_Event_DTC_0x111252_GetEventFailed: operation=Event_DTC_0x111252.GetEventFailed
          SC_Event_DTC_0x111252_GetEventFreezeFrameDataEx: operation=Event_DTC_0x111252.GetEventFreezeFrameDataEx
          SC_Event_DTC_0x111252_GetEventStatus: operation=Event_DTC_0x111252.GetEventStatus
          SC_Event_DTC_0x111252_GetEventTested: operation=Event_DTC_0x111252.GetEventTested
          SC_Event_DTC_0x111252_GetEventUdsStatus: operation=Event_DTC_0x111252.GetEventUdsStatus
          SC_Event_DTC_0x111252_GetFaultDetectionCounter: operation=Event_DTC_0x111252.GetFaultDetectionCounter
          SC_Event_DTC_0x111252_ResetEventDebounceStatus: operation=Event_DTC_0x111252.ResetEventDebounceStatus
          SC_Event_DTC_0x111252_ResetEventStatus: operation=Event_DTC_0x111252.ResetEventStatus
          SC_Event_DTC_0x111252_SetEventStatus: operation=Event_DTC_0x111252.SetEventStatus
          SC_Event_DTC_0x111352_GetDTCOfEvent: operation=Event_DTC_0x111352.GetDTCOfEvent
          SC_Event_DTC_0x111352_GetEventExtendedDataRecordEx: operation=Event_DTC_0x111352.GetEventExtendedDataRecordEx
          SC_Event_DTC_0x111352_GetEventFailed: operation=Event_DTC_0x111352.GetEventFailed
          SC_Event_DTC_0x111352_GetEventFreezeFrameDataEx: operation=Event_DTC_0x111352.GetEventFreezeFrameDataEx
          SC_Event_DTC_0x111352_GetEventStatus: operation=Event_DTC_0x111352.GetEventStatus
          SC_Event_DTC_0x111352_GetEventTested: operation=Event_DTC_0x111352.GetEventTested
          SC_Event_DTC_0x111352_GetEventUdsStatus: operation=Event_DTC_0x111352.GetEventUdsStatus
          SC_Event_DTC_0x111352_GetFaultDetectionCounter: operation=Event_DTC_0x111352.GetFaultDetectionCounter
          SC_Event_DTC_0x111352_ResetEventDebounceStatus: operation=Event_DTC_0x111352.ResetEventDebounceStatus
          SC_Event_DTC_0x111352_ResetEventStatus: operation=Event_DTC_0x111352.ResetEventStatus
          SC_Event_DTC_0x111352_SetEventStatus: operation=Event_DTC_0x111352.SetEventStatus
          SC_Event_DTC_0x111e71_GetDTCOfEvent: operation=Event_DTC_0x111e71.GetDTCOfEvent
          SC_Event_DTC_0x111e71_GetEventExtendedDataRecordEx: operation=Event_DTC_0x111e71.GetEventExtendedDataRecordEx
          SC_Event_DTC_0x111e71_GetEventFailed: operation=Event_DTC_0x111e71.GetEventFailed
          SC_Event_DTC_0x111e71_GetEventFreezeFrameDataEx: operation=Event_DTC_0x111e71.GetEventFreezeFrameDataEx
          SC_Event_DTC_0x111e71_GetEventStatus: operation=Event_DTC_0x111e71.GetEventStatus
          SC_Event_DTC_0x111e71_GetEventTested: operation=Event_DTC_0x111e71.GetEventTested
          SC_Event_DTC_0x111e71_GetEventUdsStatus: operation=Event_DTC_0x111e71.GetEventUdsStatus
          SC_Event_DTC_0x111e71_GetFaultDetectionCounter: operation=Event_DTC_0x111e71.GetFaultDetectionCounter
          SC_Event_DTC_0x111e71_ResetEventDebounceStatus: operation=Event_DTC_0x111e71.ResetEventDebounceStatus
          SC_Event_DTC_0x111e71_ResetEventStatus: operation=Event_DTC_0x111e71.ResetEventStatus
          SC_Event_DTC_0x111e71_SetEventStatus: operation=Event_DTC_0x111e71.SetEventStatus
          SC_Event_DTC_0x111f16_GetDTCOfEvent: operation=Event_DTC_0x111f16.GetDTCOfEvent
          SC_Event_DTC_0x111f16_GetEventExtendedDataRecordEx: operation=Event_DTC_0x111f16.GetEventExtendedDataRecordEx
          SC_Event_DTC_0x111f16_GetEventFailed: operation=Event_DTC_0x111f16.GetEventFailed
          SC_Event_DTC_0x111f16_GetEventFreezeFrameDataEx: operation=Event_DTC_0x111f16.GetEventFreezeFrameDataEx
          SC_Event_DTC_0x111f16_GetEventStatus: operation=Event_DTC_0x111f16.GetEventStatus
          SC_Event_DTC_0x111f16_GetEventTested: operation=Event_DTC_0x111f16.GetEventTested
          SC_Event_DTC_0x111f16_GetEventUdsStatus: operation=Event_DTC_0x111f16.GetEventUdsStatus
          SC_Event_DTC_0x111f16_GetFaultDetectionCounter: operation=Event_DTC_0x111f16.GetFaultDetectionCounter
          SC_Event_DTC_0x111f16_ResetEventDebounceStatus: operation=Event_DTC_0x111f16.ResetEventDebounceStatus
          SC_Event_DTC_0x111f16_ResetEventStatus: operation=Event_DTC_0x111f16.ResetEventStatus
          SC_Event_DTC_0x111f16_SetEventStatus: operation=Event_DTC_0x111f16.SetEventStatus
          SC_Event_DTC_0x11281e_GetDTCOfEvent: operation=Event_DTC_0x11281e.GetDTCOfEvent
          SC_Event_DTC_0x11281e_GetEventExtendedDataRecordEx: operation=Event_DTC_0x11281e.GetEventExtendedDataRecordEx
          SC_Event_DTC_0x11281e_GetEventFailed: operation=Event_DTC_0x11281e.GetEventFailed
          SC_Event_DTC_0x11281e_GetEventFreezeFrameDataEx: operation=Event_DTC_0x11281e.GetEventFreezeFrameDataEx
          SC_Event_DTC_0x11281e_GetEventStatus: operation=Event_DTC_0x11281e.GetEventStatus
          SC_Event_DTC_0x11281e_GetEventTested: operation=Event_DTC_0x11281e.GetEventTested
          SC_Event_DTC_0x11281e_GetEventUdsStatus: operation=Event_DTC_0x11281e.GetEventUdsStatus
          SC_Event_DTC_0x11281e_GetFaultDetectionCounter: operation=Event_DTC_0x11281e.GetFaultDetectionCounter
          SC_Event_DTC_0x11281e_ResetEventDebounceStatus: operation=Event_DTC_0x11281e.ResetEventDebounceStatus
          SC_Event_DTC_0x11281e_ResetEventStatus: operation=Event_DTC_0x11281e.ResetEventStatus
          SC_Event_DTC_0x11281e_SetEventStatus: operation=Event_DTC_0x11281e.SetEventStatus
          SC_Event_DTC_0x11291c_GetDTCOfEvent: operation=Event_DTC_0x11291c.GetDTCOfEvent
          SC_Event_DTC_0x11291c_GetEventExtendedDataRecordEx: operation=Event_DTC_0x11291c.GetEventExtendedDataRecordEx
          SC_Event_DTC_0x11291c_GetEventFailed: operation=Event_DTC_0x11291c.GetEventFailed
          SC_Event_DTC_0x11291c_GetEventFreezeFrameDataEx: operation=Event_DTC_0x11291c.GetEventFreezeFrameDataEx
          SC_Event_DTC_0x11291c_GetEventStatus: operation=Event_DTC_0x11291c.GetEventStatus
          SC_Event_DTC_0x11291c_GetEventTested: operation=Event_DTC_0x11291c.GetEventTested
          SC_Event_DTC_0x11291c_GetEventUdsStatus: operation=Event_DTC_0x11291c.GetEventUdsStatus
          SC_Event_DTC_0x11291c_GetFaultDetectionCounter: operation=Event_DTC_0x11291c.GetFaultDetectionCounter
          SC_Event_DTC_0x11291c_ResetEventDebounceStatus: operation=Event_DTC_0x11291c.ResetEventDebounceStatus
          SC_Event_DTC_0x11291c_ResetEventStatus: operation=Event_DTC_0x11291c.ResetEventStatus
          SC_Event_DTC_0x11291c_SetEventStatus: operation=Event_DTC_0x11291c.SetEventStatus
          SC_Event_DTC_0x113197_GetDTCOfEvent: operation=Event_DTC_0x113197.GetDTCOfEvent
          SC_Event_DTC_0x113197_GetEventExtendedDataRecordEx: operation=Event_DTC_0x113197.GetEventExtendedDataRecordEx
          SC_Event_DTC_0x113197_GetEventFailed: operation=Event_DTC_0x113197.GetEventFailed
          SC_Event_DTC_0x113197_GetEventFreezeFrameDataEx: operation=Event_DTC_0x113197.GetEventFreezeFrameDataEx
          SC_Event_DTC_0x113197_GetEventStatus: operation=Event_DTC_0x113197.GetEventStatus
          SC_Event_DTC_0x113197_GetEventTested: operation=Event_DTC_0x113197.GetEventTested
          SC_Event_DTC_0x113197_GetEventUdsStatus: operation=Event_DTC_0x113197.GetEventUdsStatus
          SC_Event_DTC_0x113197_GetFaultDetectionCounter: operation=Event_DTC_0x113197.GetFaultDetectionCounter
          SC_Event_DTC_0x113197_ResetEventDebounceStatus: operation=Event_DTC_0x113197.ResetEventDebounceStatus
          SC_Event_DTC_0x113197_ResetEventStatus: operation=Event_DTC_0x113197.ResetEventStatus
          SC_Event_DTC_0x113197_SetEventStatus: operation=Event_DTC_0x113197.SetEventStatus
          SC_Event_DTC_0x113297_GetDTCOfEvent: operation=Event_DTC_0x113297.GetDTCOfEvent
          SC_Event_DTC_0x113297_GetEventExtendedDataRecordEx: operation=Event_DTC_0x113297.GetEventExtendedDataRecordEx
          SC_Event_DTC_0x113297_GetEventFailed: operation=Event_DTC_0x113297.GetEventFailed
          SC_Event_DTC_0x113297_GetEventFreezeFrameDataEx: operation=Event_DTC_0x113297.GetEventFreezeFrameDataEx
          SC_Event_DTC_0x113297_GetEventStatus: operation=Event_DTC_0x113297.GetEventStatus
          SC_Event_DTC_0x113297_GetEventTested: operation=Event_DTC_0x113297.GetEventTested
          SC_Event_DTC_0x113297_GetEventUdsStatus: operation=Event_DTC_0x113297.GetEventUdsStatus
          SC_Event_DTC_0x113297_GetFaultDetectionCounter: operation=Event_DTC_0x113297.GetFaultDetectionCounter
          SC_Event_DTC_0x113297_ResetEventDebounceStatus: operation=Event_DTC_0x113297.ResetEventDebounceStatus
          SC_Event_DTC_0x113297_ResetEventStatus: operation=Event_DTC_0x113297.ResetEventStatus
          SC_Event_DTC_0x113297_SetEventStatus: operation=Event_DTC_0x113297.SetEventStatus
          SC_Event_DTC_0x113397_GetDTCOfEvent: operation=Event_DTC_0x113397.GetDTCOfEvent
          SC_Event_DTC_0x113397_GetEventExtendedDataRecordEx: operation=Event_DTC_0x113397.GetEventExtendedDataRecordEx
          SC_Event_DTC_0x113397_GetEventFailed: operation=Event_DTC_0x113397.GetEventFailed
          SC_Event_DTC_0x113397_GetEventFreezeFrameDataEx: operation=Event_DTC_0x113397.GetEventFreezeFrameDataEx
          SC_Event_DTC_0x113397_GetEventStatus: operation=Event_DTC_0x113397.GetEventStatus
          SC_Event_DTC_0x113397_GetEventTested: operation=Event_DTC_0x113397.GetEventTested
          SC_Event_DTC_0x113397_GetEventUdsStatus: operation=Event_DTC_0x113397.GetEventUdsStatus
          SC_Event_DTC_0x113397_GetFaultDetectionCounter: operation=Event_DTC_0x113397.GetFaultDetectionCounter
          SC_Event_DTC_0x113397_ResetEventDebounceStatus: operation=Event_DTC_0x113397.ResetEventDebounceStatus
          SC_Event_DTC_0x113397_ResetEventStatus: operation=Event_DTC_0x113397.ResetEventStatus
          SC_Event_DTC_0x113397_SetEventStatus: operation=Event_DTC_0x113397.SetEventStatus
          SC_Event_DTC_0x113497_GetDTCOfEvent: operation=Event_DTC_0x113497.GetDTCOfEvent
          SC_Event_DTC_0x113497_GetEventExtendedDataRecordEx: operation=Event_DTC_0x113497.GetEventExtendedDataRecordEx
          SC_Event_DTC_0x113497_GetEventFailed: operation=Event_DTC_0x113497.GetEventFailed
          SC_Event_DTC_0x113497_GetEventFreezeFrameDataEx: operation=Event_DTC_0x113497.GetEventFreezeFrameDataEx
          SC_Event_DTC_0x113497_GetEventStatus: operation=Event_DTC_0x113497.GetEventStatus
          SC_Event_DTC_0x113497_GetEventTested: operation=Event_DTC_0x113497.GetEventTested
          SC_Event_DTC_0x113497_GetEventUdsStatus: operation=Event_DTC_0x113497.GetEventUdsStatus
          SC_Event_DTC_0x113497_GetFaultDetectionCounter: operation=Event_DTC_0x113497.GetFaultDetectionCounter
          SC_Event_DTC_0x113497_ResetEventDebounceStatus: operation=Event_DTC_0x113497.ResetEventDebounceStatus
          SC_Event_DTC_0x113497_ResetEventStatus: operation=Event_DTC_0x113497.ResetEventStatus
          SC_Event_DTC_0x113497_SetEventStatus: operation=Event_DTC_0x113497.SetEventStatus
          SC_Event_DTC_0x113597_GetDTCOfEvent: operation=Event_DTC_0x113597.GetDTCOfEvent
          SC_Event_DTC_0x113597_GetEventExtendedDataRecordEx: operation=Event_DTC_0x113597.GetEventExtendedDataRecordEx
          SC_Event_DTC_0x113597_GetEventFailed: operation=Event_DTC_0x113597.GetEventFailed
          SC_Event_DTC_0x113597_GetEventFreezeFrameDataEx: operation=Event_DTC_0x113597.GetEventFreezeFrameDataEx
          SC_Event_DTC_0x113597_GetEventStatus: operation=Event_DTC_0x113597.GetEventStatus
          SC_Event_DTC_0x113597_GetEventTested: operation=Event_DTC_0x113597.GetEventTested
          SC_Event_DTC_0x113597_GetEventUdsStatus: operation=Event_DTC_0x113597.GetEventUdsStatus
          SC_Event_DTC_0x113597_GetFaultDetectionCounter: operation=Event_DTC_0x113597.GetFaultDetectionCounter
          SC_Event_DTC_0x113597_ResetEventDebounceStatus: operation=Event_DTC_0x113597.ResetEventDebounceStatus
          SC_Event_DTC_0x113597_ResetEventStatus: operation=Event_DTC_0x113597.ResetEventStatus
          SC_Event_DTC_0x113597_SetEventStatus: operation=Event_DTC_0x113597.SetEventStatus
          SC_Event_DTC_0x113697_GetDTCOfEvent: operation=Event_DTC_0x113697.GetDTCOfEvent
          SC_Event_DTC_0x113697_GetEventExtendedDataRecordEx: operation=Event_DTC_0x113697.GetEventExtendedDataRecordEx
          SC_Event_DTC_0x113697_GetEventFailed: operation=Event_DTC_0x113697.GetEventFailed
          SC_Event_DTC_0x113697_GetEventFreezeFrameDataEx: operation=Event_DTC_0x113697.GetEventFreezeFrameDataEx
          SC_Event_DTC_0x113697_GetEventStatus: operation=Event_DTC_0x113697.GetEventStatus
          SC_Event_DTC_0x113697_GetEventTested: operation=Event_DTC_0x113697.GetEventTested
          SC_Event_DTC_0x113697_GetEventUdsStatus: operation=Event_DTC_0x113697.GetEventUdsStatus
          SC_Event_DTC_0x113697_GetFaultDetectionCounter: operation=Event_DTC_0x113697.GetFaultDetectionCounter
          SC_Event_DTC_0x113697_ResetEventDebounceStatus: operation=Event_DTC_0x113697.ResetEventDebounceStatus
          SC_Event_DTC_0x113697_ResetEventStatus: operation=Event_DTC_0x113697.ResetEventStatus
          SC_Event_DTC_0x113697_SetEventStatus: operation=Event_DTC_0x113697.SetEventStatus
          SC_Event_DTC_0x113797_GetDTCOfEvent: operation=Event_DTC_0x113797.GetDTCOfEvent
          SC_Event_DTC_0x113797_GetEventExtendedDataRecordEx: operation=Event_DTC_0x113797.GetEventExtendedDataRecordEx
          SC_Event_DTC_0x113797_GetEventFailed: operation=Event_DTC_0x113797.GetEventFailed
          SC_Event_DTC_0x113797_GetEventFreezeFrameDataEx: operation=Event_DTC_0x113797.GetEventFreezeFrameDataEx
          SC_Event_DTC_0x113797_GetEventStatus: operation=Event_DTC_0x113797.GetEventStatus
          SC_Event_DTC_0x113797_GetEventTested: operation=Event_DTC_0x113797.GetEventTested
          SC_Event_DTC_0x113797_GetEventUdsStatus: operation=Event_DTC_0x113797.GetEventUdsStatus
          SC_Event_DTC_0x113797_GetFaultDetectionCounter: operation=Event_DTC_0x113797.GetFaultDetectionCounter
          SC_Event_DTC_0x113797_ResetEventDebounceStatus: operation=Event_DTC_0x113797.ResetEventDebounceStatus
          SC_Event_DTC_0x113797_ResetEventStatus: operation=Event_DTC_0x113797.ResetEventStatus
          SC_Event_DTC_0x113797_SetEventStatus: operation=Event_DTC_0x113797.SetEventStatus
          SC_Event_DTC_0x113897_GetDTCOfEvent: operation=Event_DTC_0x113897.GetDTCOfEvent
          SC_Event_DTC_0x113897_GetEventExtendedDataRecordEx: operation=Event_DTC_0x113897.GetEventExtendedDataRecordEx
          SC_Event_DTC_0x113897_GetEventFailed: operation=Event_DTC_0x113897.GetEventFailed
          SC_Event_DTC_0x113897_GetEventFreezeFrameDataEx: operation=Event_DTC_0x113897.GetEventFreezeFrameDataEx
          SC_Event_DTC_0x113897_GetEventStatus: operation=Event_DTC_0x113897.GetEventStatus
          SC_Event_DTC_0x113897_GetEventTested: operation=Event_DTC_0x113897.GetEventTested
          SC_Event_DTC_0x113897_GetEventUdsStatus: operation=Event_DTC_0x113897.GetEventUdsStatus
          SC_Event_DTC_0x113897_GetFaultDetectionCounter: operation=Event_DTC_0x113897.GetFaultDetectionCounter
          SC_Event_DTC_0x113897_ResetEventDebounceStatus: operation=Event_DTC_0x113897.ResetEventDebounceStatus
          SC_Event_DTC_0x113897_ResetEventStatus: operation=Event_DTC_0x113897.ResetEventStatus
          SC_Event_DTC_0x113897_SetEventStatus: operation=Event_DTC_0x113897.SetEventStatus
          SC_Event_DTC_0x113997_GetDTCOfEvent: operation=Event_DTC_0x113997.GetDTCOfEvent
          SC_Event_DTC_0x113997_GetEventExtendedDataRecordEx: operation=Event_DTC_0x113997.GetEventExtendedDataRecordEx
          SC_Event_DTC_0x113997_GetEventFailed: operation=Event_DTC_0x113997.GetEventFailed
          SC_Event_DTC_0x113997_GetEventFreezeFrameDataEx: operation=Event_DTC_0x113997.GetEventFreezeFrameDataEx
          SC_Event_DTC_0x113997_GetEventStatus: operation=Event_DTC_0x113997.GetEventStatus
          SC_Event_DTC_0x113997_GetEventTested: operation=Event_DTC_0x113997.GetEventTested
          SC_Event_DTC_0x113997_GetEventUdsStatus: operation=Event_DTC_0x113997.GetEventUdsStatus
          SC_Event_DTC_0x113997_GetFaultDetectionCounter: operation=Event_DTC_0x113997.GetFaultDetectionCounter
          SC_Event_DTC_0x113997_ResetEventDebounceStatus: operation=Event_DTC_0x113997.ResetEventDebounceStatus
          SC_Event_DTC_0x113997_ResetEventStatus: operation=Event_DTC_0x113997.ResetEventStatus
          SC_Event_DTC_0x113997_SetEventStatus: operation=Event_DTC_0x113997.SetEventStatus
          SC_Event_DTC_0x114097_GetDTCOfEvent: operation=Event_DTC_0x114097.GetDTCOfEvent
          SC_Event_DTC_0x114097_GetEventExtendedDataRecordEx: operation=Event_DTC_0x114097.GetEventExtendedDataRecordEx
          SC_Event_DTC_0x114097_GetEventFailed: operation=Event_DTC_0x114097.GetEventFailed
          SC_Event_DTC_0x114097_GetEventFreezeFrameDataEx: operation=Event_DTC_0x114097.GetEventFreezeFrameDataEx
          SC_Event_DTC_0x114097_GetEventStatus: operation=Event_DTC_0x114097.GetEventStatus
          SC_Event_DTC_0x114097_GetEventTested: operation=Event_DTC_0x114097.GetEventTested
          SC_Event_DTC_0x114097_GetEventUdsStatus: operation=Event_DTC_0x114097.GetEventUdsStatus
          SC_Event_DTC_0x114097_GetFaultDetectionCounter: operation=Event_DTC_0x114097.GetFaultDetectionCounter
          SC_Event_DTC_0x114097_ResetEventDebounceStatus: operation=Event_DTC_0x114097.ResetEventDebounceStatus
          SC_Event_DTC_0x114097_ResetEventStatus: operation=Event_DTC_0x114097.ResetEventStatus
          SC_Event_DTC_0x114097_SetEventStatus: operation=Event_DTC_0x114097.SetEventStatus
          SC_Event_DTC_0x114197_GetDTCOfEvent: operation=Event_DTC_0x114197.GetDTCOfEvent
          SC_Event_DTC_0x114197_GetEventExtendedDataRecordEx: operation=Event_DTC_0x114197.GetEventExtendedDataRecordEx
          SC_Event_DTC_0x114197_GetEventFailed: operation=Event_DTC_0x114197.GetEventFailed
          SC_Event_DTC_0x114197_GetEventFreezeFrameDataEx: operation=Event_DTC_0x114197.GetEventFreezeFrameDataEx
          SC_Event_DTC_0x114197_GetEventStatus: operation=Event_DTC_0x114197.GetEventStatus
          SC_Event_DTC_0x114197_GetEventTested: operation=Event_DTC_0x114197.GetEventTested
          SC_Event_DTC_0x114197_GetEventUdsStatus: operation=Event_DTC_0x114197.GetEventUdsStatus
          SC_Event_DTC_0x114197_GetFaultDetectionCounter: operation=Event_DTC_0x114197.GetFaultDetectionCounter
          SC_Event_DTC_0x114197_ResetEventDebounceStatus: operation=Event_DTC_0x114197.ResetEventDebounceStatus
          SC_Event_DTC_0x114197_ResetEventStatus: operation=Event_DTC_0x114197.ResetEventStatus
          SC_Event_DTC_0x114197_SetEventStatus: operation=Event_DTC_0x114197.SetEventStatus
          SC_Event_DTC_0x114297_GetDTCOfEvent: operation=Event_DTC_0x114297.GetDTCOfEvent
          SC_Event_DTC_0x114297_GetEventExtendedDataRecordEx: operation=Event_DTC_0x114297.GetEventExtendedDataRecordEx
          SC_Event_DTC_0x114297_GetEventFailed: operation=Event_DTC_0x114297.GetEventFailed
          SC_Event_DTC_0x114297_GetEventFreezeFrameDataEx: operation=Event_DTC_0x114297.GetEventFreezeFrameDataEx
          SC_Event_DTC_0x114297_GetEventStatus: operation=Event_DTC_0x114297.GetEventStatus
          SC_Event_DTC_0x114297_GetEventTested: operation=Event_DTC_0x114297.GetEventTested
          SC_Event_DTC_0x114297_GetEventUdsStatus: operation=Event_DTC_0x114297.GetEventUdsStatus
          SC_Event_DTC_0x114297_GetFaultDetectionCounter: operation=Event_DTC_0x114297.GetFaultDetectionCounter
          SC_Event_DTC_0x114297_ResetEventDebounceStatus: operation=Event_DTC_0x114297.ResetEventDebounceStatus
          SC_Event_DTC_0x114297_ResetEventStatus: operation=Event_DTC_0x114297.ResetEventStatus
          SC_Event_DTC_0x114297_SetEventStatus: operation=Event_DTC_0x114297.SetEventStatus
          SC_Event_DTC_0x114397_GetDTCOfEvent: operation=Event_DTC_0x114397.GetDTCOfEvent
          SC_Event_DTC_0x114397_GetEventExtendedDataRecordEx: operation=Event_DTC_0x114397.GetEventExtendedDataRecordEx
          SC_Event_DTC_0x114397_GetEventFailed: operation=Event_DTC_0x114397.GetEventFailed
          SC_Event_DTC_0x114397_GetEventFreezeFrameDataEx: operation=Event_DTC_0x114397.GetEventFreezeFrameDataEx
          SC_Event_DTC_0x114397_GetEventStatus: operation=Event_DTC_0x114397.GetEventStatus
          SC_Event_DTC_0x114397_GetEventTested: operation=Event_DTC_0x114397.GetEventTested
          SC_Event_DTC_0x114397_GetEventUdsStatus: operation=Event_DTC_0x114397.GetEventUdsStatus
          SC_Event_DTC_0x114397_GetFaultDetectionCounter: operation=Event_DTC_0x114397.GetFaultDetectionCounter
          SC_Event_DTC_0x114397_ResetEventDebounceStatus: operation=Event_DTC_0x114397.ResetEventDebounceStatus
          SC_Event_DTC_0x114397_ResetEventStatus: operation=Event_DTC_0x114397.ResetEventStatus
          SC_Event_DTC_0x114397_SetEventStatus: operation=Event_DTC_0x114397.SetEventStatus
          SC_Event_DTC_0x114497_GetDTCOfEvent: operation=Event_DTC_0x114497.GetDTCOfEvent
          SC_Event_DTC_0x114497_GetEventExtendedDataRecordEx: operation=Event_DTC_0x114497.GetEventExtendedDataRecordEx
          SC_Event_DTC_0x114497_GetEventFailed: operation=Event_DTC_0x114497.GetEventFailed
          SC_Event_DTC_0x114497_GetEventFreezeFrameDataEx: operation=Event_DTC_0x114497.GetEventFreezeFrameDataEx
          SC_Event_DTC_0x114497_GetEventStatus: operation=Event_DTC_0x114497.GetEventStatus
          SC_Event_DTC_0x114497_GetEventTested: operation=Event_DTC_0x114497.GetEventTested
          SC_Event_DTC_0x114497_GetEventUdsStatus: operation=Event_DTC_0x114497.GetEventUdsStatus
          SC_Event_DTC_0x114497_GetFaultDetectionCounter: operation=Event_DTC_0x114497.GetFaultDetectionCounter
          SC_Event_DTC_0x114497_ResetEventDebounceStatus: operation=Event_DTC_0x114497.ResetEventDebounceStatus
          SC_Event_DTC_0x114497_ResetEventStatus: operation=Event_DTC_0x114497.ResetEventStatus
          SC_Event_DTC_0x114497_SetEventStatus: operation=Event_DTC_0x114497.SetEventStatus
          SC_Event_DTC_0x114571_GetDTCOfEvent: operation=Event_DTC_0x114571.GetDTCOfEvent
          SC_Event_DTC_0x114571_GetEventExtendedDataRecordEx: operation=Event_DTC_0x114571.GetEventExtendedDataRecordEx
          SC_Event_DTC_0x114571_GetEventFailed: operation=Event_DTC_0x114571.GetEventFailed
          SC_Event_DTC_0x114571_GetEventFreezeFrameDataEx: operation=Event_DTC_0x114571.GetEventFreezeFrameDataEx
          SC_Event_DTC_0x114571_GetEventStatus: operation=Event_DTC_0x114571.GetEventStatus
          SC_Event_DTC_0x114571_GetEventTested: operation=Event_DTC_0x114571.GetEventTested
          SC_Event_DTC_0x114571_GetEventUdsStatus: operation=Event_DTC_0x114571.GetEventUdsStatus
          SC_Event_DTC_0x114571_GetFaultDetectionCounter: operation=Event_DTC_0x114571.GetFaultDetectionCounter
          SC_Event_DTC_0x114571_ResetEventDebounceStatus: operation=Event_DTC_0x114571.ResetEventDebounceStatus
          SC_Event_DTC_0x114571_ResetEventStatus: operation=Event_DTC_0x114571.ResetEventStatus
          SC_Event_DTC_0x114571_SetEventStatus: operation=Event_DTC_0x114571.SetEventStatus
          SC_Event_DTC_0x114697_GetDTCOfEvent: operation=Event_DTC_0x114697.GetDTCOfEvent
          SC_Event_DTC_0x114697_GetEventExtendedDataRecordEx: operation=Event_DTC_0x114697.GetEventExtendedDataRecordEx
          SC_Event_DTC_0x114697_GetEventFailed: operation=Event_DTC_0x114697.GetEventFailed
          SC_Event_DTC_0x114697_GetEventFreezeFrameDataEx: operation=Event_DTC_0x114697.GetEventFreezeFrameDataEx
          SC_Event_DTC_0x114697_GetEventStatus: operation=Event_DTC_0x114697.GetEventStatus
          SC_Event_DTC_0x114697_GetEventTested: operation=Event_DTC_0x114697.GetEventTested
          SC_Event_DTC_0x114697_GetEventUdsStatus: operation=Event_DTC_0x114697.GetEventUdsStatus
          SC_Event_DTC_0x114697_GetFaultDetectionCounter: operation=Event_DTC_0x114697.GetFaultDetectionCounter
          SC_Event_DTC_0x114697_ResetEventDebounceStatus: operation=Event_DTC_0x114697.ResetEventDebounceStatus
          SC_Event_DTC_0x114697_ResetEventStatus: operation=Event_DTC_0x114697.ResetEventStatus
          SC_Event_DTC_0x114697_SetEventStatus: operation=Event_DTC_0x114697.SetEventStatus
          SC_Event_DTC_0x114792_GetDTCOfEvent: operation=Event_DTC_0x114792.GetDTCOfEvent
          SC_Event_DTC_0x114792_GetEventExtendedDataRecordEx: operation=Event_DTC_0x114792.GetEventExtendedDataRecordEx
          SC_Event_DTC_0x114792_GetEventFailed: operation=Event_DTC_0x114792.GetEventFailed
          SC_Event_DTC_0x114792_GetEventFreezeFrameDataEx: operation=Event_DTC_0x114792.GetEventFreezeFrameDataEx
          SC_Event_DTC_0x114792_GetEventStatus: operation=Event_DTC_0x114792.GetEventStatus
          SC_Event_DTC_0x114792_GetEventTested: operation=Event_DTC_0x114792.GetEventTested
          SC_Event_DTC_0x114792_GetEventUdsStatus: operation=Event_DTC_0x114792.GetEventUdsStatus
          SC_Event_DTC_0x114792_GetFaultDetectionCounter: operation=Event_DTC_0x114792.GetFaultDetectionCounter
          SC_Event_DTC_0x114792_ResetEventDebounceStatus: operation=Event_DTC_0x114792.ResetEventDebounceStatus
          SC_Event_DTC_0x114792_ResetEventStatus: operation=Event_DTC_0x114792.ResetEventStatus
          SC_Event_DTC_0x114792_SetEventStatus: operation=Event_DTC_0x114792.SetEventStatus
          SC_Event_DTC_0x114892_GetDTCOfEvent: operation=Event_DTC_0x114892.GetDTCOfEvent
          SC_Event_DTC_0x114892_GetEventExtendedDataRecordEx: operation=Event_DTC_0x114892.GetEventExtendedDataRecordEx
          SC_Event_DTC_0x114892_GetEventFailed: operation=Event_DTC_0x114892.GetEventFailed
          SC_Event_DTC_0x114892_GetEventFreezeFrameDataEx: operation=Event_DTC_0x114892.GetEventFreezeFrameDataEx
          SC_Event_DTC_0x114892_GetEventStatus: operation=Event_DTC_0x114892.GetEventStatus
          SC_Event_DTC_0x114892_GetEventTested: operation=Event_DTC_0x114892.GetEventTested
          SC_Event_DTC_0x114892_GetEventUdsStatus: operation=Event_DTC_0x114892.GetEventUdsStatus
          SC_Event_DTC_0x114892_GetFaultDetectionCounter: operation=Event_DTC_0x114892.GetFaultDetectionCounter
          SC_Event_DTC_0x114892_ResetEventDebounceStatus: operation=Event_DTC_0x114892.ResetEventDebounceStatus
          SC_Event_DTC_0x114892_ResetEventStatus: operation=Event_DTC_0x114892.ResetEventStatus
          SC_Event_DTC_0x114892_SetEventStatus: operation=Event_DTC_0x114892.SetEventStatus
          SC_Event_DTC_0x114992_GetDTCOfEvent: operation=Event_DTC_0x114992.GetDTCOfEvent
          SC_Event_DTC_0x114992_GetEventExtendedDataRecordEx: operation=Event_DTC_0x114992.GetEventExtendedDataRecordEx
          SC_Event_DTC_0x114992_GetEventFailed: operation=Event_DTC_0x114992.GetEventFailed
          SC_Event_DTC_0x114992_GetEventFreezeFrameDataEx: operation=Event_DTC_0x114992.GetEventFreezeFrameDataEx
          SC_Event_DTC_0x114992_GetEventStatus: operation=Event_DTC_0x114992.GetEventStatus
          SC_Event_DTC_0x114992_GetEventTested: operation=Event_DTC_0x114992.GetEventTested
          SC_Event_DTC_0x114992_GetEventUdsStatus: operation=Event_DTC_0x114992.GetEventUdsStatus
          SC_Event_DTC_0x114992_GetFaultDetectionCounter: operation=Event_DTC_0x114992.GetFaultDetectionCounter
          SC_Event_DTC_0x114992_ResetEventDebounceStatus: operation=Event_DTC_0x114992.ResetEventDebounceStatus
          SC_Event_DTC_0x114992_ResetEventStatus: operation=Event_DTC_0x114992.ResetEventStatus
          SC_Event_DTC_0x114992_SetEventStatus: operation=Event_DTC_0x114992.SetEventStatus
          SC_Event_DTC_0x115092_GetDTCOfEvent: operation=Event_DTC_0x115092.GetDTCOfEvent
          SC_Event_DTC_0x115092_GetEventExtendedDataRecordEx: operation=Event_DTC_0x115092.GetEventExtendedDataRecordEx
          SC_Event_DTC_0x115092_GetEventFailed: operation=Event_DTC_0x115092.GetEventFailed
          SC_Event_DTC_0x115092_GetEventFreezeFrameDataEx: operation=Event_DTC_0x115092.GetEventFreezeFrameDataEx
          SC_Event_DTC_0x115092_GetEventStatus: operation=Event_DTC_0x115092.GetEventStatus
          SC_Event_DTC_0x115092_GetEventTested: operation=Event_DTC_0x115092.GetEventTested
          SC_Event_DTC_0x115092_GetEventUdsStatus: operation=Event_DTC_0x115092.GetEventUdsStatus
          SC_Event_DTC_0x115092_GetFaultDetectionCounter: operation=Event_DTC_0x115092.GetFaultDetectionCounter
          SC_Event_DTC_0x115092_ResetEventDebounceStatus: operation=Event_DTC_0x115092.ResetEventDebounceStatus
          SC_Event_DTC_0x115092_ResetEventStatus: operation=Event_DTC_0x115092.ResetEventStatus
          SC_Event_DTC_0x115092_SetEventStatus: operation=Event_DTC_0x115092.SetEventStatus
          SC_Event_DTC_0x115192_GetDTCOfEvent: operation=Event_DTC_0x115192.GetDTCOfEvent
          SC_Event_DTC_0x115192_GetEventExtendedDataRecordEx: operation=Event_DTC_0x115192.GetEventExtendedDataRecordEx
          SC_Event_DTC_0x115192_GetEventFailed: operation=Event_DTC_0x115192.GetEventFailed
          SC_Event_DTC_0x115192_GetEventFreezeFrameDataEx: operation=Event_DTC_0x115192.GetEventFreezeFrameDataEx
          SC_Event_DTC_0x115192_GetEventStatus: operation=Event_DTC_0x115192.GetEventStatus
          SC_Event_DTC_0x115192_GetEventTested: operation=Event_DTC_0x115192.GetEventTested
          SC_Event_DTC_0x115192_GetEventUdsStatus: operation=Event_DTC_0x115192.GetEventUdsStatus
          SC_Event_DTC_0x115192_GetFaultDetectionCounter: operation=Event_DTC_0x115192.GetFaultDetectionCounter
          SC_Event_DTC_0x115192_ResetEventDebounceStatus: operation=Event_DTC_0x115192.ResetEventDebounceStatus
          SC_Event_DTC_0x115192_ResetEventStatus: operation=Event_DTC_0x115192.ResetEventStatus
          SC_Event_DTC_0x115192_SetEventStatus: operation=Event_DTC_0x115192.SetEventStatus
          SC_Event_DTC_0x115292_GetDTCOfEvent: operation=Event_DTC_0x115292.GetDTCOfEvent
          SC_Event_DTC_0x115292_GetEventExtendedDataRecordEx: operation=Event_DTC_0x115292.GetEventExtendedDataRecordEx
          SC_Event_DTC_0x115292_GetEventFailed: operation=Event_DTC_0x115292.GetEventFailed
          SC_Event_DTC_0x115292_GetEventFreezeFrameDataEx: operation=Event_DTC_0x115292.GetEventFreezeFrameDataEx
          SC_Event_DTC_0x115292_GetEventStatus: operation=Event_DTC_0x115292.GetEventStatus
          SC_Event_DTC_0x115292_GetEventTested: operation=Event_DTC_0x115292.GetEventTested
          SC_Event_DTC_0x115292_GetEventUdsStatus: operation=Event_DTC_0x115292.GetEventUdsStatus
          SC_Event_DTC_0x115292_GetFaultDetectionCounter: operation=Event_DTC_0x115292.GetFaultDetectionCounter
          SC_Event_DTC_0x115292_ResetEventDebounceStatus: operation=Event_DTC_0x115292.ResetEventDebounceStatus
          SC_Event_DTC_0x115292_ResetEventStatus: operation=Event_DTC_0x115292.ResetEventStatus
          SC_Event_DTC_0x115292_SetEventStatus: operation=Event_DTC_0x115292.SetEventStatus
          SC_Event_DTC_0x115392_GetDTCOfEvent: operation=Event_DTC_0x115392.GetDTCOfEvent
          SC_Event_DTC_0x115392_GetEventExtendedDataRecordEx: operation=Event_DTC_0x115392.GetEventExtendedDataRecordEx
          SC_Event_DTC_0x115392_GetEventFailed: operation=Event_DTC_0x115392.GetEventFailed
          SC_Event_DTC_0x115392_GetEventFreezeFrameDataEx: operation=Event_DTC_0x115392.GetEventFreezeFrameDataEx
          SC_Event_DTC_0x115392_GetEventStatus: operation=Event_DTC_0x115392.GetEventStatus
          SC_Event_DTC_0x115392_GetEventTested: operation=Event_DTC_0x115392.GetEventTested
          SC_Event_DTC_0x115392_GetEventUdsStatus: operation=Event_DTC_0x115392.GetEventUdsStatus
          SC_Event_DTC_0x115392_GetFaultDetectionCounter: operation=Event_DTC_0x115392.GetFaultDetectionCounter
          SC_Event_DTC_0x115392_ResetEventDebounceStatus: operation=Event_DTC_0x115392.ResetEventDebounceStatus
          SC_Event_DTC_0x115392_ResetEventStatus: operation=Event_DTC_0x115392.ResetEventStatus
          SC_Event_DTC_0x115392_SetEventStatus: operation=Event_DTC_0x115392.SetEventStatus
          SC_Event_DTC_0x115492_GetDTCOfEvent: operation=Event_DTC_0x115492.GetDTCOfEvent
          SC_Event_DTC_0x115492_GetEventExtendedDataRecordEx: operation=Event_DTC_0x115492.GetEventExtendedDataRecordEx
          SC_Event_DTC_0x115492_GetEventFailed: operation=Event_DTC_0x115492.GetEventFailed
          SC_Event_DTC_0x115492_GetEventFreezeFrameDataEx: operation=Event_DTC_0x115492.GetEventFreezeFrameDataEx
          SC_Event_DTC_0x115492_GetEventStatus: operation=Event_DTC_0x115492.GetEventStatus
          SC_Event_DTC_0x115492_GetEventTested: operation=Event_DTC_0x115492.GetEventTested
          SC_Event_DTC_0x115492_GetEventUdsStatus: operation=Event_DTC_0x115492.GetEventUdsStatus
          SC_Event_DTC_0x115492_GetFaultDetectionCounter: operation=Event_DTC_0x115492.GetFaultDetectionCounter
          SC_Event_DTC_0x115492_ResetEventDebounceStatus: operation=Event_DTC_0x115492.ResetEventDebounceStatus
          SC_Event_DTC_0x115492_ResetEventStatus: operation=Event_DTC_0x115492.ResetEventStatus
          SC_Event_DTC_0x115492_SetEventStatus: operation=Event_DTC_0x115492.SetEventStatus
          SC_Event_DTC_0x115592_GetDTCOfEvent: operation=Event_DTC_0x115592.GetDTCOfEvent
          SC_Event_DTC_0x115592_GetEventExtendedDataRecordEx: operation=Event_DTC_0x115592.GetEventExtendedDataRecordEx
          SC_Event_DTC_0x115592_GetEventFailed: operation=Event_DTC_0x115592.GetEventFailed
          SC_Event_DTC_0x115592_GetEventFreezeFrameDataEx: operation=Event_DTC_0x115592.GetEventFreezeFrameDataEx
          SC_Event_DTC_0x115592_GetEventStatus: operation=Event_DTC_0x115592.GetEventStatus
          SC_Event_DTC_0x115592_GetEventTested: operation=Event_DTC_0x115592.GetEventTested
          SC_Event_DTC_0x115592_GetEventUdsStatus: operation=Event_DTC_0x115592.GetEventUdsStatus
          SC_Event_DTC_0x115592_GetFaultDetectionCounter: operation=Event_DTC_0x115592.GetFaultDetectionCounter
          SC_Event_DTC_0x115592_ResetEventDebounceStatus: operation=Event_DTC_0x115592.ResetEventDebounceStatus
          SC_Event_DTC_0x115592_ResetEventStatus: operation=Event_DTC_0x115592.ResetEventStatus
          SC_Event_DTC_0x115592_SetEventStatus: operation=Event_DTC_0x115592.SetEventStatus
          SC_Event_DTC_0x115692_GetDTCOfEvent: operation=Event_DTC_0x115692.GetDTCOfEvent
          SC_Event_DTC_0x115692_GetEventExtendedDataRecordEx: operation=Event_DTC_0x115692.GetEventExtendedDataRecordEx
          SC_Event_DTC_0x115692_GetEventFailed: operation=Event_DTC_0x115692.GetEventFailed
          SC_Event_DTC_0x115692_GetEventFreezeFrameDataEx: operation=Event_DTC_0x115692.GetEventFreezeFrameDataEx
          SC_Event_DTC_0x115692_GetEventStatus: operation=Event_DTC_0x115692.GetEventStatus
          SC_Event_DTC_0x115692_GetEventTested: operation=Event_DTC_0x115692.GetEventTested
          SC_Event_DTC_0x115692_GetEventUdsStatus: operation=Event_DTC_0x115692.GetEventUdsStatus
          SC_Event_DTC_0x115692_GetFaultDetectionCounter: operation=Event_DTC_0x115692.GetFaultDetectionCounter
          SC_Event_DTC_0x115692_ResetEventDebounceStatus: operation=Event_DTC_0x115692.ResetEventDebounceStatus
          SC_Event_DTC_0x115692_ResetEventStatus: operation=Event_DTC_0x115692.ResetEventStatus
          SC_Event_DTC_0x115692_SetEventStatus: operation=Event_DTC_0x115692.SetEventStatus
          SC_Event_DTC_0x11571e_GetDTCOfEvent: operation=Event_DTC_0x11571e.GetDTCOfEvent
          SC_Event_DTC_0x11571e_GetEventExtendedDataRecordEx: operation=Event_DTC_0x11571e.GetEventExtendedDataRecordEx
          SC_Event_DTC_0x11571e_GetEventFailed: operation=Event_DTC_0x11571e.GetEventFailed
          SC_Event_DTC_0x11571e_GetEventFreezeFrameDataEx: operation=Event_DTC_0x11571e.GetEventFreezeFrameDataEx
          SC_Event_DTC_0x11571e_GetEventStatus: operation=Event_DTC_0x11571e.GetEventStatus
          SC_Event_DTC_0x11571e_GetEventTested: operation=Event_DTC_0x11571e.GetEventTested
          SC_Event_DTC_0x11571e_GetEventUdsStatus: operation=Event_DTC_0x11571e.GetEventUdsStatus
          SC_Event_DTC_0x11571e_GetFaultDetectionCounter: operation=Event_DTC_0x11571e.GetFaultDetectionCounter
          SC_Event_DTC_0x11571e_ResetEventDebounceStatus: operation=Event_DTC_0x11571e.ResetEventDebounceStatus
          SC_Event_DTC_0x11571e_ResetEventStatus: operation=Event_DTC_0x11571e.ResetEventStatus
          SC_Event_DTC_0x11571e_SetEventStatus: operation=Event_DTC_0x11571e.SetEventStatus
          SC_Event_DTC_0x115816_GetDTCOfEvent: operation=Event_DTC_0x115816.GetDTCOfEvent
          SC_Event_DTC_0x115816_GetEventExtendedDataRecordEx: operation=Event_DTC_0x115816.GetEventExtendedDataRecordEx
          SC_Event_DTC_0x115816_GetEventFailed: operation=Event_DTC_0x115816.GetEventFailed
          SC_Event_DTC_0x115816_GetEventFreezeFrameDataEx: operation=Event_DTC_0x115816.GetEventFreezeFrameDataEx
          SC_Event_DTC_0x115816_GetEventStatus: operation=Event_DTC_0x115816.GetEventStatus
          SC_Event_DTC_0x115816_GetEventTested: operation=Event_DTC_0x115816.GetEventTested
          SC_Event_DTC_0x115816_GetEventUdsStatus: operation=Event_DTC_0x115816.GetEventUdsStatus
          SC_Event_DTC_0x115816_GetFaultDetectionCounter: operation=Event_DTC_0x115816.GetFaultDetectionCounter
          SC_Event_DTC_0x115816_ResetEventDebounceStatus: operation=Event_DTC_0x115816.ResetEventDebounceStatus
          SC_Event_DTC_0x115816_ResetEventStatus: operation=Event_DTC_0x115816.ResetEventStatus
          SC_Event_DTC_0x115816_SetEventStatus: operation=Event_DTC_0x115816.SetEventStatus
          SC_Event_DTC_0x908017_GetDTCOfEvent: operation=Event_DTC_0x908017.GetDTCOfEvent
          SC_Event_DTC_0x908017_GetEventExtendedDataRecordEx: operation=Event_DTC_0x908017.GetEventExtendedDataRecordEx
          SC_Event_DTC_0x908017_GetEventFailed: operation=Event_DTC_0x908017.GetEventFailed
          SC_Event_DTC_0x908017_GetEventFreezeFrameDataEx: operation=Event_DTC_0x908017.GetEventFreezeFrameDataEx
          SC_Event_DTC_0x908017_GetEventStatus: operation=Event_DTC_0x908017.GetEventStatus
          SC_Event_DTC_0x908017_GetEventTested: operation=Event_DTC_0x908017.GetEventTested
          SC_Event_DTC_0x908017_GetEventUdsStatus: operation=Event_DTC_0x908017.GetEventUdsStatus
          SC_Event_DTC_0x908017_GetFaultDetectionCounter: operation=Event_DTC_0x908017.GetFaultDetectionCounter
          SC_Event_DTC_0x908017_ResetEventDebounceStatus: operation=Event_DTC_0x908017.ResetEventDebounceStatus
          SC_Event_DTC_0x908017_ResetEventStatus: operation=Event_DTC_0x908017.ResetEventStatus
          SC_Event_DTC_0x908017_SetEventStatus: operation=Event_DTC_0x908017.SetEventStatus
          SC_Event_DTC_0x908116_GetDTCOfEvent: operation=Event_DTC_0x908116.GetDTCOfEvent
          SC_Event_DTC_0x908116_GetEventExtendedDataRecordEx: operation=Event_DTC_0x908116.GetEventExtendedDataRecordEx
          SC_Event_DTC_0x908116_GetEventFailed: operation=Event_DTC_0x908116.GetEventFailed
          SC_Event_DTC_0x908116_GetEventFreezeFrameDataEx: operation=Event_DTC_0x908116.GetEventFreezeFrameDataEx
          SC_Event_DTC_0x908116_GetEventStatus: operation=Event_DTC_0x908116.GetEventStatus
          SC_Event_DTC_0x908116_GetEventTested: operation=Event_DTC_0x908116.GetEventTested
          SC_Event_DTC_0x908116_GetEventUdsStatus: operation=Event_DTC_0x908116.GetEventUdsStatus
          SC_Event_DTC_0x908116_GetFaultDetectionCounter: operation=Event_DTC_0x908116.GetFaultDetectionCounter
          SC_Event_DTC_0x908116_ResetEventDebounceStatus: operation=Event_DTC_0x908116.ResetEventDebounceStatus
          SC_Event_DTC_0x908116_ResetEventStatus: operation=Event_DTC_0x908116.ResetEventStatus
          SC_Event_DTC_0x908116_SetEventStatus: operation=Event_DTC_0x908116.SetEventStatus
          SC_Event_DTC_0xc10387_GetDTCOfEvent: operation=Event_DTC_0xc10387.GetDTCOfEvent
          SC_Event_DTC_0xc10387_GetEventExtendedDataRecordEx: operation=Event_DTC_0xc10387.GetEventExtendedDataRecordEx
          SC_Event_DTC_0xc10387_GetEventFailed: operation=Event_DTC_0xc10387.GetEventFailed
          SC_Event_DTC_0xc10387_GetEventFreezeFrameDataEx: operation=Event_DTC_0xc10387.GetEventFreezeFrameDataEx
          SC_Event_DTC_0xc10387_GetEventStatus: operation=Event_DTC_0xc10387.GetEventStatus
          SC_Event_DTC_0xc10387_GetEventTested: operation=Event_DTC_0xc10387.GetEventTested
          SC_Event_DTC_0xc10387_GetEventUdsStatus: operation=Event_DTC_0xc10387.GetEventUdsStatus
          SC_Event_DTC_0xc10387_GetFaultDetectionCounter: operation=Event_DTC_0xc10387.GetFaultDetectionCounter
          SC_Event_DTC_0xc10387_ResetEventDebounceStatus: operation=Event_DTC_0xc10387.ResetEventDebounceStatus
          SC_Event_DTC_0xc10387_ResetEventStatus: operation=Event_DTC_0xc10387.ResetEventStatus
          SC_Event_DTC_0xc10387_SetEventStatus: operation=Event_DTC_0xc10387.SetEventStatus
          SC_Event_DTC_0xc11087_GetDTCOfEvent: operation=Event_DTC_0xc11087.GetDTCOfEvent
          SC_Event_DTC_0xc11087_GetEventExtendedDataRecordEx: operation=Event_DTC_0xc11087.GetEventExtendedDataRecordEx
          SC_Event_DTC_0xc11087_GetEventFailed: operation=Event_DTC_0xc11087.GetEventFailed
          SC_Event_DTC_0xc11087_GetEventFreezeFrameDataEx: operation=Event_DTC_0xc11087.GetEventFreezeFrameDataEx
          SC_Event_DTC_0xc11087_GetEventStatus: operation=Event_DTC_0xc11087.GetEventStatus
          SC_Event_DTC_0xc11087_GetEventTested: operation=Event_DTC_0xc11087.GetEventTested
          SC_Event_DTC_0xc11087_GetEventUdsStatus: operation=Event_DTC_0xc11087.GetEventUdsStatus
          SC_Event_DTC_0xc11087_GetFaultDetectionCounter: operation=Event_DTC_0xc11087.GetFaultDetectionCounter
          SC_Event_DTC_0xc11087_ResetEventDebounceStatus: operation=Event_DTC_0xc11087.ResetEventDebounceStatus
          SC_Event_DTC_0xc11087_ResetEventStatus: operation=Event_DTC_0xc11087.ResetEventStatus
          SC_Event_DTC_0xc11087_SetEventStatus: operation=Event_DTC_0xc11087.SetEventStatus
          SC_Event_DTC_0xc11187_GetDTCOfEvent: operation=Event_DTC_0xc11187.GetDTCOfEvent
          SC_Event_DTC_0xc11187_GetEventExtendedDataRecordEx: operation=Event_DTC_0xc11187.GetEventExtendedDataRecordEx
          SC_Event_DTC_0xc11187_GetEventFailed: operation=Event_DTC_0xc11187.GetEventFailed
          SC_Event_DTC_0xc11187_GetEventFreezeFrameDataEx: operation=Event_DTC_0xc11187.GetEventFreezeFrameDataEx
          SC_Event_DTC_0xc11187_GetEventStatus: operation=Event_DTC_0xc11187.GetEventStatus
          SC_Event_DTC_0xc11187_GetEventTested: operation=Event_DTC_0xc11187.GetEventTested
          SC_Event_DTC_0xc11187_GetEventUdsStatus: operation=Event_DTC_0xc11187.GetEventUdsStatus
          SC_Event_DTC_0xc11187_GetFaultDetectionCounter: operation=Event_DTC_0xc11187.GetFaultDetectionCounter
          SC_Event_DTC_0xc11187_ResetEventDebounceStatus: operation=Event_DTC_0xc11187.ResetEventDebounceStatus
          SC_Event_DTC_0xc11187_ResetEventStatus: operation=Event_DTC_0xc11187.ResetEventStatus
          SC_Event_DTC_0xc11187_SetEventStatus: operation=Event_DTC_0xc11187.SetEventStatus
          SC_Event_DTC_0xc12987_GetDTCOfEvent: operation=Event_DTC_0xc12987.GetDTCOfEvent
          SC_Event_DTC_0xc12987_GetEventExtendedDataRecordEx: operation=Event_DTC_0xc12987.GetEventExtendedDataRecordEx
          SC_Event_DTC_0xc12987_GetEventFailed: operation=Event_DTC_0xc12987.GetEventFailed
          SC_Event_DTC_0xc12987_GetEventFreezeFrameDataEx: operation=Event_DTC_0xc12987.GetEventFreezeFrameDataEx
          SC_Event_DTC_0xc12987_GetEventStatus: operation=Event_DTC_0xc12987.GetEventStatus
          SC_Event_DTC_0xc12987_GetEventTested: operation=Event_DTC_0xc12987.GetEventTested
          SC_Event_DTC_0xc12987_GetEventUdsStatus: operation=Event_DTC_0xc12987.GetEventUdsStatus
          SC_Event_DTC_0xc12987_GetFaultDetectionCounter: operation=Event_DTC_0xc12987.GetFaultDetectionCounter
          SC_Event_DTC_0xc12987_ResetEventDebounceStatus: operation=Event_DTC_0xc12987.ResetEventDebounceStatus
          SC_Event_DTC_0xc12987_ResetEventStatus: operation=Event_DTC_0xc12987.ResetEventStatus
          SC_Event_DTC_0xc12987_SetEventStatus: operation=Event_DTC_0xc12987.SetEventStatus
          SC_Event_DTC_0xc14087_GetDTCOfEvent: operation=Event_DTC_0xc14087.GetDTCOfEvent
          SC_Event_DTC_0xc14087_GetEventExtendedDataRecordEx: operation=Event_DTC_0xc14087.GetEventExtendedDataRecordEx
          SC_Event_DTC_0xc14087_GetEventFailed: operation=Event_DTC_0xc14087.GetEventFailed
          SC_Event_DTC_0xc14087_GetEventFreezeFrameDataEx: operation=Event_DTC_0xc14087.GetEventFreezeFrameDataEx
          SC_Event_DTC_0xc14087_GetEventStatus: operation=Event_DTC_0xc14087.GetEventStatus
          SC_Event_DTC_0xc14087_GetEventTested: operation=Event_DTC_0xc14087.GetEventTested
          SC_Event_DTC_0xc14087_GetEventUdsStatus: operation=Event_DTC_0xc14087.GetEventUdsStatus
          SC_Event_DTC_0xc14087_GetFaultDetectionCounter: operation=Event_DTC_0xc14087.GetFaultDetectionCounter
          SC_Event_DTC_0xc14087_ResetEventDebounceStatus: operation=Event_DTC_0xc14087.ResetEventDebounceStatus
          SC_Event_DTC_0xc14087_ResetEventStatus: operation=Event_DTC_0xc14087.ResetEventStatus
          SC_Event_DTC_0xc14087_SetEventStatus: operation=Event_DTC_0xc14087.SetEventStatus
          SC_Event_DTC_0xc14787_GetDTCOfEvent: operation=Event_DTC_0xc14787.GetDTCOfEvent
          SC_Event_DTC_0xc14787_GetEventExtendedDataRecordEx: operation=Event_DTC_0xc14787.GetEventExtendedDataRecordEx
          SC_Event_DTC_0xc14787_GetEventFailed: operation=Event_DTC_0xc14787.GetEventFailed
          SC_Event_DTC_0xc14787_GetEventFreezeFrameDataEx: operation=Event_DTC_0xc14787.GetEventFreezeFrameDataEx
          SC_Event_DTC_0xc14787_GetEventStatus: operation=Event_DTC_0xc14787.GetEventStatus
          SC_Event_DTC_0xc14787_GetEventTested: operation=Event_DTC_0xc14787.GetEventTested
          SC_Event_DTC_0xc14787_GetEventUdsStatus: operation=Event_DTC_0xc14787.GetEventUdsStatus
          SC_Event_DTC_0xc14787_GetFaultDetectionCounter: operation=Event_DTC_0xc14787.GetFaultDetectionCounter
          SC_Event_DTC_0xc14787_ResetEventDebounceStatus: operation=Event_DTC_0xc14787.ResetEventDebounceStatus
          SC_Event_DTC_0xc14787_ResetEventStatus: operation=Event_DTC_0xc14787.ResetEventStatus
          SC_Event_DTC_0xc14787_SetEventStatus: operation=Event_DTC_0xc14787.SetEventStatus
          SC_Event_DTC_0xc16687_GetDTCOfEvent: operation=Event_DTC_0xc16687.GetDTCOfEvent
          SC_Event_DTC_0xc16687_GetEventExtendedDataRecordEx: operation=Event_DTC_0xc16687.GetEventExtendedDataRecordEx
          SC_Event_DTC_0xc16687_GetEventFailed: operation=Event_DTC_0xc16687.GetEventFailed
          SC_Event_DTC_0xc16687_GetEventFreezeFrameDataEx: operation=Event_DTC_0xc16687.GetEventFreezeFrameDataEx
          SC_Event_DTC_0xc16687_GetEventStatus: operation=Event_DTC_0xc16687.GetEventStatus
          SC_Event_DTC_0xc16687_GetEventTested: operation=Event_DTC_0xc16687.GetEventTested
          SC_Event_DTC_0xc16687_GetEventUdsStatus: operation=Event_DTC_0xc16687.GetEventUdsStatus
          SC_Event_DTC_0xc16687_GetFaultDetectionCounter: operation=Event_DTC_0xc16687.GetFaultDetectionCounter
          SC_Event_DTC_0xc16687_ResetEventDebounceStatus: operation=Event_DTC_0xc16687.ResetEventDebounceStatus
          SC_Event_DTC_0xc16687_ResetEventStatus: operation=Event_DTC_0xc16687.ResetEventStatus
          SC_Event_DTC_0xc16687_SetEventStatus: operation=Event_DTC_0xc16687.SetEventStatus
          SC_Event_DTC_0xc19687_GetDTCOfEvent: operation=Event_DTC_0xc19687.GetDTCOfEvent
          SC_Event_DTC_0xc19687_GetEventExtendedDataRecordEx: operation=Event_DTC_0xc19687.GetEventExtendedDataRecordEx
          SC_Event_DTC_0xc19687_GetEventFailed: operation=Event_DTC_0xc19687.GetEventFailed
          SC_Event_DTC_0xc19687_GetEventFreezeFrameDataEx: operation=Event_DTC_0xc19687.GetEventFreezeFrameDataEx
          SC_Event_DTC_0xc19687_GetEventStatus: operation=Event_DTC_0xc19687.GetEventStatus
          SC_Event_DTC_0xc19687_GetEventTested: operation=Event_DTC_0xc19687.GetEventTested
          SC_Event_DTC_0xc19687_GetEventUdsStatus: operation=Event_DTC_0xc19687.GetEventUdsStatus
          SC_Event_DTC_0xc19687_GetFaultDetectionCounter: operation=Event_DTC_0xc19687.GetFaultDetectionCounter
          SC_Event_DTC_0xc19687_ResetEventDebounceStatus: operation=Event_DTC_0xc19687.ResetEventDebounceStatus
          SC_Event_DTC_0xc19687_ResetEventStatus: operation=Event_DTC_0xc19687.ResetEventStatus
          SC_Event_DTC_0xc19687_SetEventStatus: operation=Event_DTC_0xc19687.SetEventStatus
